VERSION "HNPBNNNYNNNNNNNNNNNNNNNNNNNNNNNNYNYYYYYYYY>4>%%%/4>'%**4YYY///"

NS_ :

BS_:

BU_: TPM TCM SCCM RF_HUB PTS ORC IC HaLF ETM ESM ESC EPS ECM Diagnost DTCM DASM CBC AFLS ADCM

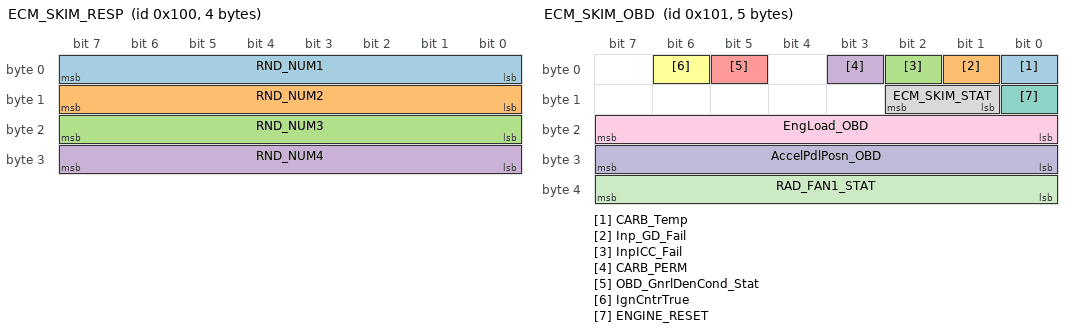
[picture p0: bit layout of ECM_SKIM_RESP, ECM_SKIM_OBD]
BO_ 256 ECM_SKIM_RESP: 4 ECM
 SG_ RND_NUM1 : 0|8@1+ (1,0) [0|0] ""  RF_HUB
 SG_ RND_NUM2 : 8|8@1+ (1,0) [0|0] ""  RF_HUB
 SG_ RND_NUM3 : 16|8@1+ (1,0) [0|0] ""  RF_HUB
 SG_ RND_NUM4 : 24|8@1+ (1,0) [0|0] ""  RF_HUB

BO_ 257 ECM_SKIM_OBD: 5 ECM
 SG_ CARB_Temp : 0|1@1+ (1,0) [0|0] ""  TCM,ECM
 SG_ Inp_GD_Fail : 1|1@1+ (1,0) [0|0] ""  TCM,ECM
 SG_ InpICC_Fail : 2|1@1+ (1,0) [0|0] ""  TCM,ECM
 SG_ CARB_PERM : 3|1@1+ (1,0) [0|0] ""  TCM
 SG_ OBD_GnrlDenCond_Stat : 5|1@1+ (1,0) [0|0] ""  TCM,ECM
 SG_ IgnCntrTrue : 6|1@1+ (1,0) [0|0] ""  TCM,ECM
 SG_ ENGINE_RESET : 8|1@1+ (1,0) [0|0] ""  RF_HUB
 SG_ ECM_SKIM_STAT : 9|2@1+ (1,0) [0|0] ""  RF_HUB
 SG_ EngLoad_OBD : 16|8@1+ (0.3922,0) [0|100] "%"  TCM,ECM
 SG_ AccelPdlPosn_OBD : 24|8@1+ (0.3922,0) [0|100] "%"  TCM,ECM
 SG_ RAD_FAN1_STAT : 32|8@1+ (1,0) [0|100] "%"  ETM,ECM

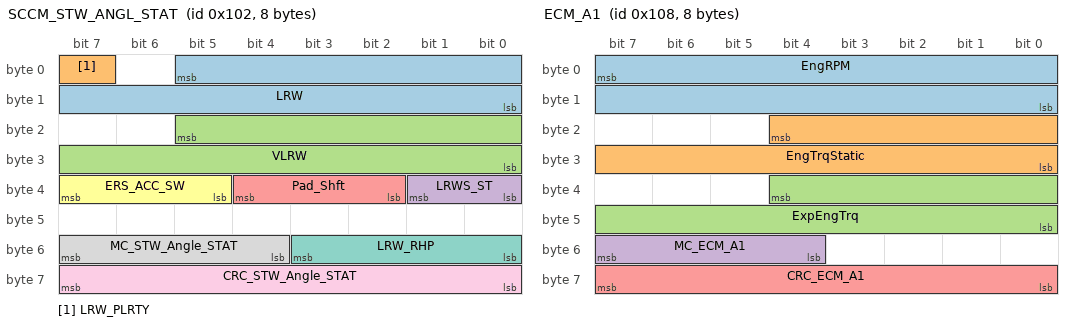
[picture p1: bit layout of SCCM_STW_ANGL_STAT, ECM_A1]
BO_ 258 SCCM_STW_ANGL_STAT: 8 SCCM
 SG_ LRW : 5|14@0+ (0.5,-2048) [-2048|2047] "Degrees"  HaLF,ORC,ADCM,DTCM,TCM,ECM,DASM,ESC,EPS,AFLS,PTS,IC,CBC
 SG_ LRW_PLRTY : 7|1@1+ (1,0) [0|0] ""  ETM,HaLF,ORC,ECM,DASM,ESC,AFLS,IC
 SG_ VLRW : 21|14@0+ (0.5,-2048) [-2048|2047] "°/s"  ETM,HaLF,ORC,ADCM,DTCM,ECM,DASM,ESC,EPS,AFLS
 SG_ LRWS_ST : 32|2@1+ (1,0) [0|0] ""  ETM,HaLF,ORC,ADCM,DTCM,ECM,DASM,ESC,AFLS,CBC
 SG_ Pad_Shft : 34|3@1+ (1,0) [0|0] ""  ETM,TCM,ECM
 SG_ ERS_ACC_SW : 37|3@1+ (1,0) [0|0] ""  TCM
 SG_ LRW_RHP : 48|4@1+ (0.1,-0.4) [-0.4|0.4] "Degrees"  ETM,ECM,EPS
 SG_ MC_STW_Angle_STAT : 52|4@1+ (1,0) [0|15] ""  ETM,ORC,ECM,DASM,ESC
 SG_ CRC_STW_Angle_STAT : 56|8@1+ (1,0) [0|0] ""  ETM,ORC,ECM,DASM,ESC

BO_ 264 ECM_A1: 8 ECM
 SG_ EngRPM : 7|16@0+ (1,0) [0|65534] "rpm"  HaLF,ORC,ADCM,DTCM,TCM,ECM,DASM,ESC,EPS,AFLS,TPM,PTS,IC,CBC,RF_HUB
 SG_ EngTrqStatic : 20|13@0+ (0.25,-500) [-500|1547.5] "Nm"  ADCM,DTCM,TCM,ECM,DASM,ESC,IC,CBC
 SG_ ExpEngTrq : 36|13@0+ (0.25,-500) [-500|1547.5] "Nm"  TCM,DASM,ESC
 SG_ MC_ECM_A1 : 52|4@1+ (1,0) [0|15] ""  HaLF,TCM,DASM,ESC
 SG_ CRC_ECM_A1 : 56|8@1+ (1,0) [0|0] ""  HaLF,TCM,DASM,ESC

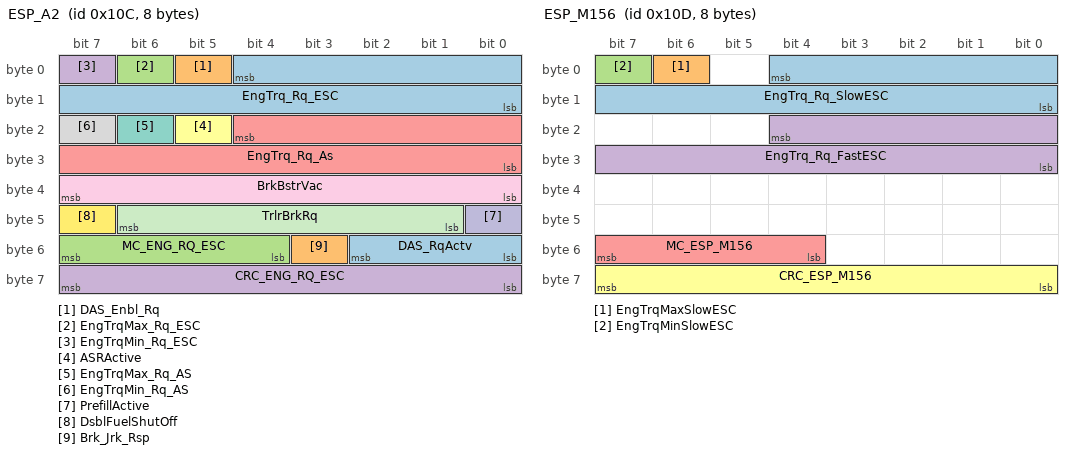
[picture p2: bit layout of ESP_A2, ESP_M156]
BO_ 268 ESP_A2: 8 ESC
 SG_ EngTrq_Rq_ESC : 4|13@0+ (0.25,-500) [-500|1547.5] "Nm"  ETM,ECM,DASM
 SG_ DAS_Enbl_Rq : 5|1@1+ (1,0) [0|0] ""  ORC,TCM,ECM,DASM
 SG_ EngTrqMax_Rq_ESC : 6|1@1+ (1,0) [0|0] ""  TCM,ECM
 SG_ EngTrqMin_Rq_ESC : 7|1@1+ (1,0) [0|0] ""  DTCM,TCM,ECM
 SG_ EngTrq_Rq_As : 20|13@0+ (0.25,-500) [-500|1547.5] "Nm"  ORC,TCM,ECM,DASM
 SG_ ASRActive : 21|1@1+ (1,0) [0|0] ""  ECM,DASM
 SG_ EngTrqMax_Rq_AS : 22|1@1+ (1,0) [0|0] ""  TCM,ECM,DASM
 SG_ EngTrqMin_Rq_AS : 23|1@1+ (1,0) [0|0] ""  TCM,ECM,DASM
 SG_ BrkBstrVac : 32|8@1+ (0.55,-119.7) [-119.7|20] "kPa"  ORC,ECM
 SG_ PrefillActive : 40|1@1+ (1,0) [0|0] ""  DASM
 SG_ TrlrBrkRq : 41|6@1+ (2,0) [0|100] "%" Vector__XXX
 SG_ DsblFuelShutOff : 47|1@1+ (1,0) [0|0] ""  ECM
 SG_ DAS_RqActv : 48|3@1+ (1,0) [0|0] ""  ORC,DASM
 SG_ Brk_Jrk_Rsp : 51|1@1+ (1,0) [0|0] ""  ORC,DASM
 SG_ MC_ENG_RQ_ESC : 52|4@1+ (1,0) [0|15] ""  TCM,ECM,DASM
 SG_ CRC_ENG_RQ_ESC : 56|8@1+ (1,0) [0|0] ""  TCM,ECM,DASM

BO_ 269 ESP_M156: 8 Vector__XXX
 SG_ EngTrq_Rq_SlowESC : 4|13@0+ (0.25,-500) [-500|1547.5] "Nm"  TCM
 SG_ EngTrqMaxSlowESC : 6|1@1+ (1,0) [0|0] ""  TCM
 SG_ EngTrqMinSlowESC : 7|1@1+ (1,0) [0|0] ""  TCM
 SG_ EngTrq_Rq_FastESC : 20|13@0+ (0.25,-500) [-500|1547.5] "Nm"  TCM
 SG_ MC_ESP_M156 : 52|4@1+ (1,0) [0|15] ""  TCM
 SG_ CRC_ESP_M156 : 56|8@1+ (1,0) [0|0] ""  TCM

BO_ 272 SKIM_110h: 6 RF_HUB
 SG_ SEED_REQUEST : 0|1@1+ (1,0) [0|0] ""  ECM

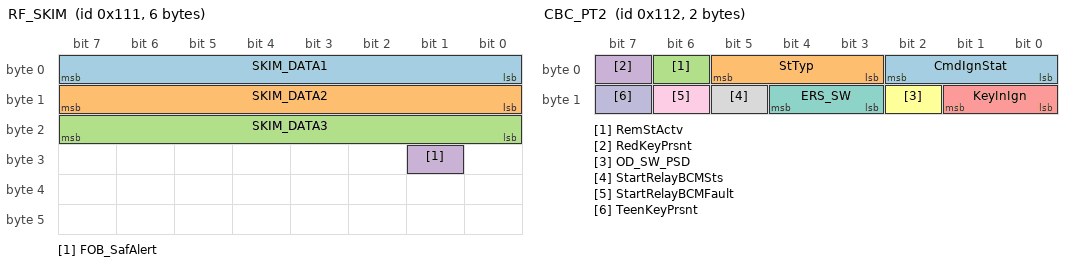
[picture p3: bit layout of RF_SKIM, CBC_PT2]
BO_ 273 RF_SKIM: 6 RF_HUB
 SG_ SKIM_DATA1 : 0|8@1+ (1,0) [0|0] ""  ECM
 SG_ SKIM_DATA2 : 8|8@1+ (1,0) [0|0] ""  ECM
 SG_ SKIM_DATA3 : 16|8@1+ (1,0) [0|0] ""  ECM
 SG_ FOB_SafAlert : 25|1@1+ (1,0) [0|0] ""  CBC

BO_ 274 CBC_PT2: 2 CBC
 SG_ CmdIgnStat : 0|3@1+ (1,0) [0|0] ""  HaLF,ORC,ADCM,DTCM,ESM,TCM,ECM,DASM,ESC,SCCM,EPS,AFLS,TPM,PTS,IC,RF_HUB
 SG_ StTyp : 3|3@1+ (1,0) [0|0] ""  ORC,DTCM,ECM,SCCM,TPM,PTS,IC,RF_HUB
 SG_ RemStActv : 6|1@1+ (1,0) [0|0] ""  ORC,DTCM,ESM,TCM,ECM,SCCM,TPM,PTS,IC,RF_HUB
 SG_ RedKeyPrsnt : 7|1@1+ (1,0) [0|0] ""  ETM,ECM
 SG_ KeyInIgn : 8|2@1+ (1,0) [0|0] ""  ORC,SCCM,TPM,PTS,IC,RF_HUB
 SG_ OD_SW_PSD : 10|1@1+ (1,0) [0|0] ""  TCM,ECM,PTS
 SG_ ERS_SW : 11|2@1+ (1,0) [0|0] ""  ECM
 SG_ StartRelayBCMSts : 13|1@1+ (1,0) [0|0] ""  ECM
 SG_ StartRelayBCMFault : 14|1@1+ (1,0) [0|0] ""  ORC,ECM
 SG_ TeenKeyPrsnt : 15|1@1+ (1,0) [0|0] ""  ETM,ECM

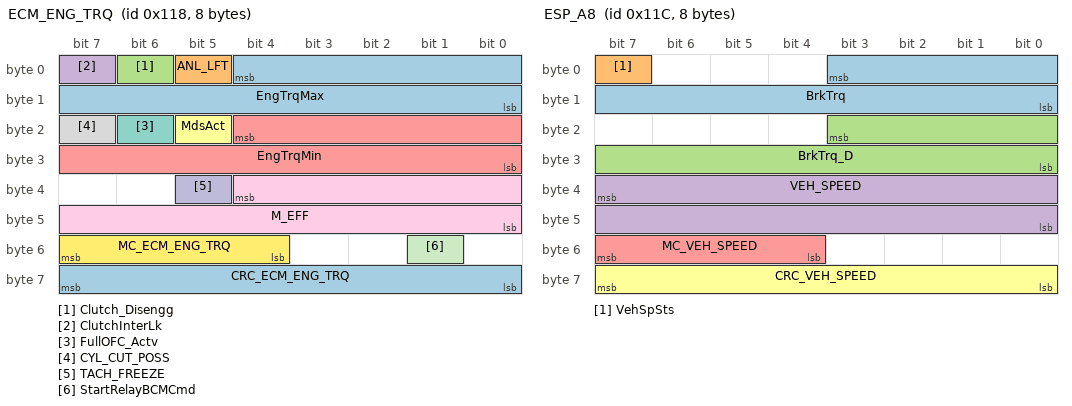
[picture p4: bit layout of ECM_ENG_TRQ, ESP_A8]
BO_ 280 ECM_ENG_TRQ: 8 ECM
 SG_ EngTrqMax : 4|13@0+ (0.25,-500) [-500|1547.5] "Nm"  DTCM,TCM,DASM,ESC,IC
 SG_ ANL_LFT : 5|1@1+ (1,0) [0|0] ""  TCM,CBC
 SG_ Clutch_Disengg : 6|1@1+ (1,0) [0|0] ""  ORC,ESC,PTS,CBC
 SG_ ClutchInterLk : 7|1@1+ (1,0) [0|0] ""  ORC,DTCM,ESC,RF_HUB
 SG_ EngTrqMin : 20|13@0+ (0.25,-500) [-500|1547.5] "Nm"  DTCM,TCM,DASM,ESC,IC
 SG_ MdsAct : 21|1@1+ (1,0) [0|0] ""  TCM,IC
 SG_ FullOFC_Actv : 22|1@1+ (1,0) [0|0] ""  DASM,ESC,CBC
 SG_ CYL_CUT_POSS : 23|1@1+ (1,0) [0|0] "" Vector__XXX
 SG_ M_EFF : 36|13@0+ (0.25,-500) [-500|1547.5] "Nm" Vector__XXX
 SG_ TACH_FREEZE : 37|1@1+ (1,0) [0|0] ""  IC
 SG_ StartRelayBCMCmd : 49|1@1+ (1,0) [0|0] ""  CBC
 SG_ MC_ECM_ENG_TRQ : 52|4@1+ (1,0) [0|15] ""  ESC
 SG_ CRC_ECM_ENG_TRQ : 56|8@1+ (1,0) [0|0] ""  DASM,ESC

BO_ 284 ESP_A8: 8 ESC
 SG_ BrkTrq : 3|12@0+ (3,0) [0|12282] "Nm"  ADCM,TCM,ECM,DASM,CBC,RF_HUB
 SG_ VehSpSts : 7|1@1+ (1,0) [0|0] ""  DASM
 SG_ BrkTrq_D : 19|12@0+ (3,0) [0|12282] "Nm"  ADCM,ECM,DASM,RF_HUB
 SG_ VEH_SPEED : 39|16@0+ (0.0078125,0) [0|511.984375] "km/h"  HaLF,ORC,ADCM,DTCM,ESM,TCM,ECM,DASM,EPS,AFLS,TPM,PTS,IC,CBC,RF_HUB
 SG_ MC_VEH_SPEED : 52|4@1+ (1,0) [0|15] ""  EPS,HaLF,ORC,ESM,TCM,ECM,DASM,TPM,PTS,IC,CBC,RF_HUB
 SG_ CRC_VEH_SPEED : 56|8@1+ (1,0) [0|0] ""  EPS,HaLF,ORC,ESM,TCM,ECM,DASM,TPM,PTS,IC,CBC,RF_HUB

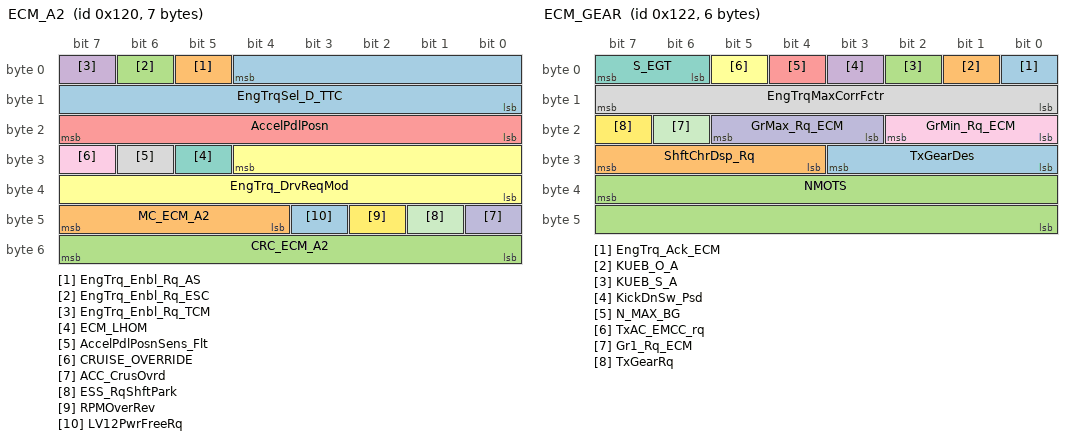
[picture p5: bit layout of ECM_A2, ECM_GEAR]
BO_ 288 ECM_A2: 7 ECM
 SG_ EngTrqSel_D_TTC : 4|13@0+ (0.25,-500) [-500|1547.5] "Nm"  TCM,DASM,ESC
 SG_ EngTrq_Enbl_Rq_AS : 5|1@1+ (1,0) [0|0] ""  TCM,DASM,ESC
 SG_ EngTrq_Enbl_Rq_ESC : 6|1@1+ (1,0) [0|0] ""  TCM,DASM,ESC
 SG_ EngTrq_Enbl_Rq_TCM : 7|1@1+ (1,0) [0|0] ""  TCM
 SG_ AccelPdlPosn : 16|8@1+ (0.4,0) [0|100] "%"  ETM,HaLF,ADCM,DTCM,TCM,ECM,DASM,ESC,AFLS,CBC
 SG_ EngTrq_DrvReqMod : 28|13@0+ (0.25,-500) [-500|1547.5] "Nm"  TCM,ECM,ESC
 SG_ ECM_LHOM : 29|1@1+ (1,0) [0|0] ""  TCM
 SG_ AccelPdlPosnSens_Flt : 30|1@1+ (1,0) [0|0] ""  HaLF,TCM,DASM,ESC,CBC
 SG_ CRUISE_OVERRIDE : 31|1@1+ (1,0) [0|0] ""  TCM,ECM,DASM,ESC,IC
 SG_ ACC_CrusOvrd : 40|1@1+ (1,0) [0|0] ""  DASM,ESC
 SG_ ESS_RqShftPark : 41|1@1+ (1,0) [0|0] ""  TCM
 SG_ RPMOverRev : 42|1@1+ (1,0) [0|0] ""  DASM
 SG_ LV12PwrFreeRq : 43|1@1+ (1,0) [0|0] ""  TCM,DASM,ESC
 SG_ MC_ECM_A2 : 44|4@1+ (1,0) [0|15] ""  HaLF,TCM,DASM,ESC
 SG_ CRC_ECM_A2 : 48|8@1+ (1,0) [0|0] ""  HaLF,TCM,DASM,ESC

BO_ 290 ECM_GEAR: 6 ECM
 SG_ EngTrq_Ack_ECM : 0|1@1+ (1,0) [0|0] "" Vector__XXX
 SG_ KUEB_O_A : 1|1@1+ (1,0) [0|0] "" Vector__XXX
 SG_ KUEB_S_A : 2|1@1+ (1,0) [0|0] "" Vector__XXX
 SG_ KickDnSw_Psd : 3|1@1+ (1,0) [0|0] ""  TCM,DASM,ESC
 SG_ N_MAX_BG : 4|1@1+ (1,0) [0|0] "" Vector__XXX
 SG_ TxAC_EMCC_rq : 5|1@1+ (1,0) [0|0] ""  TCM
 SG_ S_EGT : 6|2@1+ (1,0) [0|0] "" Vector__XXX
 SG_ EngTrqMaxCorrFctr : 8|8@1+ (0.0078,0) [0|1.98] "Nm"  TCM,DASM
 SG_ GrMin_Rq_ECM : 16|3@1+ (1,0) [0|0] ""  TCM,ECM
 SG_ GrMax_Rq_ECM : 19|3@1+ (1,0) [0|0] ""  TCM
 SG_ Gr1_Rq_ECM : 22|1@1+ (1,0) [0|0] "" Vector__XXX
 SG_ TxGearRq : 23|1@1+ (1,0) [0|0] "" Vector__XXX
 SG_ TxGearDes : 24|4@1+ (1,0) [0|0] "" Vector__XXX
 SG_ ShftChrDsp_Rq : 28|4@1+ (1,0) [0|0] ""  ECM
 SG_ NMOTS : 39|16@0+ (1,0) [0|65534] "rpm"  TCM,ESC

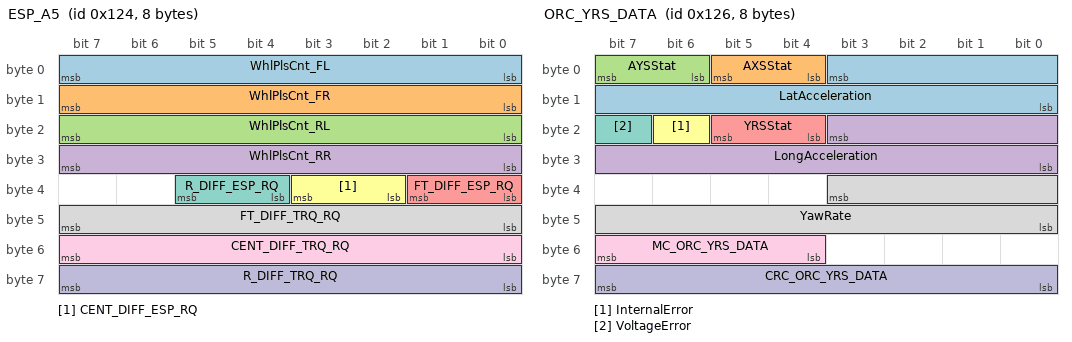
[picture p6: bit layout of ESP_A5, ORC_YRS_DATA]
BO_ 292 ESP_A5: 8 ESC
 SG_ WhlPlsCnt_FL : 0|8@1+ (1,0) [0|254] "Impulse"  DASM,EPS,TPM,IC,CBC,RF_HUB
 SG_ WhlPlsCnt_FR : 8|8@1+ (1,0) [0|254] "Impulse"  DASM,EPS,TPM,IC,CBC,RF_HUB
 SG_ WhlPlsCnt_RL : 16|8@1+ (1,0) [0|254] "Impulse"  DASM,EPS,TPM,IC,CBC,RF_HUB
 SG_ WhlPlsCnt_RR : 24|8@1+ (1,0) [0|254] "Impulse"  DASM,EPS,TPM,IC,CBC,RF_HUB
 SG_ FT_DIFF_ESP_RQ : 32|2@1+ (1,0) [0|0] "" Vector__XXX
 SG_ CENT_DIFF_ESP_RQ : 34|2@1+ (1,0) [0|0] ""  DTCM
 SG_ R_DIFF_ESP_RQ : 36|2@1+ (1,0) [0|0] "" Vector__XXX
 SG_ FT_DIFF_TRQ_RQ : 40|8@1+ (10,0) [0|2540] "Nm" Vector__XXX
 SG_ CENT_DIFF_TRQ_RQ : 48|8@1+ (10,0) [0|2540] "Nm"  DTCM
 SG_ R_DIFF_TRQ_RQ : 56|8@1+ (10,0) [0|2540] "Nm" Vector__XXX

BO_ 294 ORC_YRS_DATA: 8 Vector__XXX
 SG_ LatAcceleration : 3|12@0+ (0.02,-40.96) [-40.96|40.92] "m/s²"  ESC
 SG_ AXSStat : 4|2@1+ (1,0) [0|0] ""  ECM,ESC
 SG_ AYSStat : 6|2@1+ (1,0) [0|0] ""  ESC
 SG_ LongAcceleration : 19|12@0+ (0.02,-40.96) [-40.96|40.92] "m/s²"  EPS,ECM,ESC
 SG_ YRSStat : 20|2@1+ (1,0) [0|0] ""  ESC
 SG_ InternalError : 22|1@1+ (1,0) [0|0] ""  ESC
 SG_ VoltageError : 23|1@1+ (1,0) [0|0] ""  ESC
 SG_ YawRate : 35|12@0+ (0.08,-163.84) [-163.84|163.68] "°/s"  ESC
 SG_ MC_ORC_YRS_DATA : 52|4@1+ (1,0) [0|15] ""  ESC
 SG_ CRC_ORC_YRS_DATA : 56|8@1+ (1,0) [0|0] ""  ESC

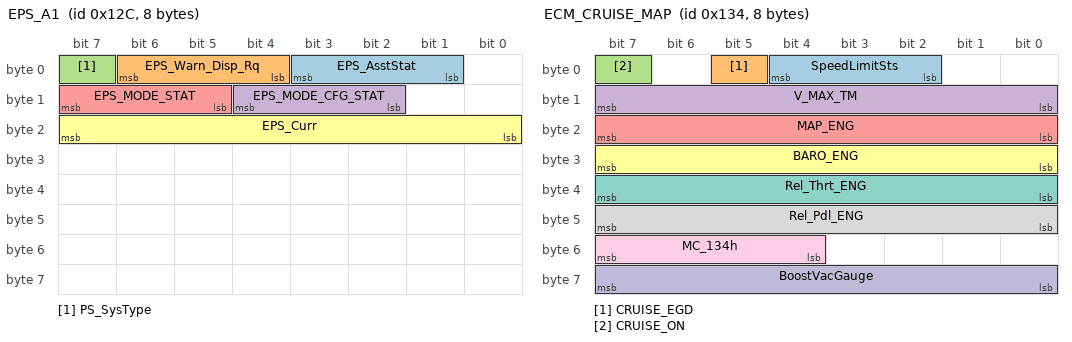
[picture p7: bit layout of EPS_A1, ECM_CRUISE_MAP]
BO_ 300 EPS_A1: 8 EPS
 SG_ EPS_AsstStat : 1|3@1+ (1,0) [0|0] ""  ORC,ECM,ESC,IC
 SG_ EPS_Warn_Disp_Rq : 4|3@1+ (1,0) [0|0] ""  ORC,ECM,ESC,IC,CBC
 SG_ PS_SysType : 7|1@1+ (1,0) [0|0] ""  ESC,IC,CBC
 SG_ EPS_MODE_CFG_STAT : 10|3@1+ (1,0) [0|0] ""  CBC
 SG_ EPS_MODE_STAT : 13|3@1+ (1,0) [0|0] ""  CBC
 SG_ EPS_Curr : 16|8@1+ (1,-50) [-50|204] "Amp"  ECM

BO_ 308 ECM_CRUISE_MAP: 8 ECM
 SG_ SpeedLimitSts : 2|3@1+ (1,0) [0|0] ""  IC
 SG_ CRUISE_EGD : 5|1@1+ (1,0) [0|0] ""  ORC,TCM,ECM,ESC,IC,CBC
 SG_ CRUISE_ON : 7|1@1+ (1,0) [0|0] ""  ORC,TCM,ESC,SCCM,IC
 SG_ V_MAX_TM : 8|8@1+ (1,0) [0|250] "km/h(mph)"  TCM,ECM
 SG_ MAP_ENG : 16|8@1+ (0.8,0) [0|203.2] "kPa"  ETM,ECM,ESC
 SG_ BARO_ENG : 24|8@1+ (1,0) [0|254] "kPaA"  ETM,ESC
 SG_ Rel_Thrt_ENG : 32|8@1+ (0.019607843,0) [0|4.98] "Volts"  ESC
 SG_ Rel_Pdl_ENG : 40|8@1+ (0.019607843,0) [0|4.98] "Volts"  ESC
 SG_ MC_134h : 52|4@1+ (1,0) [0|15] ""  ESC
 SG_ BoostVacGauge : 56|8@1+ (1,-100) [-100|150] "kPa"  IC,CBC

BO_ 320 ESP_A1: 8 ESC
 SG_ Brk_Stat : 0|2@1+ (1,0) [0|0] ""  ORC,ECM,DASM,AFLS,PTS,CBC
 SG_ BrkPdl_Stat : 2|2@1+ (1,0) [0|0] ""  ETM,HaLF,ORC,DTCM,TCM,ECM,DASM,AFLS,IC,CBC,RF_HUB
 SG_ BrkPdl_Flt : 4|1@1+ (1,0) [0|0] ""  HaLF,ECM,DASM
 SG_ BrkIntrvntn_Actv_ESP : 5|1@1+ (1,0) [0|0] ""  ORC,DTCM,TCM,ECM,DASM
 SG_ BrkIntrvntn_Actv_AS : 6|1@1+ (1,0) [0|0] ""  ORC,TCM,ECM,DASM
 SG_ BrkIntrvntn_Enbl : 7|1@1+ (1,0) [0|0] ""  ORC,TCM,ECM,DASM
 SG_ EmgBrk_Actv : 8|1@1+ (1,0) [0|0] ""  ORC,ECM,DASM,CBC
 SG_ FullBrk_Actv : 9|1@1+ (1,0) [0|0] ""  ORC,ECM,DASM,PTS,IC,CBC
 SG_ ESP_Sys_Stat : 10|2@1+ (1,0) [0|0] ""  ORC,TCM,ECM,DASM,SCCM,IC
 SG_ SelSpdSts : 12|2@1+ (1,0) [0|0] ""  ETM,ORC,TCM,ECM,IC,CBC
 SG_ ABS_BrkEvt : 14|1@1+ (1,0) [0|0] ""  ETM,ORC,ADCM,DTCM,TCM,ECM,DASM
 SG_ DTR_CC_Engaged : 15|1@1+ (1,0) [0|0] ""  ORC,TCM,ECM
 SG_ GrMin_Rq_ESC : 16|3@1+ (1,0) [0|0] ""  TCM,ECM
 SG_ GrMax_Rq_ESC : 19|3@1+ (1,0) [0|0] ""  TCM,ECM
 SG_ GrMinMax_Rq_DTR : 22|1@1+ (1,0) [0|0] ""  ORC,ECM
 SG_ DTR_CC_Enabled : 23|1@1+ (1,0) [0|0] ""  TCM,ECM
 SG_ Brk_Thermdl : 25|1@1+ (1,0) [0|0] ""  DASM
 SG_ ShftChrDsp_Rq_ESC : 26|4@1+ (1,0) [0|0] ""  TCM,ECM,DASM
 SG_ RollTestMd_Actv : 30|2@1+ (1,0) [0|0] ""  DTCM,ECM,DASM
 SG_ REF_VEH_SPEED : 33|10@0+ (0.5,0) [0|511] "km/h"  ORC,TCM,ECM,IC
 SG_ SPCR_AS_Off_Rq : 38|2@1+ (1,0) [0|0] ""  ECM,DASM
 SG_ MC_Brk_Stat : 52|4@1+ (1,0) [0|15] ""  HaLF,ORC,TCM,ECM,DASM,IC
 SG_ CRC_Brk_Stat : 56|8@1+ (1,0) [0|0] ""  HaLF,ORC,TCM,ECM,DASM,IC

BO_ 324 TRNS_SPD: 8 ECM
 SG_ K_STO_B : 0|1@1+ (1,0) [0|0] ""  ECM
 SG_ Ups_Inh_Act : 1|1@1+ (1,0) [0|0] ""  ECM
 SG_ GearSwitchActiveSts : 2|1@1+ (1,0) [0|0] "" Vector__XXX
 SG_ OD_OFF : 3|1@1+ (1,0) [0|0] ""  IC
 SG_ DrvRst_Hi : 4|1@1+ (1,0) [0|0] ""  ECM
 SG_ EngSt_Enbl_Rq_TCM : 5|1@1+ (1,0) [0|0] ""  ECM,CBC,RF_HUB
 SG_ AUTO_STK_EGD : 6|1@1+ (1,0) [0|0] ""  DTCM,ECM,IC
 SG_ BasShftProg_Ok : 7|1@1+ (1,0) [0|0] ""  ECM
 SG_ Gr : 8|4@1+ (1,0) [0|0] ""  EPS,ORC,DTCM,ECM,DASM,ESC,IC,CBC
 SG_ Gr_Target : 12|4@1+ (1,0) [0|0] ""  ETM,ECM,DASM,ESC,CBC
 SG_ KS : 16|1@1+ (1,0) [0|0] ""  ECM
 SG_ K_G_B : 17|1@1+ (1,0) [0|0] ""  ECM
 SG_ K_O_B : 18|1@1+ (1,0) [0|0] ""  ECM
 SG_ K_S_B : 19|1@1+ (1,0) [0|0] ""  ECM
 SG_ Trns_EMCC_Achvd : 20|1@1+ (1,0) [0|0] ""  ECM
 SG_ AntiJerkDsbl : 21|1@1+ (1,0) [0|0] ""  ECM
 SG_ EngBrkCanRq : 22|1@1+ (1,0) [0|0] "" Vector__XXX
 SG_ PTO_Enbl : 23|1@1+ (1,0) [0|0] ""  ECM
 SG_ OUTPUT_SPEED : 31|16@0+ (1,0) [0|65534] "rpm"  DTCM,ECM,ESC,CBC
 SG_ N_Turb : 47|16@0+ (1,0) [0|65534] "rpm"  ECM
 SG_ OutputSpdPolarity : 56|2@1+ (1,0) [0|0] ""  ECM,ESC
 SG_ Gear_Pkt_Parity : 59|1@1+ (1,0) [0|0] ""  DASM
 SG_ Gear_Pkt_Counter : 60|2@1+ (1,0) [0|3] "decimal"  DASM
 SG_ TCM_TmpManMd : 62|1@1+ (1,0) [0|0] ""  ESM,IC
 SG_ TCM_ManMd : 63|1@1+ (1,0) [0|0] ""  ESM,IC,CBC

BO_ 328 ESM_A1: 1 Vector__XXX
 SG_ WHC : 0|4@1+ (1,0) [0|0] ""  ECM,IC,CBC

BO_ 329 ESM_MS1: 5 Vector__XXX
 SG_ Shft_Warn : 8|3@1+ (1,0) [0|0] ""  IC

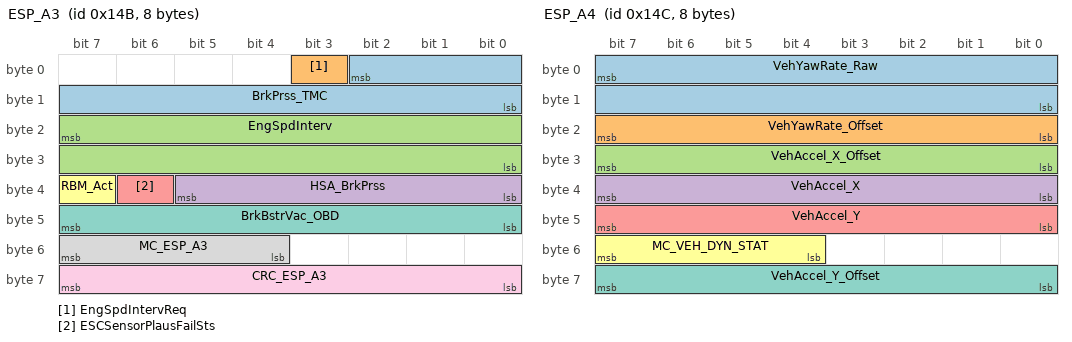
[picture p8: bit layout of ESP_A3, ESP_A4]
BO_ 331 ESP_A3: 8 ESC
 SG_ BrkPrss_TMC : 2|11@0+ (0.1,0) [0|200] "bar"  ETM,ORC,TCM,ECM
 SG_ EngSpdIntervReq : 3|1@1+ (1,0) [0|0] ""  ECM
 SG_ EngSpdInterv : 23|16@0+ (1,0) [0|65534] "rpm"  ECM
 SG_ HSA_BrkPrss : 32|6@1+ (1,0) [0|50] "bar"  ETM,ORC,ECM
 SG_ ESCSensorPlausFailSts : 38|1@1+ (1,0) [0|0] ""  ORC
 SG_ RBM_Act : 39|1@1+ (1,0) [0|0] ""  ECM
 SG_ BrkBstrVac_OBD : 40|8@1+ (0.019607843,0) [0|5] "Volts"  ECM
 SG_ MC_ESP_A3 : 52|4@1+ (1,0) [0|15] ""  ORC,TCM,ECM
 SG_ CRC_ESP_A3 : 56|8@1+ (1,0) [0|0] ""  ORC,TCM,ECM

BO_ 332 ESP_A4: 8 ESC
 SG_ VehYawRate_Raw : 7|16@0+ (0.01,-327.68) [-327.68|327.66] "°/s"  HaLF,ORC,DTCM,DASM,AFLS,CBC
 SG_ VehYawRate_Offset : 16|8@1+ (0.08,-10.24) [-6.96|6.96] ""  ETM,HaLF,ORC,DTCM,DASM,AFLS,PTS,CBC
 SG_ VehAccel_X_Offset : 24|8@1+ (0.02,-2.56) [-2.56|2.52] "m/s²"  ETM,ORC,DTCM,ECM,DASM,AFLS
 SG_ VehAccel_X : 32|8@1+ (0.08,-10.24) [-10.24|10.08] "m/s²"  EPS,ORC,DTCM,TCM,ECM,DASM,AFLS,IC,CBC
 SG_ VehAccel_Y : 40|8@1+ (0.08,-10.24) [-10.24|10.08] "m/s²"  ORC,ADCM,DTCM,TCM,ECM,DASM,EPS,AFLS,IC,CBC
 SG_ MC_VEH_DYN_STAT : 52|4@1+ (1,0) [0|15] ""  ETM,HaLF,ORC,ECM,DASM,AFLS
 SG_ VehAccel_Y_Offset : 56|8@1+ (0.02,-2.56) [-2.56|2.52] "m/s²"  ETM,ORC,DTCM,DASM,AFLS

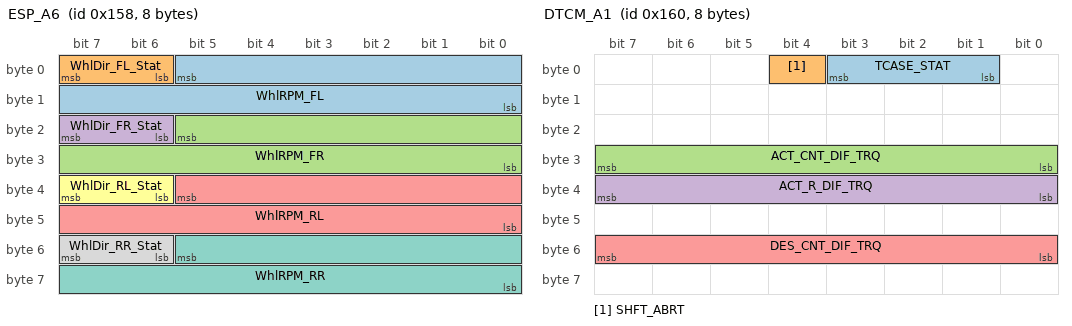
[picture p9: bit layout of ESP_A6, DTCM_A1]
BO_ 344 ESP_A6: 8 ESC
 SG_ WhlRPM_FL : 5|14@0+ (0.5,0) [0|8191] "rpm"  ORC,DTCM,TCM,ECM,DASM,EPS
 SG_ WhlDir_FL_Stat : 6|2@1+ (1,0) [0|0] ""  ORC,DASM
 SG_ WhlRPM_FR : 21|14@0+ (0.5,0) [0|8191] "rpm"  ORC,DTCM,TCM,ECM,DASM,EPS
 SG_ WhlDir_FR_Stat : 22|2@1+ (1,0) [0|0] ""  ORC,DASM
 SG_ WhlRPM_RL : 37|14@0+ (0.5,0) [0|8191] "rpm"  ORC,DTCM,TCM,ECM,DASM,EPS,CBC
 SG_ WhlDir_RL_Stat : 38|2@1+ (1,0) [0|0] ""  EPS,ORC,DASM
 SG_ WhlRPM_RR : 53|14@0+ (0.5,0) [0|8191] "rpm"  ORC,DTCM,TCM,ECM,DASM,EPS,CBC
 SG_ WhlDir_RR_Stat : 54|2@1+ (1,0) [0|0] ""  EPS,ORC,DASM

BO_ 352 DTCM_A1: 8 CBC
 SG_ TCASE_STAT : 1|3@1+ (1,0) [0|0] ""  ETM,ORC,TCM,ECM,DASM,ESC,PTS,IC,CBC,RF_HUB
 SG_ SHFT_ABRT : 4|1@1+ (1,0) [0|0] "" Vector__XXX
 SG_ ACT_CNT_DIF_TRQ : 24|8@1+ (10,0) [0|2540] "Nm"  ETM,ESC,CBC
 SG_ ACT_R_DIF_TRQ : 32|8@1+ (10,0) [0|2540] "Nm"  ETM,ESC,IC,CBC
 SG_ DES_CNT_DIF_TRQ : 48|8@1+ (10,0) [0|2540] "Nm"  ESC

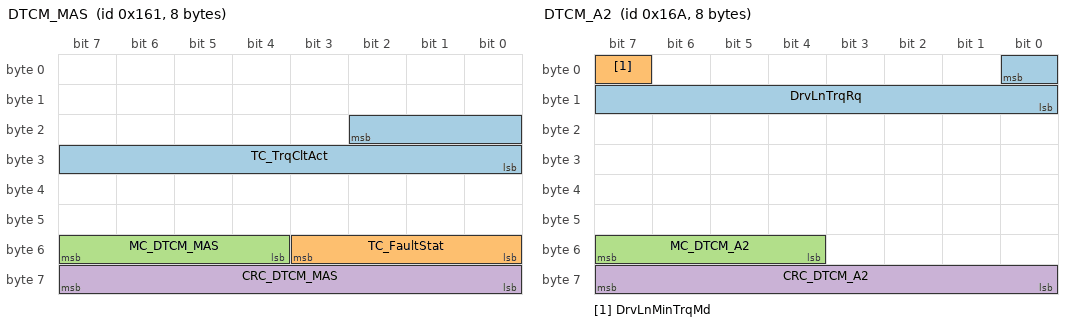
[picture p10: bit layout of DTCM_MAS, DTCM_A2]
BO_ 353 DTCM_MAS: 8 Vector__XXX
 SG_ TC_TrqCltAct : 18|11@0+ (1,0) [0|2046] "Nm"  TCM,ECM
 SG_ TC_FaultStat : 48|4@1+ (1,0) [0|0] ""  TCM,ECM,CBC
 SG_ MC_DTCM_MAS : 52|4@1+ (1,0) [0|15] ""  TCM,ECM
 SG_ CRC_DTCM_MAS : 56|8@1+ (1,0) [0|0] ""  TCM,ECM

BO_ 362 DTCM_A2: 8 DTCM
 SG_ DrvLnTrqRq : 0|9@0+ (2,0) [0|1020] "Nm"  ECM
 SG_ DrvLnMinTrqMd : 7|1@1+ (1,0) [0|0] ""  ECM
 SG_ MC_DTCM_A2 : 52|4@1+ (1,0) [0|15] ""  ECM
 SG_ CRC_DTCM_A2 : 56|8@1+ (1,0) [0|0] ""  ECM

CM_ "XDIS NWC Export: PN_CAN_C_1313 [15],UUID 383B7746866B11E283C96431509E4BEC, RELEASED 2013-03-27 EDT-16:36:01";
CM_ SG_ 256 RND_NUM1 "Random number to Skim 1";
CM_ SG_ 256 RND_NUM2 "Random number to Skim 2";
CM_ SG_ 256 RND_NUM3 "Random number to Skim 3";
CM_ SG_ 256 RND_NUM4 "Random number to Skim 4";
CM_ SG_ 257 CARB_Temp "CARB warmup criteria is true [1]";
CM_ SG_ 257 Inp_GD_Fail "Inputs to the general denominator are in a pend or MIL fault.";
CM_ SG_ 257 InpICC_Fail "Inputs to the Ign Cycle Cntr are in a Pend or MIL cond.";
CM_ SG_ 257 CARB_PERM "CARB permanent fault code drive cycle";
CM_ SG_ 257 OBD_GnrlDenCond_Stat "General denominator conditions are met [1].";
CM_ SG_ 257 IgnCntrTrue "Ignition cycle counter is true [1]";
CM_ SG_ 257 ENGINE_RESET "ECM Reset Notification";
CM_ SG_ 257 ECM_SKIM_STAT "ECM Skim Status";
CM_ SG_ 257 EngLoad_OBD "Load value for OBD (ISO 15031-5.4 PID 4)";
CM_ SG_ 257 AccelPdlPosn_OBD "Pedal value for OBD (ISO 15031-5.4 PID 49)";
CM_ SG_ 257 RAD_FAN1_STAT "Low speed or single radiator fan requested duty cycle";
CM_ SG_ 258 LRW "Steering wheel angle";
CM_ SG_ 258 LRW_PLRTY "Steering angle polarity (0=ISO 8855 Polarity and CCW = Positive)";
CM_ SG_ 258 VLRW "Delta steering wheel angle";
CM_ SG_ 258 LRWS_ST "Steering wheel angle sensor status";
CM_ SG_ 258 Pad_Shft "Paddle Shift";
CM_ SG_ 258 ERS_ACC_SW "ERS/ACC steering wheel switch";
CM_ SG_ 258 LRW_RHP "Steering wheel angle remainder high precision";
CM_ SG_ 258 MC_STW_Angle_STAT "Message counter";
CM_ SG_ 258 CRC_STW_Angle_STAT "CRC-checksum byte 1 to 7 according to SAE J1850";
CM_ SG_ 264 EngRPM "Engine revolutions per minute";
CM_ SG_ 264 EngTrqStatic "Static engine torque / Effective engine torque";
CM_ SG_ 264 ExpEngTrq "Expected Engine Torque based on target engine speed";
CM_ SG_ 264 MC_ECM_A1 "Message counter";
CM_ SG_ 264 CRC_ECM_A1 "CRC-checksum byte 1 to 7 according to SAE J1850";
CM_ SG_ 268 EngTrq_Rq_ESC "Engine torque request";
CM_ SG_ 268 DAS_Enbl_Rq "Enable DAS request; True = [1]";
CM_ SG_ 268 EngTrqMax_Rq_ESC "Engine torque request maximum";
CM_ SG_ 268 EngTrqMin_Rq_ESC "Engine torque request minimum";
CM_ SG_ 268 EngTrq_Rq_As "Engine torque request";
CM_ SG_ 268 ASRActive "Traction control is active";
CM_ SG_ 268 EngTrqMax_Rq_AS "Engine torque request maximum; True = [1]";
CM_ SG_ 268 EngTrqMin_Rq_AS "Engine torque request minimum; True = [1]";
CM_ SG_ 268 BrkBstrVac "Brake Booster Vacuum Level";
CM_ SG_ 268 PrefillActive "Brake prefill is active - True = [1]";
CM_ SG_ 268 TrlrBrkRq "Trailor brake request percentage";
CM_ SG_ 268 DsblFuelShutOff "Disable fuel shutoff; True = [1]";
CM_ SG_ 268 DAS_RqActv "DAS request active";
CM_ SG_ 268 Brk_Jrk_Rsp "Brake jerk response; True = [1]";
CM_ SG_ 268 MC_ENG_RQ_ESC "Message counter";
CM_ SG_ 268 CRC_ENG_RQ_ESC "CRC-checksum byte 1 to 7 according to SAE J1850";
CM_ SG_ 269 EngTrq_Rq_SlowESC "Engine torque request";
CM_ SG_ 269 EngTrqMaxSlowESC "Engine torque request maximum - slow";
CM_ SG_ 269 EngTrqMinSlowESC "Engine torque request minimum - slow";
CM_ SG_ 269 EngTrq_Rq_FastESC "Engine torque request - fast";
CM_ SG_ 269 MC_ESP_M156 "Message counter";
CM_ SG_ 269 CRC_ESP_M156 "CRC-checksum byte 1 to 7 according to SAE J1850";
CM_ SG_ 272 SEED_REQUEST "SKIM seed request to ECM";
CM_ SG_ 273 SKIM_DATA1 "SKIM Encrypted Data Byte 1";
CM_ SG_ 273 SKIM_DATA2 "SKIM Encrypted Data Byte 2";
CM_ SG_ 273 SKIM_DATA3 "SKIM Encrypted Data Byte 3";
CM_ SG_ 273 FOB_SafAlert "Request to perform FOBIK-Safe alert (1=Perform alert)";
CM_ SG_ 274 CmdIgnStat "Commanded ignition switch status";
CM_ SG_ 274 StTyp "Type of start being requested";
CM_ SG_ 274 RemStActv "Ignition run active for remote start (0=not active, 1=active)";
CM_ SG_ 274 RedKeyPrsnt "Red key present; Present = [1]";
CM_ SG_ 274 KeyInIgn "Key in ignition status";
CM_ SG_ 274 OD_SW_PSD "Overdrive Switch Pressed; [0] = not pressed, [1] = pressed";
CM_ SG_ 274 ERS_SW "ERS Switch Status";
CM_ SG_ 274 StartRelayBCMSts "CBC starter relay status; [1] = ON";
CM_ SG_ 274 StartRelayBCMFault "CBC starter relay fault detected";
CM_ SG_ 274 TeenKeyPrsnt "Teen key present; Present = [1]";
CM_ SG_ 280 EngTrqMax "Maximum engine torque";
CM_ SG_ 280 ANL_LFT "Starter motor running (Cranking)";
CM_ SG_ 280 Clutch_Disengg "Clutch upstop position:  Upstop=[0]; partial=[1]";
CM_ SG_ 280 ClutchInterLk "Clutch interlock switch, clutch depressed = [0]";
CM_ SG_ 280 EngTrqMin "Minimum engine torque";
CM_ SG_ 280 MdsAct "MDS Active";
CM_ SG_ 280 FullOFC_Actv "Cylinder cut-out";
CM_ SG_ 280 CYL_CUT_POSS "Cylinder cut-out conditions fulfilled";
CM_ SG_ 280 M_EFF "Effective engine torque";
CM_ SG_ 280 TACH_FREEZE "Request tachometer to freeze";
CM_ SG_ 280 StartRelayBCMCmd "Engine restart request for StopStart function";
CM_ SG_ 280 MC_ECM_ENG_TRQ "Message counter";
CM_ SG_ 280 CRC_ECM_ENG_TRQ "CRC-checksum byte 1 to 7 according to SAE J1850";
CM_ SG_ 284 BrkTrq "Actual brake torque";
CM_ SG_ 284 VehSpSts "Vehicle is stopped status signal";
CM_ SG_ 284 BrkTrq_D "Brake torque requested by driver";
CM_ SG_ 284 VEH_SPEED "Vehicle speed";
CM_ SG_ 284 MC_VEH_SPEED "Message counter";
CM_ SG_ 284 CRC_VEH_SPEED "CRC-checksum byte 1 to 7 according to SAE J1850";
CM_ SG_ 288 EngTrqSel_D_TTC "Corrected (substitute) driver torque demand";
CM_ SG_ 288 EngTrq_Enbl_Rq_AS "Allow LCM torque requests";
CM_ SG_ 288 EngTrq_Enbl_Rq_ESC "Allow ESC torque request";
CM_ SG_ 288 EngTrq_Enbl_Rq_TCM "Allow TRANS torque request";
CM_ SG_ 288 AccelPdlPosn "Throttle Pedal Position (Calculated)";
CM_ SG_ 288 EngTrq_DrvReqMod "Driver requested engine torque modifed";
CM_ SG_ 288 ECM_LHOM "Engine in limp home mode";
CM_ SG_ 288 AccelPdlPosnSens_Flt "Accelerator pedal position sensor fault";
CM_ SG_ 288 CRUISE_OVERRIDE "Driver is over-riding cruise set speed";
CM_ SG_ 288 ACC_CrusOvrd "Adaptive cruise override by driver; True = [1]";
CM_ SG_ 288 ESS_RqShftPark "Stop start request - shift to park; true = [1]";
CM_ SG_ 288 RPMOverRev "RPM Overrev condition has occurred";
CM_ SG_ 288 LV12PwrFreeRq "Level 1 or 2 power free request - engine controller has depowered the throttle body";
CM_ SG_ 288 MC_ECM_A2 "Message counter";
CM_ SG_ 288 CRC_ECM_A2 "CRC-checksum byte 1 to 6 according to SAE J1850";
CM_ SG_ 290 EngTrq_Ack_ECM "Acknowledge TRANS torque request";
CM_ SG_ 290 KUEB_O_A "Request to disengage torque converter lock-up clutch (open)";
CM_ SG_ 290 KUEB_S_A "Increased torque converter slip is desired";
CM_ SG_ 290 KickDnSw_Psd "kick-down (change-over scenario open!)";
CM_ SG_ 290 N_MAX_BG "Rev Max achieved and rev limiter active";
CM_ SG_ 290 TxAC_EMCC_rq "Transmission  AC converter clutch slip request; [1] = True";
CM_ SG_ 290 S_EGT "DPF assistance request";
CM_ SG_ 290 EngTrqMaxCorrFctr "Factor of reduction from max. torque";
CM_ SG_ 290 GrMin_Rq_ECM "Target gear lower limit (ECM requested limit)";
CM_ SG_ 290 GrMax_Rq_ECM "Target gear upper limit (ECM requested limit)";
CM_ SG_ 290 Gr1_Rq_ECM "ECM request: 'Start off in 1st gear'";
CM_ SG_ 290 TxGearRq "Transmission gear request";
CM_ SG_ 290 TxGearDes "Transmission gear desired";
CM_ SG_ 290 ShftChrDsp_Rq "Shift characteristic displacement request";
CM_ SG_ 290 NMOTS "Target idle speed";
CM_ SG_ 292 WhlPlsCnt_FL "Wheel pulse counter front left (96 per rotation)";
CM_ SG_ 292 WhlPlsCnt_FR "Wheel pulse counter front right (96 per rotation)";
CM_ SG_ 292 WhlPlsCnt_RL "Wheel pulse counter rear left (96 per rotation)";
CM_ SG_ 292 WhlPlsCnt_RR "Wheel pulse counter rear right (96 per rotation)";
CM_ SG_ 292 FT_DIFF_ESP_RQ "ESP Requested Front Differential State";
CM_ SG_ 292 CENT_DIFF_ESP_RQ "ESP Requested Center  Differential State";
CM_ SG_ 292 R_DIFF_ESP_RQ "ESP Requested Rear Differential State";
CM_ SG_ 292 FT_DIFF_TRQ_RQ "Desired Torque for Front Diff";
CM_ SG_ 292 CENT_DIFF_TRQ_RQ "Desired Torque for Center Diff";
CM_ SG_ 292 R_DIFF_TRQ_RQ "Desired Torque for Rear Diff.";
CM_ SG_ 294 LatAcceleration "Raw lateral acceleration";
CM_ SG_ 294 AXSStat "Longitudinal signal status";
CM_ SG_ 294 AYSStat "Latitudinal signal status";
CM_ SG_ 294 LongAcceleration "Raw longitudinal acceleration";
CM_ SG_ 294 YRSStat "Yaw rate signal status";
CM_ SG_ 294 InternalError "ORC ESC internal error; True = [1]";
CM_ SG_ 294 VoltageError "ORC ESC voltage error; True = [1]";
CM_ SG_ 294 YawRate "Raw yaw acceleration";
CM_ SG_ 294 MC_ORC_YRS_DATA "Message counter";
CM_ SG_ 294 CRC_ORC_YRS_DATA "CRC-checksum byte 1 to 7 according to SAE J1850";
CM_ SG_ 300 EPS_AsstStat "Electric Power Steering Assistance Status";
CM_ SG_ 300 EPS_Warn_Disp_Rq "Electric power steering warning display request";
CM_ SG_ 300 PS_SysType "Power steering system type; EHPS = [0]: EPS = [1]";
CM_ SG_ 300 EPS_MODE_CFG_STAT "Config setting - EPS personalization mode";
CM_ SG_ 300 EPS_MODE_STAT "EPS mode personalization status";
CM_ SG_ 300 EPS_Curr "Electric power steering current";
CM_ SG_ 308 SpeedLimitSts "Speed limiter status";
CM_ SG_ 308 CRUISE_EGD "Cruise system is controlling speed";
CM_ SG_ 308 CRUISE_ON "Cruise control system 'on'";
CM_ SG_ 308 V_MAX_TM "Max. or cruise control set speed";
CM_ SG_ 308 MAP_ENG "Intake manifold pressure, extended rangeEDR ONLY - Intake manifold pressure";
CM_ SG_ 308 BARO_ENG "Ambient air pressure (barometric pressure)";
CM_ SG_ 308 Rel_Thrt_ENG "Relative throttle value";
CM_ SG_ 308 Rel_Pdl_ENG "Relative pedal value";
CM_ SG_ 308 MC_134h "Message counter";
CM_ SG_ 308 BoostVacGauge "Gauge input for calculated boost/vacuum pressure";
CM_ SG_ 320 Brk_Stat "Brake state";
CM_ SG_ 320 BrkPdl_Stat "Brake pedal state";
CM_ SG_ 320 BrkPdl_Flt "Brake Pedal Fault is active, 1=Faulted";
CM_ SG_ 320 BrkIntrvntn_Actv_ESP "Brake intervention by ESP active";
CM_ SG_ 320 BrkIntrvntn_Actv_AS "Brake intervention by assistance system active";
CM_ SG_ 320 BrkIntrvntn_Enbl "Brake intervention enabled";
CM_ SG_ 320 EmgBrk_Actv "Emergency braking";
CM_ SG_ 320 FullBrk_Actv "Maximum (hard) braking (ALS controls all wheels)";
CM_ SG_ 320 ESP_Sys_Stat "ESP system state";
CM_ SG_ 320 SelSpdSts "Select speed status";
CM_ SG_ 320 ABS_BrkEvt "Any ABS brake event";
CM_ SG_ 320 DTR_CC_Engaged "ACC is engaged; True = [1]";
CM_ SG_ 320 GrMin_Rq_ESC "Requested gear, lower limit";
CM_ SG_ 320 GrMax_Rq_ESC "Requested gear, upper limit";
CM_ SG_ 320 GrMinMax_Rq_DTR "Gear limit request from DTR";
CM_ SG_ 320 DTR_CC_Enabled "ACC is enabled; True = [1]";
CM_ SG_ 320 Brk_Thermdl "Brake thermal over target";
CM_ SG_ 320 ShftChrDsp_Rq_ESC "Shift characteristic displacement request";
CM_ SG_ 320 RollTestMd_Actv "Roller test bench mode active";
CM_ SG_ 320 REF_VEH_SPEED "Reference vehicle actual speed";
CM_ SG_ 320 SPCR_AS_Off_Rq "Assistance system off request";
CM_ SG_ 320 MC_Brk_Stat "Message counter";
CM_ SG_ 320 CRC_Brk_Stat "CRC-checksum byte 1 to 7 according to SAE J1850";
CM_ SG_ 324 K_STO_B "Conf. (torque converter lock-up) clutch 'starts to open'";
CM_ SG_ 324 Ups_Inh_Act "Upshift inhibit active";
CM_ SG_ 324 GearSwitchActiveSts "Transmission shift in progress";
CM_ SG_ 324 OD_OFF "Overdrive lock out";
CM_ SG_ 324 DrvRst_Hi "Drive resistance high/Grade detection";
CM_ SG_ 324 EngSt_Enbl_Rq_TCM "Enable engine start request";
CM_ SG_ 324 AUTO_STK_EGD "Autostic Mode Engaged; automatic shift = [0], manual shift = [1]";
CM_ SG_ 324 BasShftProg_Ok "Basic shift program o.k; aggressive driving = [0]";
CM_ SG_ 324 Gr "Current Gear";
CM_ SG_ 324 Gr_Target "Target Gear";
CM_ SG_ 324 KS "Garage shift torque demand";
CM_ SG_ 324 K_G_B "Conf. (torque converter lock-up) clutch 'closed'";
CM_ SG_ 324 K_O_B "Conf. (torque converter lock-up) clutch 'open'";
CM_ SG_ 324 K_S_B "Conf. (torque converter lock-up) clutch 'slip'";
CM_ SG_ 324 Trns_EMCC_Achvd "Trans A/C Converter Clutch Slipping; [1] = True";
CM_ SG_ 324 AntiJerkDsbl "Anti-jerk disable";
CM_ SG_ 324 EngBrkCanRq "Engine braking cancel request";
CM_ SG_ 324 PTO_Enbl "PTO Enabled";
CM_ SG_ 324 OUTPUT_SPEED "Output Shaft Speed";
CM_ SG_ 324 N_Turb "Unfiltered turbine speed (n_t_v)";
CM_ SG_ 324 OutputSpdPolarity "Output shaft speed polarity";
CM_ SG_ 324 Gear_Pkt_Parity "Gear packet even parity bit";
CM_ SG_ 324 Gear_Pkt_Counter "Gear packet counter";
CM_ SG_ 324 TCM_TmpManMd "Transmission in temporary manual mode";
CM_ SG_ 324 TCM_ManMd "Transmission in manual mode";
CM_ SG_ 328 WHC "Transmission selector lever position";
CM_ SG_ 329 Shft_Warn "Shifter warnings";
CM_ SG_ 331 BrkPrss_TMC "Master cylinder pressure";
CM_ SG_ 331 EngSpdIntervReq "Engine speed intervention request (1=active)";
CM_ SG_ 331 EngSpdInterv "Engine speed intervention value";
CM_ SG_ 331 HSA_BrkPrss "Hill start assist brake pressure";
CM_ SG_ 331 ESCSensorPlausFailSts "ESC sensor plausibility failure status (1=plausibility error)";
CM_ SG_ 331 RBM_Act "Roll back mitigation is active";
CM_ SG_ 331 BrkBstrVac_OBD "Brake booster vacuum level, raw";
CM_ SG_ 331 MC_ESP_A3 "Message counter";
CM_ SG_ 331 CRC_ESP_A3 "CRC-checksum byte 1 to 7 according to SAE J1850";
CM_ SG_ 332 VehYawRate_Raw "Vehicle yaw rate unfiltered/unadjusted (+ means left)";
CM_ SG_ 332 VehYawRate_Offset "Offset of vehicle yaw rate unfiltered/unadjusted (+ means left)";
CM_ SG_ 332 VehAccel_X_Offset "Offset of vehicle longitudinal acceleration (+ means forward)";
CM_ SG_ 332 VehAccel_X "Vehicle longitudinal acceleration (+ means forward)";
CM_ SG_ 332 VehAccel_Y "Vehicle lateral acceleration (+ means left, specific to center of gravity, offset-corrected )";
CM_ SG_ 332 MC_VEH_DYN_STAT "Message counter";
CM_ SG_ 332 VehAccel_Y_Offset "Offset of vehicle lateral acceleration (+ means left)";
CM_ SG_ 344 WhlRPM_FL "Wheel rpm front left";
CM_ SG_ 344 WhlDir_FL_Stat "Direction of rotation of front left wheel";
CM_ SG_ 344 WhlRPM_FR "Wheel rpm front right";
CM_ SG_ 344 WhlDir_FR_Stat "Direction of rotation of front right wheel";
CM_ SG_ 344 WhlRPM_RL "Wheel rpm rear left";
CM_ SG_ 344 WhlDir_RL_Stat "Direction of rotation of rear left wheel";
CM_ SG_ 344 WhlRPM_RR "Wheel rpm rear right";
CM_ SG_ 344 WhlDir_RR_Stat "Direction of rotation of rear right wheel";
CM_ SG_ 352 TCASE_STAT "Transfer Case Status";
CM_ SG_ 352 SHFT_ABRT "Shift has been abortet";
CM_ SG_ 352 ACT_CNT_DIF_TRQ "Actual center differential torque lock";
CM_ SG_ 352 ACT_R_DIF_TRQ "Actual rear differential torque lock";
CM_ SG_ 352 DES_CNT_DIF_TRQ "Desired center differential torque lock";
CM_ SG_ 353 TC_TrqCltAct "Actual center differential torque lock";
CM_ SG_ 353 TC_FaultStat "Transfer Case fault status";
CM_ SG_ 353 MC_DTCM_MAS "Message counter";
CM_ SG_ 353 CRC_DTCM_MAS "CRC-checksum byte 1 to 7 according to SAE J1850";
CM_ SG_ 362 DrvLnTrqRq "Drive line requested engine torque";
CM_ SG_ 362 DrvLnMinTrqMd "Drive line engine torque request: min.-mode";
CM_ SG_ 362 MC_DTCM_A2 "Message counter";
CM_ SG_ 362 CRC_DTCM_A2 "CRC-checksum byte 1 to 7 according to SAE J1850";
BA_DEF_ SG_  "GenSigTimeout_ADCM" INT 0 65535;
BA_DEF_ SG_  "GenSigTimeout_AFLS" INT 0 65535;
BA_DEF_ SG_  "GenSigTimeout_CBC" INT 0 65535;
BA_DEF_ SG_  "GenSigTimeout_DTCM" INT 0 65535;
BA_DEF_ SG_  "GenSigTimeout_ECM" INT 0 65535;
BA_DEF_ SG_  "GenSigTimeout_EPS" INT 0 65535;
BA_DEF_ SG_  "GenSigTimeout_ESC" INT 0 65535;
BA_DEF_ SG_  "GenSigTimeout_ESM" INT 0 65535;
BA_DEF_ SG_  "GenSigTimeout_ETM" INT 0 65535;
BA_DEF_ SG_  "GenSigTimeout_HaLF" INT 0 65535;
BA_DEF_ SG_  "GenSigTimeout_IC" INT 0 65535;
BA_DEF_ SG_  "GenSigTimeout_ORC" INT 0 65535;
BA_DEF_ SG_  "GenSigTimeout_PTS" INT 0 65535;
BA_DEF_ SG_  "GenSigTimeout_RF_HUB" INT 0 65535;
BA_DEF_ SG_  "GenSigTimeout_SCCM" INT 0 65535;
BA_DEF_ SG_  "GenSigTimeout_TPM" INT 0 65535;
BA_DEF_ BU_  "TpOwnSystemEcuNumber" HEX 0 255;
BA_DEF_ BU_  "TpNodeBaseAddress" HEX 0 65535;
BA_DEF_ BO_  "GenMsgStartValue" STRING ;
BA_DEF_ SG_  "GenSigSNA" STRING ;
BA_DEF_  "Version" HEX 0 255;
BA_DEF_  "NmMessageCount" INT 0 64;
BA_DEF_  "NWID" HEX 0 255;
BA_DEF_  "NBTMax" INT 0 255;
BA_DEF_  "NBTMin" INT 0 255;
BA_DEF_  "SamplePointMax" FLOAT 0 100;
BA_DEF_  "SamplePointMin" FLOAT 0 100;
BA_DEF_  "NWM-Basisadresse" HEX 0 536870911;
BA_DEF_  "NWM-Typ" ENUM  "zentral (MB-W210)","dezentral (MB-OSAN)","keines","VAG-OSEK","BMW-OSEK","PAG-OSEK","DBAG-OSEK";
BA_DEF_ BU_  "NWM-Knoten" ENUM  "nein","ja";
BA_DEF_ BU_  "NWM-Stationsadresse" HEX 0 63;
BA_DEF_ SG_  "FlexKomIsMotorola" ENUM  "nein","ja";
BA_DEF_ SG_  "FlexKomSigLaenge" INT 0 64;
BA_DEF_ SG_  "FlexKomSigStartPos" INT 0 63;
BA_DEF_ SG_  "FlexKomComment" STRING ;
BA_DEF_ SG_  "FlexKomSigName" STRING ;
BA_DEF_ SG_  "FlexKomSID" INT 0 2147483647;
BA_DEF_ SG_  "GenSigStartValue" HEX 0 4294967295;
BA_DEF_ SG_  "FlexKomSigStartValue" STRING ;
BA_DEF_ SG_  "GenSigCycleTimeActive" INT 0 65535;
BA_DEF_ SG_  "GenSigCycleTime" INT 0 65535;
BA_DEF_ SG_  "GenSigSendType" ENUM  "cyclicX","spontanX","cyclicIfActiveX","spontanWithDelay","cyclicAndSpontanX","cyclicAndSpontanWithDelay","spontanWithRepitition","cyclicIfActiveAndSpontanWD","cyclicIfActiveFast","cyclicWithRepeatOnDemand","none";
BA_DEF_ BO_  "GenMsgNrOfRepetitions" INT 0 65535;
BA_DEF_ BO_  "GenMsgDelayTime" INT 0 65535;
BA_DEF_ BO_  "GenMsgStartDelayTime" INT 0 65535;
BA_DEF_ BO_  "GenMsgCycleTimeActive" INT 0 65535;
BA_DEF_ BO_  "GenMsgCycleTime" INT 0 65535;
BA_DEF_ BO_  "GenMsgSendType" ENUM  "cyclicX","spontanX","cyclicIfActiveX","spontanWithDelay","cyclicAndSpontanX","cyclicAndSpontanWithDelay","spontanWithRepitition","cyclicIfActiveAndSpontanWD","cyclicIfActiveFast","cyclicWithRepeatOnDemand","none";
BA_DEF_  "Baudrate" INT 0 1000000;
BA_DEF_  "VersionWeek" INT 0 53;
BA_DEF_  "VersionYear" INT 0 99;
BA_DEF_ BO_  "DiagResponse" ENUM  "nein","ja";
BA_DEF_ BO_  "DiagRequest" ENUM  "nein","ja";
BA_DEF_ BO_  "DiagState" ENUM  "nein","ja";
BA_DEF_ BO_  "App-Botschaft" ENUM  "nein","ja";
BA_DEF_ BO_  "NWM-Botschaft" ENUM  "nein","ja";
BA_DEF_  "Manufacturer" ENUM  "DBAG","VAG","BMWAG","PAG","GM";
BA_DEF_DEF_  "GenSigTimeout_ADCM" 0;
BA_DEF_DEF_  "GenSigTimeout_AFLS" 0;
BA_DEF_DEF_  "GenSigTimeout_CBC" 0;
BA_DEF_DEF_  "GenSigTimeout_DTCM" 0;
BA_DEF_DEF_  "GenSigTimeout_ECM" 0;
BA_DEF_DEF_  "GenSigTimeout_EPS" 0;
BA_DEF_DEF_  "GenSigTimeout_ESC" 0;
BA_DEF_DEF_  "GenSigTimeout_ESM" 0;
BA_DEF_DEF_  "GenSigTimeout_ETM" 0;
BA_DEF_DEF_  "GenSigTimeout_HaLF" 0;
BA_DEF_DEF_  "GenSigTimeout_IC" 0;
BA_DEF_DEF_  "GenSigTimeout_ORC" 0;
BA_DEF_DEF_  "GenSigTimeout_PTS" 0;
BA_DEF_DEF_  "GenSigTimeout_RF_HUB" 0;
BA_DEF_DEF_  "GenSigTimeout_SCCM" 0;
BA_DEF_DEF_  "GenSigTimeout_TPM" 0;
BA_DEF_DEF_  "TpOwnSystemEcuNumber" 0;
BA_DEF_DEF_  "TpNodeBaseAddress" 0;
BA_DEF_DEF_  "GenMsgStartValue" "";
BA_DEF_DEF_  "GenSigSNA" "";
BA_DEF_DEF_  "Version" 160;
BA_DEF_DEF_  "NmMessageCount" 64;
BA_DEF_DEF_  "NWID" 0;
BA_DEF_DEF_  "NBTMax" 20;
BA_DEF_DEF_  "NBTMin" 10;
BA_DEF_DEF_  "SamplePointMax" 81.25;
BA_DEF_DEF_  "SamplePointMin" 75;
BA_DEF_DEF_  "NWM-Basisadresse" 1024;
BA_DEF_DEF_  "NWM-Typ" "DBAG-OSEK";
BA_DEF_DEF_  "NWM-Knoten" "nein";
BA_DEF_DEF_  "NWM-Stationsadresse" 0;
BA_DEF_DEF_  "FlexKomIsMotorola" "nein";
BA_DEF_DEF_  "FlexKomSigLaenge" 0;
BA_DEF_DEF_  "FlexKomSigStartPos" 0;
BA_DEF_DEF_  "FlexKomComment" "";
BA_DEF_DEF_  "FlexKomSigName" "";
BA_DEF_DEF_  "FlexKomSID" 0;
BA_DEF_DEF_  "GenSigStartValue" 0;
BA_DEF_DEF_  "FlexKomSigStartValue" "";
BA_DEF_DEF_  "GenSigCycleTimeActive" 0;
BA_DEF_DEF_  "GenSigCycleTime" 0;
BA_DEF_DEF_  "GenSigSendType" "cyclicX";
BA_DEF_DEF_  "GenMsgNrOfRepetitions" 0;
BA_DEF_DEF_  "GenMsgDelayTime" 0;
BA_DEF_DEF_  "GenMsgStartDelayTime" 0;
BA_DEF_DEF_  "GenMsgCycleTimeActive" 0;
BA_DEF_DEF_  "GenMsgCycleTime" 0;
BA_DEF_DEF_  "GenMsgSendType" "cyclicX";
BA_DEF_DEF_  "Baudrate" 500000;
BA_DEF_DEF_  "VersionWeek" 13;
BA_DEF_DEF_  "VersionYear" 13;
BA_DEF_DEF_  "DiagResponse" "nein";
BA_DEF_DEF_  "DiagRequest" "nein";
BA_DEF_DEF_  "DiagState" "nein";
BA_DEF_DEF_  "App-Botschaft" "nein";
BA_DEF_DEF_  "NWM-Botschaft" "nein";
BA_DEF_DEF_  "Manufacturer" "DBAG";
BA_ "NWM-Knoten" BU_ TPM 1;
BA_ "NWM-Stationsadresse" BU_ TPM 3;
BA_ "NWM-Knoten" BU_ SCCM 1;
BA_ "NWM-Stationsadresse" BU_ SCCM 35;
BA_ "NWM-Knoten" BU_ RF_HUB 1;
BA_ "NWM-Knoten" BU_ PTS 1;
BA_ "NWM-Stationsadresse" BU_ PTS 34;
BA_ "NWM-Knoten" BU_ IC 1;
BA_ "NWM-Stationsadresse" BU_ IC 2;
BA_ "NWM-Knoten" BU_ ESM 1;
BA_ "NWM-Stationsadresse" BU_ ESM 9;
BA_ "NWM-Knoten" BU_ ESC 1;
BA_ "NWM-Stationsadresse" BU_ ESC 7;
BA_ "NWM-Knoten" BU_ EPS 1;
BA_ "NWM-Stationsadresse" BU_ EPS 26;
BA_ "NWM-Knoten" BU_ CBC 1;
BA_ "NWM-Stationsadresse" BU_ CBC 1;
BA_ "GenMsgSendType" BO_ 256 1;
BA_ "GenMsgDelayTime" BO_ 256 20;
BA_ "GenMsgNrOfRepetitions" BO_ 256 2;
BA_ "GenMsgStartValue" BO_ 256 "00000000h";
BA_ "GenMsgCycleTime" BO_ 257 100;
BA_ "GenMsgDelayTime" BO_ 257 20;
BA_ "GenMsgNrOfRepetitions" BO_ 257 2;
BA_ "GenMsgStartValue" BO_ 257 "0000000000h";
BA_ "GenMsgCycleTime" BO_ 258 10;
BA_ "GenMsgDelayTime" BO_ 258 20;
BA_ "GenMsgNrOfRepetitions" BO_ 258 2;
BA_ "GenMsgStartValue" BO_ 258 "3FFF3FFF030000FFh";
BA_ "GenMsgCycleTime" BO_ 264 10;
BA_ "GenMsgDelayTime" BO_ 264 20;
BA_ "GenMsgNrOfRepetitions" BO_ 264 2;
BA_ "GenMsgStartValue" BO_ 264 "FFFF1FFF1FFF00FFh";
BA_ "GenMsgCycleTime" BO_ 268 20;
BA_ "GenMsgDelayTime" BO_ 268 20;
BA_ "GenMsgNrOfRepetitions" BO_ 268 2;
BA_ "GenMsgStartValue" BO_ 268 "00000000FF0000FFh";
BA_ "GenMsgCycleTime" BO_ 269 20;
BA_ "GenMsgDelayTime" BO_ 269 20;
BA_ "GenMsgNrOfRepetitions" BO_ 269 2;
BA_ "GenMsgStartValue" BO_ 269 "00000000000000FFh";
BA_ "GenMsgSendType" BO_ 272 1;
BA_ "GenMsgDelayTime" BO_ 272 20;
BA_ "GenMsgNrOfRepetitions" BO_ 272 2;
BA_ "GenMsgStartValue" BO_ 272 "000000000000h";
BA_ "GenMsgSendType" BO_ 273 1;
BA_ "GenMsgDelayTime" BO_ 273 20;
BA_ "GenMsgNrOfRepetitions" BO_ 273 2;
BA_ "GenMsgStartValue" BO_ 273 "FFFFFF000000h";
BA_ "GenMsgCycleTime" BO_ 274 20;
BA_ "GenMsgDelayTime" BO_ 274 20;
BA_ "GenMsgNrOfRepetitions" BO_ 274 2;
BA_ "GenMsgStartValue" BO_ 274 "0000h";
BA_ "GenMsgCycleTime" BO_ 280 10;
BA_ "GenMsgDelayTime" BO_ 280 20;
BA_ "GenMsgNrOfRepetitions" BO_ 280 2;
BA_ "GenMsgStartValue" BO_ 280 "9FFF1FFF1FFF00FFh";
BA_ "GenMsgCycleTime" BO_ 284 20;
BA_ "GenMsgDelayTime" BO_ 284 20;
BA_ "GenMsgNrOfRepetitions" BO_ 284 2;
BA_ "GenMsgStartValue" BO_ 284 "0FFF0FFFFFFF00FFh";
BA_ "GenMsgCycleTime" BO_ 288 20;
BA_ "GenMsgDelayTime" BO_ 288 20;
BA_ "GenMsgNrOfRepetitions" BO_ 288 2;
BA_ "GenMsgStartValue" BO_ 288 "1FFFFF1FFF00FFh";
BA_ "GenMsgCycleTime" BO_ 290 20;
BA_ "GenMsgDelayTime" BO_ 290 20;
BA_ "GenMsgNrOfRepetitions" BO_ 290 2;
BA_ "GenMsgStartValue" BO_ 290 "00FF000FFFFFh";
BA_ "GenMsgCycleTime" BO_ 292 20;
BA_ "GenMsgDelayTime" BO_ 292 20;
BA_ "GenMsgNrOfRepetitions" BO_ 292 2;
BA_ "GenMsgStartValue" BO_ 292 "FFFFFFFF00FFFFFFh";
BA_ "GenMsgCycleTime" BO_ 294 10;
BA_ "GenMsgDelayTime" BO_ 294 20;
BA_ "GenMsgNrOfRepetitions" BO_ 294 2;
BA_ "GenMsgStartValue" BO_ 294 "000000000FFF00FFh";
BA_ "GenMsgCycleTime" BO_ 300 100;
BA_ "GenMsgDelayTime" BO_ 300 20;
BA_ "GenMsgNrOfRepetitions" BO_ 300 2;
BA_ "GenMsgStartValue" BO_ 300 "0200FF0000000000h";
BA_ "GenMsgCycleTime" BO_ 308 20;
BA_ "GenMsgDelayTime" BO_ 308 20;
BA_ "GenMsgNrOfRepetitions" BO_ 308 2;
BA_ "GenMsgStartValue" BO_ 308 "08FFFF00FFFF00FFh";
BA_ "GenMsgCycleTime" BO_ 320 20;
BA_ "GenMsgDelayTime" BO_ 320 20;
BA_ "GenMsgNrOfRepetitions" BO_ 320 2;
BA_ "GenMsgStartValue" BO_ 320 "0F3400C003FF00FFh";
BA_ "GenMsgCycleTime" BO_ 324 20;
BA_ "GenMsgDelayTime" BO_ 324 20;
BA_ "GenMsgNrOfRepetitions" BO_ 324 2;
BA_ "GenMsgStartValue" BO_ 324 "00FF00FFFFFFFF00h";
BA_ "GenMsgCycleTime" BO_ 328 10;
BA_ "GenMsgDelayTime" BO_ 328 20;
BA_ "GenMsgNrOfRepetitions" BO_ 328 2;
BA_ "GenMsgStartValue" BO_ 328 "00h";
BA_ "GenMsgCycleTime" BO_ 329 10;
BA_ "GenMsgDelayTime" BO_ 329 20;
BA_ "GenMsgNrOfRepetitions" BO_ 329 2;
BA_ "GenMsgStartValue" BO_ 329 "00000000FFh";
BA_ "GenMsgCycleTime" BO_ 331 20;
BA_ "GenMsgDelayTime" BO_ 331 20;
BA_ "GenMsgNrOfRepetitions" BO_ 331 2;
BA_ "GenMsgStartValue" BO_ 331 "0000FFFF00FF00FFh";
BA_ "GenMsgCycleTime" BO_ 332 20;
BA_ "GenMsgDelayTime" BO_ 332 20;
BA_ "GenMsgNrOfRepetitions" BO_ 332 2;
BA_ "GenMsgStartValue" BO_ 332 "FFFFFFFFFFFF00FFh";
BA_ "GenMsgCycleTime" BO_ 344 20;
BA_ "GenMsgDelayTime" BO_ 344 20;
BA_ "GenMsgNrOfRepetitions" BO_ 344 2;
BA_ "GenMsgStartValue" BO_ 344 "FFFFFFFFFFFFFFFFh";
BA_ "GenMsgCycleTime" BO_ 352 20;
BA_ "GenMsgDelayTime" BO_ 352 20;
BA_ "GenMsgNrOfRepetitions" BO_ 352 2;
BA_ "GenMsgStartValue" BO_ 352 "CEC0FFFFFFFFFFFFh";
BA_ "GenMsgCycleTime" BO_ 353 20;
BA_ "GenMsgDelayTime" BO_ 353 20;
BA_ "GenMsgNrOfRepetitions" BO_ 353 2;
BA_ "GenMsgStartValue" BO_ 353 "000007FF00000FFFh";
BA_ "GenMsgCycleTime" BO_ 362 20;
BA_ "GenMsgDelayTime" BO_ 362 20;
BA_ "GenMsgNrOfRepetitions" BO_ 362 2;
BA_ "GenMsgStartValue" BO_ 362 "01FF0000000000FFh";
BA_ "GenSigSendType" SG_ 256 RND_NUM1 1;
BA_ "FlexKomSigStartValue" SG_ 256 RND_NUM1 "00000000h";
BA_ "FlexKomSID" SG_ 256 RND_NUM1 1050;
BA_ "FlexKomSigStartPos" SG_ 256 RND_NUM1 7;
BA_ "FlexKomSigLaenge" SG_ 256 RND_NUM1 32;
BA_ "FlexKomSigName" SG_ 256 RND_NUM1 "ENGINE_SKIM_RESP";
BA_ "FlexKomComment" SG_ 256 RND_NUM1 "ECM Skim Response";
BA_ "FlexKomIsMotorola" SG_ 256 RND_NUM1 1;
BA_ "GenSigSNA" SG_ 256 RND_NUM1 "0h";
BA_ "GenSigSendType" SG_ 256 RND_NUM2 1;
BA_ "FlexKomSigStartValue" SG_ 256 RND_NUM2 "00000000h";
BA_ "FlexKomSID" SG_ 256 RND_NUM2 1050;
BA_ "FlexKomSigStartPos" SG_ 256 RND_NUM2 7;
BA_ "FlexKomSigLaenge" SG_ 256 RND_NUM2 32;
BA_ "FlexKomSigName" SG_ 256 RND_NUM2 "ENGINE_SKIM_RESP";
BA_ "FlexKomComment" SG_ 256 RND_NUM2 "ECM Skim Response";
BA_ "FlexKomIsMotorola" SG_ 256 RND_NUM2 1;
BA_ "GenSigSNA" SG_ 256 RND_NUM2 "0h";
BA_ "GenSigSendType" SG_ 256 RND_NUM3 1;
BA_ "FlexKomSigStartValue" SG_ 256 RND_NUM3 "00000000h";
BA_ "FlexKomSID" SG_ 256 RND_NUM3 1050;
BA_ "FlexKomSigStartPos" SG_ 256 RND_NUM3 7;
BA_ "FlexKomSigLaenge" SG_ 256 RND_NUM3 32;
BA_ "FlexKomSigName" SG_ 256 RND_NUM3 "ENGINE_SKIM_RESP";
BA_ "FlexKomComment" SG_ 256 RND_NUM3 "ECM Skim Response";
BA_ "FlexKomIsMotorola" SG_ 256 RND_NUM3 1;
BA_ "GenSigSNA" SG_ 256 RND_NUM3 "0h";
BA_ "GenSigSendType" SG_ 256 RND_NUM4 1;
BA_ "FlexKomSigStartValue" SG_ 256 RND_NUM4 "00000000h";
BA_ "FlexKomSID" SG_ 256 RND_NUM4 1050;
BA_ "FlexKomSigStartPos" SG_ 256 RND_NUM4 7;
BA_ "FlexKomSigLaenge" SG_ 256 RND_NUM4 32;
BA_ "FlexKomSigName" SG_ 256 RND_NUM4 "ENGINE_SKIM_RESP";
BA_ "FlexKomComment" SG_ 256 RND_NUM4 "ECM Skim Response";
BA_ "FlexKomIsMotorola" SG_ 256 RND_NUM4 1;
BA_ "GenSigSNA" SG_ 256 RND_NUM4 "0h";
BA_ "GenSigCycleTime" SG_ 257 CARB_Temp 100;
BA_ "FlexKomSigStartValue" SG_ 257 CARB_Temp "00h";
BA_ "FlexKomSID" SG_ 257 CARB_Temp 1261;
BA_ "FlexKomSigLaenge" SG_ 257 CARB_Temp 1;
BA_ "FlexKomSigName" SG_ 257 CARB_Temp "CARB_Temp";
BA_ "FlexKomComment" SG_ 257 CARB_Temp "CARB warmup criteria is true [1]";
BA_ "FlexKomIsMotorola" SG_ 257 CARB_Temp 1;
BA_ "GenSigSNA" SG_ 257 CARB_Temp "0h";
BA_ "GenSigCycleTime" SG_ 257 Inp_GD_Fail 100;
BA_ "FlexKomSigStartValue" SG_ 257 Inp_GD_Fail "00h";
BA_ "FlexKomSID" SG_ 257 Inp_GD_Fail 1260;
BA_ "FlexKomSigStartPos" SG_ 257 Inp_GD_Fail 1;
BA_ "FlexKomSigLaenge" SG_ 257 Inp_GD_Fail 1;
BA_ "FlexKomSigName" SG_ 257 Inp_GD_Fail "Inp_GD_Fail";
BA_ "FlexKomComment" SG_ 257 Inp_GD_Fail "Inputs to the general denominator are in a pend or";
BA_ "FlexKomIsMotorola" SG_ 257 Inp_GD_Fail 1;
BA_ "GenSigSNA" SG_ 257 Inp_GD_Fail "0h";
BA_ "GenSigCycleTime" SG_ 257 InpICC_Fail 100;
BA_ "FlexKomSigStartValue" SG_ 257 InpICC_Fail "00h";
BA_ "FlexKomSID" SG_ 257 InpICC_Fail 1259;
BA_ "FlexKomSigStartPos" SG_ 257 InpICC_Fail 2;
BA_ "FlexKomSigLaenge" SG_ 257 InpICC_Fail 1;
BA_ "FlexKomSigName" SG_ 257 InpICC_Fail "InpICC_Fail";
BA_ "FlexKomComment" SG_ 257 InpICC_Fail "Inputs to the Ign Cycle Cntr are in a Pend or MIL ";
BA_ "FlexKomIsMotorola" SG_ 257 InpICC_Fail 1;
BA_ "GenSigSNA" SG_ 257 InpICC_Fail "0h";
BA_ "GenSigCycleTime" SG_ 257 CARB_PERM 100;
BA_ "FlexKomSigStartValue" SG_ 257 CARB_PERM "00h";
BA_ "FlexKomSID" SG_ 257 CARB_PERM 1258;
BA_ "FlexKomSigStartPos" SG_ 257 CARB_PERM 3;
BA_ "FlexKomSigLaenge" SG_ 257 CARB_PERM 1;
BA_ "FlexKomSigName" SG_ 257 CARB_PERM "CARB_PERM";
BA_ "FlexKomComment" SG_ 257 CARB_PERM "CARB permanent fault code drive cycle";
BA_ "FlexKomIsMotorola" SG_ 257 CARB_PERM 1;
BA_ "GenSigSNA" SG_ 257 CARB_PERM "0h";
BA_ "GenSigCycleTime" SG_ 257 OBD_GnrlDenCond_Stat 100;
BA_ "FlexKomSigStartValue" SG_ 257 OBD_GnrlDenCond_Stat "00h";
BA_ "FlexKomSID" SG_ 257 OBD_GnrlDenCond_Stat 1256;
BA_ "FlexKomSigStartPos" SG_ 257 OBD_GnrlDenCond_Stat 5;
BA_ "FlexKomSigLaenge" SG_ 257 OBD_GnrlDenCond_Stat 1;
BA_ "FlexKomSigName" SG_ 257 OBD_GnrlDenCond_Stat "OBD_GnrlDenCond_Stat";
BA_ "FlexKomComment" SG_ 257 OBD_GnrlDenCond_Stat "General denominator conditions are met [1].";
BA_ "FlexKomIsMotorola" SG_ 257 OBD_GnrlDenCond_Stat 1;
BA_ "GenSigSNA" SG_ 257 OBD_GnrlDenCond_Stat "0h";
BA_ "GenSigCycleTime" SG_ 257 IgnCntrTrue 100;
BA_ "FlexKomSigStartValue" SG_ 257 IgnCntrTrue "00h";
BA_ "FlexKomSID" SG_ 257 IgnCntrTrue 1255;
BA_ "FlexKomSigStartPos" SG_ 257 IgnCntrTrue 6;
BA_ "FlexKomSigLaenge" SG_ 257 IgnCntrTrue 1;
BA_ "FlexKomSigName" SG_ 257 IgnCntrTrue "IgnCntrTrue";
BA_ "FlexKomComment" SG_ 257 IgnCntrTrue "Ignition cycle counter is true [1]";
BA_ "FlexKomIsMotorola" SG_ 257 IgnCntrTrue 1;
BA_ "GenSigSNA" SG_ 257 IgnCntrTrue "0h";
BA_ "GenSigCycleTime" SG_ 257 ENGINE_RESET 100;
BA_ "FlexKomSigStartValue" SG_ 257 ENGINE_RESET "00h";
BA_ "FlexKomSID" SG_ 257 ENGINE_RESET 429;
BA_ "FlexKomSigStartPos" SG_ 257 ENGINE_RESET 10;
BA_ "FlexKomSigLaenge" SG_ 257 ENGINE_RESET 3;
BA_ "FlexKomSigName" SG_ 257 ENGINE_RESET "ECM_SKIM_STAT_PKT";
BA_ "FlexKomComment" SG_ 257 ENGINE_RESET "ECM Immobilizer Status Packet";
BA_ "FlexKomIsMotorola" SG_ 257 ENGINE_RESET 1;
BA_ "GenSigSNA" SG_ 257 ENGINE_RESET "0h";
BA_ "GenSigCycleTime" SG_ 257 ECM_SKIM_STAT 100;
BA_ "FlexKomSigStartValue" SG_ 257 ECM_SKIM_STAT "00h";
BA_ "FlexKomSID" SG_ 257 ECM_SKIM_STAT 429;
BA_ "FlexKomSigStartPos" SG_ 257 ECM_SKIM_STAT 10;
BA_ "FlexKomSigLaenge" SG_ 257 ECM_SKIM_STAT 3;
BA_ "FlexKomSigName" SG_ 257 ECM_SKIM_STAT "ECM_SKIM_STAT_PKT";
BA_ "FlexKomComment" SG_ 257 ECM_SKIM_STAT "ECM Immobilizer Status Packet";
BA_ "FlexKomIsMotorola" SG_ 257 ECM_SKIM_STAT 1;
BA_ "GenSigSNA" SG_ 257 ECM_SKIM_STAT "3h";
BA_ "GenSigCycleTime" SG_ 257 EngLoad_OBD 100;
BA_ "FlexKomSigStartValue" SG_ 257 EngLoad_OBD "00h";
BA_ "FlexKomSID" SG_ 257 EngLoad_OBD 1088;
BA_ "FlexKomSigStartPos" SG_ 257 EngLoad_OBD 23;
BA_ "FlexKomSigLaenge" SG_ 257 EngLoad_OBD 8;
BA_ "FlexKomSigName" SG_ 257 EngLoad_OBD "EngLoad_OBD";
BA_ "FlexKomComment" SG_ 257 EngLoad_OBD "Load value for OBD (ISO 15031-5.4 PID 4)";
BA_ "FlexKomIsMotorola" SG_ 257 EngLoad_OBD 1;
BA_ "GenSigSNA" SG_ 257 EngLoad_OBD "0h";
BA_ "GenSigCycleTime" SG_ 257 AccelPdlPosn_OBD 100;
BA_ "FlexKomSigStartValue" SG_ 257 AccelPdlPosn_OBD "00h";
BA_ "FlexKomSID" SG_ 257 AccelPdlPosn_OBD 1089;
BA_ "FlexKomSigStartPos" SG_ 257 AccelPdlPosn_OBD 31;
BA_ "FlexKomSigLaenge" SG_ 257 AccelPdlPosn_OBD 8;
BA_ "FlexKomSigName" SG_ 257 AccelPdlPosn_OBD "AccelPdlPosn_OBD";
BA_ "FlexKomComment" SG_ 257 AccelPdlPosn_OBD "Pedal value for OBD (ISO 15031-5.4 PID 49)";
BA_ "FlexKomIsMotorola" SG_ 257 AccelPdlPosn_OBD 1;
BA_ "GenSigSNA" SG_ 257 AccelPdlPosn_OBD "0h";
BA_ "GenSigCycleTime" SG_ 257 RAD_FAN1_STAT 100;
BA_ "FlexKomSigStartValue" SG_ 257 RAD_FAN1_STAT "00h";
BA_ "GenSigTimeout_ETM" SG_ 257 RAD_FAN1_STAT 1050;
BA_ "FlexKomSID" SG_ 257 RAD_FAN1_STAT 1091;
BA_ "FlexKomSigStartPos" SG_ 257 RAD_FAN1_STAT 39;
BA_ "FlexKomSigLaenge" SG_ 257 RAD_FAN1_STAT 8;
BA_ "FlexKomSigName" SG_ 257 RAD_FAN1_STAT "RAD_FAN1_STAT";
BA_ "FlexKomComment" SG_ 257 RAD_FAN1_STAT "Low speed or single radiator fan requested duty cy";
BA_ "FlexKomIsMotorola" SG_ 257 RAD_FAN1_STAT 1;
BA_ "GenSigSNA" SG_ 257 RAD_FAN1_STAT "FFh";
BA_ "GenSigCycleTime" SG_ 258 LRW 10;
BA_ "FlexKomSigStartValue" SG_ 258 LRW "3FFF3FFF030000FFh";
BA_ "GenSigStartValue" SG_ 258 LRW 16383;
BA_ "GenSigTimeout_CBC" SG_ 258 LRW 105;
BA_ "GenSigTimeout_AFLS" SG_ 258 LRW 205;
BA_ "GenSigTimeout_EPS" SG_ 258 LRW 105;
BA_ "GenSigTimeout_DTCM" SG_ 258 LRW 105;
BA_ "GenSigTimeout_ADCM" SG_ 258 LRW 505;
BA_ "GenSigTimeout_ORC" SG_ 258 LRW 35;
BA_ "FlexKomSID" SG_ 258 LRW 418;
BA_ "FlexKomSigStartPos" SG_ 258 LRW 7;
BA_ "FlexKomSigLaenge" SG_ 258 LRW 64;
BA_ "FlexKomSigName" SG_ 258 LRW "LRW_ST";
BA_ "FlexKomComment" SG_ 258 LRW "Steering wheel angle state";
BA_ "FlexKomIsMotorola" SG_ 258 LRW 1;
BA_ "GenSigSNA" SG_ 258 LRW "3FFFh";
BA_ "GenSigCycleTime" SG_ 258 LRW_PLRTY 10;
BA_ "FlexKomSigStartValue" SG_ 258 LRW_PLRTY "3FFF3FFF030000FFh";
BA_ "GenSigTimeout_ORC" SG_ 258 LRW_PLRTY 35;
BA_ "GenSigTimeout_ETM" SG_ 258 LRW_PLRTY 105;
BA_ "FlexKomSID" SG_ 258 LRW_PLRTY 418;
BA_ "FlexKomSigStartPos" SG_ 258 LRW_PLRTY 7;
BA_ "FlexKomSigLaenge" SG_ 258 LRW_PLRTY 64;
BA_ "FlexKomSigName" SG_ 258 LRW_PLRTY "LRW_ST";
BA_ "FlexKomComment" SG_ 258 LRW_PLRTY "Steering wheel angle state";
BA_ "FlexKomIsMotorola" SG_ 258 LRW_PLRTY 1;
BA_ "GenSigSNA" SG_ 258 LRW_PLRTY "0h";
BA_ "GenSigCycleTime" SG_ 258 VLRW 10;
BA_ "FlexKomSigStartValue" SG_ 258 VLRW "3FFF3FFF030000FFh";
BA_ "GenSigStartValue" SG_ 258 VLRW 16383;
BA_ "GenSigTimeout_EPS" SG_ 258 VLRW 105;
BA_ "GenSigTimeout_DTCM" SG_ 258 VLRW 105;
BA_ "GenSigTimeout_ADCM" SG_ 258 VLRW 505;
BA_ "GenSigTimeout_ORC" SG_ 258 VLRW 35;
BA_ "GenSigTimeout_ETM" SG_ 258 VLRW 105;
BA_ "FlexKomSID" SG_ 258 VLRW 418;
BA_ "FlexKomSigStartPos" SG_ 258 VLRW 7;
BA_ "FlexKomSigLaenge" SG_ 258 VLRW 64;
BA_ "FlexKomSigName" SG_ 258 VLRW "LRW_ST";
BA_ "FlexKomComment" SG_ 258 VLRW "Steering wheel angle state";
BA_ "FlexKomIsMotorola" SG_ 258 VLRW 1;
BA_ "GenSigSNA" SG_ 258 VLRW "3FFFh";
BA_ "GenSigCycleTime" SG_ 258 LRWS_ST 10;
BA_ "FlexKomSigStartValue" SG_ 258 LRWS_ST "3FFF3FFF030000FFh";
BA_ "GenSigStartValue" SG_ 258 LRWS_ST 3;
BA_ "GenSigTimeout_ADCM" SG_ 258 LRWS_ST 505;
BA_ "GenSigTimeout_ORC" SG_ 258 LRWS_ST 35;
BA_ "GenSigTimeout_ETM" SG_ 258 LRWS_ST 105;
BA_ "FlexKomSID" SG_ 258 LRWS_ST 418;
BA_ "FlexKomSigStartPos" SG_ 258 LRWS_ST 7;
BA_ "FlexKomSigLaenge" SG_ 258 LRWS_ST 64;
BA_ "FlexKomSigName" SG_ 258 LRWS_ST "LRW_ST";
BA_ "FlexKomComment" SG_ 258 LRWS_ST "Steering wheel angle state";
BA_ "FlexKomIsMotorola" SG_ 258 LRWS_ST 1;
BA_ "GenSigSNA" SG_ 258 LRWS_ST "3h";
BA_ "GenSigCycleTime" SG_ 258 Pad_Shft 10;
BA_ "FlexKomSigStartValue" SG_ 258 Pad_Shft "3FFF3FFF030000FFh";
BA_ "GenSigTimeout_ETM" SG_ 258 Pad_Shft 105;
BA_ "FlexKomSID" SG_ 258 Pad_Shft 418;
BA_ "FlexKomSigStartPos" SG_ 258 Pad_Shft 7;
BA_ "FlexKomSigLaenge" SG_ 258 Pad_Shft 64;
BA_ "FlexKomSigName" SG_ 258 Pad_Shft "LRW_ST";
BA_ "FlexKomComment" SG_ 258 Pad_Shft "Steering wheel angle state";
BA_ "FlexKomIsMotorola" SG_ 258 Pad_Shft 1;
BA_ "GenSigSNA" SG_ 258 Pad_Shft "7h";
BA_ "GenSigCycleTime" SG_ 258 ERS_ACC_SW 10;
BA_ "FlexKomSigStartValue" SG_ 258 ERS_ACC_SW "3FFF3FFF030000FFh";
BA_ "FlexKomSID" SG_ 258 ERS_ACC_SW 418;
BA_ "FlexKomSigStartPos" SG_ 258 ERS_ACC_SW 7;
BA_ "FlexKomSigLaenge" SG_ 258 ERS_ACC_SW 64;
BA_ "FlexKomSigName" SG_ 258 ERS_ACC_SW "LRW_ST";
BA_ "FlexKomComment" SG_ 258 ERS_ACC_SW "Steering wheel angle state";
BA_ "FlexKomIsMotorola" SG_ 258 ERS_ACC_SW 1;
BA_ "GenSigSNA" SG_ 258 ERS_ACC_SW "7h";
BA_ "GenSigCycleTime" SG_ 258 LRW_RHP 10;
BA_ "FlexKomSigStartValue" SG_ 258 LRW_RHP "3FFF3FFF030000FFh";
BA_ "GenSigTimeout_EPS" SG_ 258 LRW_RHP 105;
BA_ "GenSigTimeout_ETM" SG_ 258 LRW_RHP 105;
BA_ "FlexKomSID" SG_ 258 LRW_RHP 418;
BA_ "FlexKomSigStartPos" SG_ 258 LRW_RHP 7;
BA_ "FlexKomSigLaenge" SG_ 258 LRW_RHP 64;
BA_ "FlexKomSigName" SG_ 258 LRW_RHP "LRW_ST";
BA_ "FlexKomComment" SG_ 258 LRW_RHP "Steering wheel angle state";
BA_ "FlexKomIsMotorola" SG_ 258 LRW_RHP 1;
BA_ "GenSigSNA" SG_ 258 LRW_RHP "0h";
BA_ "GenSigCycleTime" SG_ 258 MC_STW_Angle_STAT 10;
BA_ "FlexKomSigStartValue" SG_ 258 MC_STW_Angle_STAT "3FFF3FFF030000FFh";
BA_ "GenSigTimeout_ORC" SG_ 258 MC_STW_Angle_STAT 35;
BA_ "GenSigTimeout_ETM" SG_ 258 MC_STW_Angle_STAT 105;
BA_ "FlexKomSID" SG_ 258 MC_STW_Angle_STAT 418;
BA_ "FlexKomSigStartPos" SG_ 258 MC_STW_Angle_STAT 7;
BA_ "FlexKomSigLaenge" SG_ 258 MC_STW_Angle_STAT 64;
BA_ "FlexKomSigName" SG_ 258 MC_STW_Angle_STAT "LRW_ST";
BA_ "FlexKomComment" SG_ 258 MC_STW_Angle_STAT "Steering wheel angle state";
BA_ "FlexKomIsMotorola" SG_ 258 MC_STW_Angle_STAT 1;
BA_ "GenSigSNA" SG_ 258 MC_STW_Angle_STAT "0h";
BA_ "GenSigCycleTime" SG_ 258 CRC_STW_Angle_STAT 10;
BA_ "FlexKomSigStartValue" SG_ 258 CRC_STW_Angle_STAT "3FFF3FFF030000FFh";
BA_ "GenSigStartValue" SG_ 258 CRC_STW_Angle_STAT 255;
BA_ "GenSigTimeout_ORC" SG_ 258 CRC_STW_Angle_STAT 35;
BA_ "GenSigTimeout_ETM" SG_ 258 CRC_STW_Angle_STAT 105;
BA_ "FlexKomSID" SG_ 258 CRC_STW_Angle_STAT 418;
BA_ "FlexKomSigStartPos" SG_ 258 CRC_STW_Angle_STAT 7;
BA_ "FlexKomSigLaenge" SG_ 258 CRC_STW_Angle_STAT 64;
BA_ "FlexKomSigName" SG_ 258 CRC_STW_Angle_STAT "LRW_ST";
BA_ "FlexKomComment" SG_ 258 CRC_STW_Angle_STAT "Steering wheel angle state";
BA_ "FlexKomIsMotorola" SG_ 258 CRC_STW_Angle_STAT 1;
BA_ "GenSigSNA" SG_ 258 CRC_STW_Angle_STAT "FFh";
BA_ "GenSigCycleTime" SG_ 264 EngRPM 10;
BA_ "FlexKomSigStartValue" SG_ 264 EngRPM "FFFF1FFF1FFF00FFh";
BA_ "GenSigStartValue" SG_ 264 EngRPM 65535;
BA_ "GenSigTimeout_CBC" SG_ 264 EngRPM 105;
BA_ "GenSigTimeout_IC" SG_ 264 EngRPM 105;
BA_ "GenSigTimeout_TPM" SG_ 264 EngRPM 105;
BA_ "GenSigTimeout_AFLS" SG_ 264 EngRPM 205;
BA_ "GenSigTimeout_EPS" SG_ 264 EngRPM 105;
BA_ "GenSigTimeout_DTCM" SG_ 264 EngRPM 105;
BA_ "GenSigTimeout_ADCM" SG_ 264 EngRPM 505;
BA_ "GenSigTimeout_ORC" SG_ 264 EngRPM 35;
BA_ "FlexKomSID" SG_ 264 EngRPM 446;
BA_ "FlexKomSigStartPos" SG_ 264 EngRPM 7;
BA_ "FlexKomSigLaenge" SG_ 264 EngRPM 64;
BA_ "FlexKomSigName" SG_ 264 EngRPM "ECM_A1_PKT";
BA_ "FlexKomComment" SG_ 264 EngRPM "ECM_A1 Packet";
BA_ "FlexKomIsMotorola" SG_ 264 EngRPM 1;
BA_ "GenSigSNA" SG_ 264 EngRPM "FFFFh";
BA_ "GenSigCycleTime" SG_ 264 EngTrqStatic 10;
BA_ "FlexKomSigStartValue" SG_ 264 EngTrqStatic "FFFF1FFF1FFF00FFh";
BA_ "GenSigStartValue" SG_ 264 EngTrqStatic 8191;
BA_ "GenSigTimeout_CBC" SG_ 264 EngTrqStatic 105;
BA_ "GenSigTimeout_IC" SG_ 264 EngTrqStatic 105;
BA_ "GenSigTimeout_DTCM" SG_ 264 EngTrqStatic 105;
BA_ "FlexKomSID" SG_ 264 EngTrqStatic 446;
BA_ "FlexKomSigStartPos" SG_ 264 EngTrqStatic 7;
BA_ "FlexKomSigLaenge" SG_ 264 EngTrqStatic 64;
BA_ "FlexKomSigName" SG_ 264 EngTrqStatic "ECM_A1_PKT";
BA_ "FlexKomComment" SG_ 264 EngTrqStatic "ECM_A1 Packet";
BA_ "FlexKomIsMotorola" SG_ 264 EngTrqStatic 1;
BA_ "GenSigSNA" SG_ 264 EngTrqStatic "1FFFh";
BA_ "GenSigCycleTime" SG_ 264 ExpEngTrq 10;
BA_ "FlexKomSigStartValue" SG_ 264 ExpEngTrq "FFFF1FFF1FFF00FFh";
BA_ "GenSigStartValue" SG_ 264 ExpEngTrq 8191;
BA_ "FlexKomSID" SG_ 264 ExpEngTrq 446;
BA_ "FlexKomSigStartPos" SG_ 264 ExpEngTrq 7;
BA_ "FlexKomSigLaenge" SG_ 264 ExpEngTrq 64;
BA_ "FlexKomSigName" SG_ 264 ExpEngTrq "ECM_A1_PKT";
BA_ "FlexKomComment" SG_ 264 ExpEngTrq "ECM_A1 Packet";
BA_ "FlexKomIsMotorola" SG_ 264 ExpEngTrq 1;
BA_ "GenSigSNA" SG_ 264 ExpEngTrq "1FFFh";
BA_ "GenSigCycleTime" SG_ 264 MC_ECM_A1 10;
BA_ "FlexKomSigStartValue" SG_ 264 MC_ECM_A1 "FFFF1FFF1FFF00FFh";
BA_ "FlexKomSID" SG_ 264 MC_ECM_A1 446;
BA_ "FlexKomSigStartPos" SG_ 264 MC_ECM_A1 7;
BA_ "FlexKomSigLaenge" SG_ 264 MC_ECM_A1 64;
BA_ "FlexKomSigName" SG_ 264 MC_ECM_A1 "ECM_A1_PKT";
BA_ "FlexKomComment" SG_ 264 MC_ECM_A1 "ECM_A1 Packet";
BA_ "FlexKomIsMotorola" SG_ 264 MC_ECM_A1 1;
BA_ "GenSigSNA" SG_ 264 MC_ECM_A1 "0h";
BA_ "GenSigCycleTime" SG_ 264 CRC_ECM_A1 10;
BA_ "FlexKomSigStartValue" SG_ 264 CRC_ECM_A1 "FFFF1FFF1FFF00FFh";
BA_ "GenSigStartValue" SG_ 264 CRC_ECM_A1 255;
BA_ "FlexKomSID" SG_ 264 CRC_ECM_A1 446;
BA_ "FlexKomSigStartPos" SG_ 264 CRC_ECM_A1 7;
BA_ "FlexKomSigLaenge" SG_ 264 CRC_ECM_A1 64;
BA_ "FlexKomSigName" SG_ 264 CRC_ECM_A1 "ECM_A1_PKT";
BA_ "FlexKomComment" SG_ 264 CRC_ECM_A1 "ECM_A1 Packet";
BA_ "FlexKomIsMotorola" SG_ 264 CRC_ECM_A1 1;
BA_ "GenSigSNA" SG_ 264 CRC_ECM_A1 "FFh";
BA_ "GenSigCycleTime" SG_ 268 EngTrq_Rq_ESC 20;
BA_ "FlexKomSigStartValue" SG_ 268 EngTrq_Rq_ESC "00000000FF0000FFh";
BA_ "GenSigTimeout_ETM" SG_ 268 EngTrq_Rq_ESC 210;
BA_ "FlexKomSID" SG_ 268 EngTrq_Rq_ESC 1;
BA_ "FlexKomSigStartPos" SG_ 268 EngTrq_Rq_ESC 7;
BA_ "FlexKomSigLaenge" SG_ 268 EngTrq_Rq_ESC 64;
BA_ "FlexKomSigName" SG_ 268 EngTrq_Rq_ESC "Eng_Trq_Rq";
BA_ "FlexKomComment" SG_ 268 EngTrq_Rq_ESC "Engine torque request from ESC";
BA_ "FlexKomIsMotorola" SG_ 268 EngTrq_Rq_ESC 1;
BA_ "GenSigSNA" SG_ 268 EngTrq_Rq_ESC "1FFFh";
BA_ "GenSigCycleTime" SG_ 268 DAS_Enbl_Rq 20;
BA_ "FlexKomSigStartValue" SG_ 268 DAS_Enbl_Rq "00000000FF0000FFh";
BA_ "GenSigTimeout_ORC" SG_ 268 DAS_Enbl_Rq 70;
BA_ "FlexKomSID" SG_ 268 DAS_Enbl_Rq 1;
BA_ "FlexKomSigStartPos" SG_ 268 DAS_Enbl_Rq 7;
BA_ "FlexKomSigLaenge" SG_ 268 DAS_Enbl_Rq 64;
BA_ "FlexKomSigName" SG_ 268 DAS_Enbl_Rq "Eng_Trq_Rq";
BA_ "FlexKomComment" SG_ 268 DAS_Enbl_Rq "Engine torque request from ESC";
BA_ "FlexKomIsMotorola" SG_ 268 DAS_Enbl_Rq 1;
BA_ "GenSigSNA" SG_ 268 DAS_Enbl_Rq "0h";
BA_ "GenSigCycleTime" SG_ 268 EngTrqMax_Rq_ESC 20;
BA_ "FlexKomSigStartValue" SG_ 268 EngTrqMax_Rq_ESC "00000000FF0000FFh";
BA_ "FlexKomSID" SG_ 268 EngTrqMax_Rq_ESC 1;
BA_ "FlexKomSigStartPos" SG_ 268 EngTrqMax_Rq_ESC 7;
BA_ "FlexKomSigLaenge" SG_ 268 EngTrqMax_Rq_ESC 64;
BA_ "FlexKomSigName" SG_ 268 EngTrqMax_Rq_ESC "Eng_Trq_Rq";
BA_ "FlexKomComment" SG_ 268 EngTrqMax_Rq_ESC "Engine torque request from ESC";
BA_ "FlexKomIsMotorola" SG_ 268 EngTrqMax_Rq_ESC 1;
BA_ "GenSigSNA" SG_ 268 EngTrqMax_Rq_ESC "0h";
BA_ "GenSigCycleTime" SG_ 268 EngTrqMin_Rq_ESC 20;
BA_ "FlexKomSigStartValue" SG_ 268 EngTrqMin_Rq_ESC "00000000FF0000FFh";
BA_ "FlexKomSID" SG_ 268 EngTrqMin_Rq_ESC 1;
BA_ "FlexKomSigStartPos" SG_ 268 EngTrqMin_Rq_ESC 7;
BA_ "FlexKomSigLaenge" SG_ 268 EngTrqMin_Rq_ESC 64;
BA_ "FlexKomSigName" SG_ 268 EngTrqMin_Rq_ESC "Eng_Trq_Rq";
BA_ "FlexKomComment" SG_ 268 EngTrqMin_Rq_ESC "Engine torque request from ESC";
BA_ "FlexKomIsMotorola" SG_ 268 EngTrqMin_Rq_ESC 1;
BA_ "GenSigSNA" SG_ 268 EngTrqMin_Rq_ESC "0h";
BA_ "GenSigCycleTime" SG_ 268 EngTrq_Rq_As 20;
BA_ "FlexKomSigStartValue" SG_ 268 EngTrq_Rq_As "00000000FF0000FFh";
BA_ "GenSigTimeout_ORC" SG_ 268 EngTrq_Rq_As 70;
BA_ "FlexKomSID" SG_ 268 EngTrq_Rq_As 1;
BA_ "FlexKomSigStartPos" SG_ 268 EngTrq_Rq_As 7;
BA_ "FlexKomSigLaenge" SG_ 268 EngTrq_Rq_As 64;
BA_ "FlexKomSigName" SG_ 268 EngTrq_Rq_As "Eng_Trq_Rq";
BA_ "FlexKomComment" SG_ 268 EngTrq_Rq_As "Engine torque request from ESC";
BA_ "FlexKomIsMotorola" SG_ 268 EngTrq_Rq_As 1;
BA_ "GenSigSNA" SG_ 268 EngTrq_Rq_As "1FFFh";
BA_ "GenSigCycleTime" SG_ 268 ASRActive 20;
BA_ "FlexKomSigStartValue" SG_ 268 ASRActive "00000000FF0000FFh";
BA_ "FlexKomSID" SG_ 268 ASRActive 1;
BA_ "FlexKomSigStartPos" SG_ 268 ASRActive 7;
BA_ "FlexKomSigLaenge" SG_ 268 ASRActive 64;
BA_ "FlexKomSigName" SG_ 268 ASRActive "Eng_Trq_Rq";
BA_ "FlexKomComment" SG_ 268 ASRActive "Engine torque request from ESC";
BA_ "FlexKomIsMotorola" SG_ 268 ASRActive 1;
BA_ "GenSigSNA" SG_ 268 ASRActive "0h";
BA_ "GenSigCycleTime" SG_ 268 EngTrqMax_Rq_AS 20;
BA_ "FlexKomSigStartValue" SG_ 268 EngTrqMax_Rq_AS "00000000FF0000FFh";
BA_ "FlexKomSID" SG_ 268 EngTrqMax_Rq_AS 1;
BA_ "FlexKomSigStartPos" SG_ 268 EngTrqMax_Rq_AS 7;
BA_ "FlexKomSigLaenge" SG_ 268 EngTrqMax_Rq_AS 64;
BA_ "FlexKomSigName" SG_ 268 EngTrqMax_Rq_AS "Eng_Trq_Rq";
BA_ "FlexKomComment" SG_ 268 EngTrqMax_Rq_AS "Engine torque request from ESC";
BA_ "FlexKomIsMotorola" SG_ 268 EngTrqMax_Rq_AS 1;
BA_ "GenSigSNA" SG_ 268 EngTrqMax_Rq_AS "0h";
BA_ "GenSigCycleTime" SG_ 268 EngTrqMin_Rq_AS 20;
BA_ "FlexKomSigStartValue" SG_ 268 EngTrqMin_Rq_AS "00000000FF0000FFh";
BA_ "FlexKomSID" SG_ 268 EngTrqMin_Rq_AS 1;
BA_ "FlexKomSigStartPos" SG_ 268 EngTrqMin_Rq_AS 7;
BA_ "FlexKomSigLaenge" SG_ 268 EngTrqMin_Rq_AS 64;
BA_ "FlexKomSigName" SG_ 268 EngTrqMin_Rq_AS "Eng_Trq_Rq";
BA_ "FlexKomComment" SG_ 268 EngTrqMin_Rq_AS "Engine torque request from ESC";
BA_ "FlexKomIsMotorola" SG_ 268 EngTrqMin_Rq_AS 1;
BA_ "GenSigSNA" SG_ 268 EngTrqMin_Rq_AS "0h";
BA_ "GenSigCycleTime" SG_ 268 BrkBstrVac 20;
BA_ "FlexKomSigStartValue" SG_ 268 BrkBstrVac "00000000FF0000FFh";
BA_ "GenSigStartValue" SG_ 268 BrkBstrVac 255;
BA_ "GenSigTimeout_ORC" SG_ 268 BrkBstrVac 70;
BA_ "FlexKomSID" SG_ 268 BrkBstrVac 1;
BA_ "FlexKomSigStartPos" SG_ 268 BrkBstrVac 7;
BA_ "FlexKomSigLaenge" SG_ 268 BrkBstrVac 64;
BA_ "FlexKomSigName" SG_ 268 BrkBstrVac "Eng_Trq_Rq";
BA_ "FlexKomComment" SG_ 268 BrkBstrVac "Engine torque request from ESC";
BA_ "FlexKomIsMotorola" SG_ 268 BrkBstrVac 1;
BA_ "GenSigSNA" SG_ 268 BrkBstrVac "FFh";
BA_ "GenSigCycleTime" SG_ 268 PrefillActive 20;
BA_ "FlexKomSigStartValue" SG_ 268 PrefillActive "00000000FF0000FFh";
BA_ "FlexKomSID" SG_ 268 PrefillActive 1;
BA_ "FlexKomSigStartPos" SG_ 268 PrefillActive 7;
BA_ "FlexKomSigLaenge" SG_ 268 PrefillActive 64;
BA_ "FlexKomSigName" SG_ 268 PrefillActive "Eng_Trq_Rq";
BA_ "FlexKomComment" SG_ 268 PrefillActive "Engine torque request from ESC";
BA_ "FlexKomIsMotorola" SG_ 268 PrefillActive 1;
BA_ "GenSigSNA" SG_ 268 PrefillActive "0h";
BA_ "GenSigCycleTime" SG_ 268 TrlrBrkRq 20;
BA_ "FlexKomSigStartValue" SG_ 268 TrlrBrkRq "00000000FF0000FFh";
BA_ "FlexKomSID" SG_ 268 TrlrBrkRq 1;
BA_ "FlexKomSigStartPos" SG_ 268 TrlrBrkRq 7;
BA_ "FlexKomSigLaenge" SG_ 268 TrlrBrkRq 64;
BA_ "FlexKomSigName" SG_ 268 TrlrBrkRq "Eng_Trq_Rq";
BA_ "FlexKomComment" SG_ 268 TrlrBrkRq "Engine torque request from ESC";
BA_ "FlexKomIsMotorola" SG_ 268 TrlrBrkRq 1;
BA_ "GenSigSNA" SG_ 268 TrlrBrkRq "3Fh";
BA_ "GenSigCycleTime" SG_ 268 DsblFuelShutOff 20;
BA_ "FlexKomSigStartValue" SG_ 268 DsblFuelShutOff "00000000FF0000FFh";
BA_ "FlexKomSID" SG_ 268 DsblFuelShutOff 1;
BA_ "FlexKomSigStartPos" SG_ 268 DsblFuelShutOff 7;
BA_ "FlexKomSigLaenge" SG_ 268 DsblFuelShutOff 64;
BA_ "FlexKomSigName" SG_ 268 DsblFuelShutOff "Eng_Trq_Rq";
BA_ "FlexKomComment" SG_ 268 DsblFuelShutOff "Engine torque request from ESC";
BA_ "FlexKomIsMotorola" SG_ 268 DsblFuelShutOff 1;
BA_ "GenSigSNA" SG_ 268 DsblFuelShutOff "0h";
BA_ "GenSigCycleTime" SG_ 268 DAS_RqActv 20;
BA_ "FlexKomSigStartValue" SG_ 268 DAS_RqActv "00000000FF0000FFh";
BA_ "GenSigTimeout_ORC" SG_ 268 DAS_RqActv 70;
BA_ "FlexKomSID" SG_ 268 DAS_RqActv 1;
BA_ "FlexKomSigStartPos" SG_ 268 DAS_RqActv 7;
BA_ "FlexKomSigLaenge" SG_ 268 DAS_RqActv 64;
BA_ "FlexKomSigName" SG_ 268 DAS_RqActv "Eng_Trq_Rq";
BA_ "FlexKomComment" SG_ 268 DAS_RqActv "Engine torque request from ESC";
BA_ "FlexKomIsMotorola" SG_ 268 DAS_RqActv 1;
BA_ "GenSigSNA" SG_ 268 DAS_RqActv "7h";
BA_ "GenSigCycleTime" SG_ 268 Brk_Jrk_Rsp 20;
BA_ "FlexKomSigStartValue" SG_ 268 Brk_Jrk_Rsp "00000000FF0000FFh";
BA_ "GenSigTimeout_ORC" SG_ 268 Brk_Jrk_Rsp 70;
BA_ "FlexKomSID" SG_ 268 Brk_Jrk_Rsp 1;
BA_ "FlexKomSigStartPos" SG_ 268 Brk_Jrk_Rsp 7;
BA_ "FlexKomSigLaenge" SG_ 268 Brk_Jrk_Rsp 64;
BA_ "FlexKomSigName" SG_ 268 Brk_Jrk_Rsp "Eng_Trq_Rq";
BA_ "FlexKomComment" SG_ 268 Brk_Jrk_Rsp "Engine torque request from ESC";
BA_ "FlexKomIsMotorola" SG_ 268 Brk_Jrk_Rsp 1;
BA_ "GenSigSNA" SG_ 268 Brk_Jrk_Rsp "0h";
BA_ "GenSigCycleTime" SG_ 268 MC_ENG_RQ_ESC 20;
BA_ "FlexKomSigStartValue" SG_ 268 MC_ENG_RQ_ESC "00000000FF0000FFh";
BA_ "FlexKomSID" SG_ 268 MC_ENG_RQ_ESC 1;
BA_ "FlexKomSigStartPos" SG_ 268 MC_ENG_RQ_ESC 7;
BA_ "FlexKomSigLaenge" SG_ 268 MC_ENG_RQ_ESC 64;
BA_ "FlexKomSigName" SG_ 268 MC_ENG_RQ_ESC "Eng_Trq_Rq";
BA_ "FlexKomComment" SG_ 268 MC_ENG_RQ_ESC "Engine torque request from ESC";
BA_ "FlexKomIsMotorola" SG_ 268 MC_ENG_RQ_ESC 1;
BA_ "GenSigSNA" SG_ 268 MC_ENG_RQ_ESC "0h";
BA_ "GenSigCycleTime" SG_ 268 CRC_ENG_RQ_ESC 20;
BA_ "FlexKomSigStartValue" SG_ 268 CRC_ENG_RQ_ESC "00000000FF0000FFh";
BA_ "GenSigStartValue" SG_ 268 CRC_ENG_RQ_ESC 255;
BA_ "FlexKomSID" SG_ 268 CRC_ENG_RQ_ESC 1;
BA_ "FlexKomSigStartPos" SG_ 268 CRC_ENG_RQ_ESC 7;
BA_ "FlexKomSigLaenge" SG_ 268 CRC_ENG_RQ_ESC 64;
BA_ "FlexKomSigName" SG_ 268 CRC_ENG_RQ_ESC "Eng_Trq_Rq";
BA_ "FlexKomComment" SG_ 268 CRC_ENG_RQ_ESC "Engine torque request from ESC";
BA_ "FlexKomIsMotorola" SG_ 268 CRC_ENG_RQ_ESC 1;
BA_ "GenSigSNA" SG_ 268 CRC_ENG_RQ_ESC "FFh";
BA_ "GenSigCycleTime" SG_ 269 EngTrq_Rq_SlowESC 20;
BA_ "FlexKomSigStartValue" SG_ 269 EngTrq_Rq_SlowESC "00000000000000FFh";
BA_ "FlexKomSID" SG_ 269 EngTrq_Rq_SlowESC 1680;
BA_ "FlexKomSigStartPos" SG_ 269 EngTrq_Rq_SlowESC 7;
BA_ "FlexKomSigLaenge" SG_ 269 EngTrq_Rq_SlowESC 64;
BA_ "FlexKomSigName" SG_ 269 EngTrq_Rq_SlowESC "Eng_Trq_Rq_M156";
BA_ "FlexKomComment" SG_ 269 EngTrq_Rq_SlowESC "Engine torque request from ESC";
BA_ "FlexKomIsMotorola" SG_ 269 EngTrq_Rq_SlowESC 1;
BA_ "GenSigSNA" SG_ 269 EngTrq_Rq_SlowESC "1FFFh";
BA_ "GenSigCycleTime" SG_ 269 EngTrqMaxSlowESC 20;
BA_ "FlexKomSigStartValue" SG_ 269 EngTrqMaxSlowESC "00000000000000FFh";
BA_ "FlexKomSID" SG_ 269 EngTrqMaxSlowESC 1680;
BA_ "FlexKomSigStartPos" SG_ 269 EngTrqMaxSlowESC 7;
BA_ "FlexKomSigLaenge" SG_ 269 EngTrqMaxSlowESC 64;
BA_ "FlexKomSigName" SG_ 269 EngTrqMaxSlowESC "Eng_Trq_Rq_M156";
BA_ "FlexKomComment" SG_ 269 EngTrqMaxSlowESC "Engine torque request from ESC";
BA_ "FlexKomIsMotorola" SG_ 269 EngTrqMaxSlowESC 1;
BA_ "GenSigSNA" SG_ 269 EngTrqMaxSlowESC "0h";
BA_ "GenSigCycleTime" SG_ 269 EngTrqMinSlowESC 20;
BA_ "FlexKomSigStartValue" SG_ 269 EngTrqMinSlowESC "00000000000000FFh";
BA_ "FlexKomSID" SG_ 269 EngTrqMinSlowESC 1680;
BA_ "FlexKomSigStartPos" SG_ 269 EngTrqMinSlowESC 7;
BA_ "FlexKomSigLaenge" SG_ 269 EngTrqMinSlowESC 64;
BA_ "FlexKomSigName" SG_ 269 EngTrqMinSlowESC "Eng_Trq_Rq_M156";
BA_ "FlexKomComment" SG_ 269 EngTrqMinSlowESC "Engine torque request from ESC";
BA_ "FlexKomIsMotorola" SG_ 269 EngTrqMinSlowESC 1;
BA_ "GenSigSNA" SG_ 269 EngTrqMinSlowESC "0h";
BA_ "GenSigCycleTime" SG_ 269 EngTrq_Rq_FastESC 20;
BA_ "FlexKomSigStartValue" SG_ 269 EngTrq_Rq_FastESC "00000000000000FFh";
BA_ "FlexKomSID" SG_ 269 EngTrq_Rq_FastESC 1680;
BA_ "FlexKomSigStartPos" SG_ 269 EngTrq_Rq_FastESC 7;
BA_ "FlexKomSigLaenge" SG_ 269 EngTrq_Rq_FastESC 64;
BA_ "FlexKomSigName" SG_ 269 EngTrq_Rq_FastESC "Eng_Trq_Rq_M156";
BA_ "FlexKomComment" SG_ 269 EngTrq_Rq_FastESC "Engine torque request from ESC";
BA_ "FlexKomIsMotorola" SG_ 269 EngTrq_Rq_FastESC 1;
BA_ "GenSigSNA" SG_ 269 EngTrq_Rq_FastESC "1FFFh";
BA_ "GenSigCycleTime" SG_ 269 MC_ESP_M156 20;
BA_ "FlexKomSigStartValue" SG_ 269 MC_ESP_M156 "00000000000000FFh";
BA_ "FlexKomSID" SG_ 269 MC_ESP_M156 1680;
BA_ "FlexKomSigStartPos" SG_ 269 MC_ESP_M156 7;
BA_ "FlexKomSigLaenge" SG_ 269 MC_ESP_M156 64;
BA_ "FlexKomSigName" SG_ 269 MC_ESP_M156 "Eng_Trq_Rq_M156";
BA_ "FlexKomComment" SG_ 269 MC_ESP_M156 "Engine torque request from ESC";
BA_ "FlexKomIsMotorola" SG_ 269 MC_ESP_M156 1;
BA_ "GenSigSNA" SG_ 269 MC_ESP_M156 "0h";
BA_ "GenSigCycleTime" SG_ 269 CRC_ESP_M156 20;
BA_ "FlexKomSigStartValue" SG_ 269 CRC_ESP_M156 "00000000000000FFh";
BA_ "GenSigStartValue" SG_ 269 CRC_ESP_M156 255;
BA_ "FlexKomSID" SG_ 269 CRC_ESP_M156 1680;
BA_ "FlexKomSigStartPos" SG_ 269 CRC_ESP_M156 7;
BA_ "FlexKomSigLaenge" SG_ 269 CRC_ESP_M156 64;
BA_ "FlexKomSigName" SG_ 269 CRC_ESP_M156 "Eng_Trq_Rq_M156";
BA_ "FlexKomComment" SG_ 269 CRC_ESP_M156 "Engine torque request from ESC";
BA_ "FlexKomIsMotorola" SG_ 269 CRC_ESP_M156 1;
BA_ "GenSigSNA" SG_ 269 CRC_ESP_M156 "FFh";
BA_ "GenSigSendType" SG_ 272 SEED_REQUEST 1;
BA_ "FlexKomSigStartValue" SG_ 272 SEED_REQUEST "00h";
BA_ "FlexKomSID" SG_ 272 SEED_REQUEST 1045;
BA_ "FlexKomSigLaenge" SG_ 272 SEED_REQUEST 1;
BA_ "FlexKomSigName" SG_ 272 SEED_REQUEST "SEED_REQUEST";
BA_ "FlexKomComment" SG_ 272 SEED_REQUEST "SKIM seed request to ECM";
BA_ "FlexKomIsMotorola" SG_ 272 SEED_REQUEST 1;
BA_ "GenSigSNA" SG_ 272 SEED_REQUEST "0h";
BA_ "GenSigSendType" SG_ 273 SKIM_DATA1 1;
BA_ "FlexKomSigStartValue" SG_ 273 SKIM_DATA1 "FFFFFFh";
BA_ "GenSigStartValue" SG_ 273 SKIM_DATA1 255;
BA_ "FlexKomSID" SG_ 273 SKIM_DATA1 1044;
BA_ "FlexKomSigStartPos" SG_ 273 SKIM_DATA1 7;
BA_ "FlexKomSigLaenge" SG_ 273 SKIM_DATA1 24;
BA_ "FlexKomSigName" SG_ 273 SKIM_DATA1 "SKIM_DATA";
BA_ "FlexKomComment" SG_ 273 SKIM_DATA1 "SKIM message to ECM";
BA_ "FlexKomIsMotorola" SG_ 273 SKIM_DATA1 1;
BA_ "GenSigSNA" SG_ 273 SKIM_DATA1 "FFh";
BA_ "GenSigSendType" SG_ 273 SKIM_DATA2 1;
BA_ "FlexKomSigStartValue" SG_ 273 SKIM_DATA2 "FFFFFFh";
BA_ "GenSigStartValue" SG_ 273 SKIM_DATA2 255;
BA_ "FlexKomSID" SG_ 273 SKIM_DATA2 1044;
BA_ "FlexKomSigStartPos" SG_ 273 SKIM_DATA2 7;
BA_ "FlexKomSigLaenge" SG_ 273 SKIM_DATA2 24;
BA_ "FlexKomSigName" SG_ 273 SKIM_DATA2 "SKIM_DATA";
BA_ "FlexKomComment" SG_ 273 SKIM_DATA2 "SKIM message to ECM";
BA_ "FlexKomIsMotorola" SG_ 273 SKIM_DATA2 1;
BA_ "GenSigSNA" SG_ 273 SKIM_DATA2 "FFh";
BA_ "GenSigSendType" SG_ 273 SKIM_DATA3 1;
BA_ "FlexKomSigStartValue" SG_ 273 SKIM_DATA3 "FFFFFFh";
BA_ "GenSigStartValue" SG_ 273 SKIM_DATA3 255;
BA_ "FlexKomSID" SG_ 273 SKIM_DATA3 1044;
BA_ "FlexKomSigStartPos" SG_ 273 SKIM_DATA3 7;
BA_ "FlexKomSigLaenge" SG_ 273 SKIM_DATA3 24;
BA_ "FlexKomSigName" SG_ 273 SKIM_DATA3 "SKIM_DATA";
BA_ "FlexKomComment" SG_ 273 SKIM_DATA3 "SKIM message to ECM";
BA_ "FlexKomIsMotorola" SG_ 273 SKIM_DATA3 1;
BA_ "GenSigSNA" SG_ 273 SKIM_DATA3 "FFh";
BA_ "GenSigSendType" SG_ 273 FOB_SafAlert 1;
BA_ "FlexKomSigStartValue" SG_ 273 FOB_SafAlert "00h";
BA_ "FlexKomSID" SG_ 273 FOB_SafAlert 1027;
BA_ "FlexKomSigStartPos" SG_ 273 FOB_SafAlert 25;
BA_ "FlexKomSigLaenge" SG_ 273 FOB_SafAlert 1;
BA_ "FlexKomSigName" SG_ 273 FOB_SafAlert "FOB_SafAlert";
BA_ "FlexKomComment" SG_ 273 FOB_SafAlert "Request to perform FOBIK-Safe alert (1=Perform ale";
BA_ "FlexKomIsMotorola" SG_ 273 FOB_SafAlert 1;
BA_ "GenSigSNA" SG_ 273 FOB_SafAlert "0h";
BA_ "GenSigCycleTime" SG_ 274 CmdIgnStat 20;
BA_ "FlexKomSigStartValue" SG_ 274 CmdIgnStat "0000h";
BA_ "GenSigTimeout_IC" SG_ 274 CmdIgnStat 210;
BA_ "GenSigTimeout_PTS" SG_ 274 CmdIgnStat 210;
BA_ "GenSigTimeout_TPM" SG_ 274 CmdIgnStat 210;
BA_ "GenSigTimeout_AFLS" SG_ 274 CmdIgnStat 410;
BA_ "GenSigTimeout_EPS" SG_ 274 CmdIgnStat 210;
BA_ "GenSigTimeout_SCCM" SG_ 274 CmdIgnStat 210;
BA_ "GenSigTimeout_ESM" SG_ 274 CmdIgnStat 310;
BA_ "GenSigTimeout_ADCM" SG_ 274 CmdIgnStat 510;
BA_ "GenSigTimeout_ORC" SG_ 274 CmdIgnStat 70;
BA_ "FlexKomSID" SG_ 274 CmdIgnStat 880;
BA_ "FlexKomSigStartPos" SG_ 274 CmdIgnStat 7;
BA_ "FlexKomSigLaenge" SG_ 274 CmdIgnStat 16;
BA_ "FlexKomSigName" SG_ 274 CmdIgnStat "VehStart_PKT";
BA_ "FlexKomComment" SG_ 274 CmdIgnStat "Vehicle start packet";
BA_ "FlexKomIsMotorola" SG_ 274 CmdIgnStat 1;
BA_ "GenSigSNA" SG_ 274 CmdIgnStat "7h";
BA_ "GenSigCycleTime" SG_ 274 StTyp 20;
BA_ "FlexKomSigStartValue" SG_ 274 StTyp "0000h";
BA_ "GenSigTimeout_IC" SG_ 274 StTyp 210;
BA_ "GenSigTimeout_TPM" SG_ 274 StTyp 210;
BA_ "GenSigTimeout_ORC" SG_ 274 StTyp 70;
BA_ "FlexKomSID" SG_ 274 StTyp 880;
BA_ "FlexKomSigStartPos" SG_ 274 StTyp 7;
BA_ "FlexKomSigLaenge" SG_ 274 StTyp 16;
BA_ "FlexKomSigName" SG_ 274 StTyp "VehStart_PKT";
BA_ "FlexKomComment" SG_ 274 StTyp "Vehicle start packet";
BA_ "FlexKomIsMotorola" SG_ 274 StTyp 1;
BA_ "GenSigSNA" SG_ 274 StTyp "7h";
BA_ "GenSigCycleTime" SG_ 274 RemStActv 20;
BA_ "FlexKomSigStartValue" SG_ 274 RemStActv "0000h";
BA_ "GenSigTimeout_IC" SG_ 274 RemStActv 210;
BA_ "GenSigTimeout_TPM" SG_ 274 RemStActv 210;
BA_ "GenSigTimeout_ESM" SG_ 274 RemStActv 310;
BA_ "GenSigTimeout_ORC" SG_ 274 RemStActv 70;
BA_ "FlexKomSID" SG_ 274 RemStActv 880;
BA_ "FlexKomSigStartPos" SG_ 274 RemStActv 7;
BA_ "FlexKomSigLaenge" SG_ 274 RemStActv 16;
BA_ "FlexKomSigName" SG_ 274 RemStActv "VehStart_PKT";
BA_ "FlexKomComment" SG_ 274 RemStActv "Vehicle start packet";
BA_ "FlexKomIsMotorola" SG_ 274 RemStActv 1;
BA_ "GenSigSNA" SG_ 274 RemStActv "0h";
BA_ "GenSigCycleTime" SG_ 274 RedKeyPrsnt 20;
BA_ "FlexKomSigStartValue" SG_ 274 RedKeyPrsnt "0000h";
BA_ "GenSigTimeout_ETM" SG_ 274 RedKeyPrsnt 210;
BA_ "FlexKomSID" SG_ 274 RedKeyPrsnt 880;
BA_ "FlexKomSigStartPos" SG_ 274 RedKeyPrsnt 7;
BA_ "FlexKomSigLaenge" SG_ 274 RedKeyPrsnt 16;
BA_ "FlexKomSigName" SG_ 274 RedKeyPrsnt "VehStart_PKT";
BA_ "FlexKomComment" SG_ 274 RedKeyPrsnt "Vehicle start packet";
BA_ "FlexKomIsMotorola" SG_ 274 RedKeyPrsnt 1;
BA_ "GenSigSNA" SG_ 274 RedKeyPrsnt "0h";
BA_ "GenSigCycleTime" SG_ 274 KeyInIgn 20;
BA_ "FlexKomSigStartValue" SG_ 274 KeyInIgn "0000h";
BA_ "GenSigTimeout_IC" SG_ 274 KeyInIgn 210;
BA_ "GenSigTimeout_TPM" SG_ 274 KeyInIgn 210;
BA_ "GenSigTimeout_ORC" SG_ 274 KeyInIgn 70;
BA_ "FlexKomSID" SG_ 274 KeyInIgn 880;
BA_ "FlexKomSigStartPos" SG_ 274 KeyInIgn 7;
BA_ "FlexKomSigLaenge" SG_ 274 KeyInIgn 16;
BA_ "FlexKomSigName" SG_ 274 KeyInIgn "VehStart_PKT";
BA_ "FlexKomComment" SG_ 274 KeyInIgn "Vehicle start packet";
BA_ "FlexKomIsMotorola" SG_ 274 KeyInIgn 1;
BA_ "GenSigSNA" SG_ 274 KeyInIgn "3h";
BA_ "GenSigCycleTime" SG_ 274 OD_SW_PSD 20;
BA_ "FlexKomSigStartValue" SG_ 274 OD_SW_PSD "00h";
BA_ "FlexKomSID" SG_ 274 OD_SW_PSD 449;
BA_ "FlexKomSigStartPos" SG_ 274 OD_SW_PSD 10;
BA_ "FlexKomSigLaenge" SG_ 274 OD_SW_PSD 1;
BA_ "FlexKomSigName" SG_ 274 OD_SW_PSD "OD_SW_PSD";
BA_ "FlexKomComment" SG_ 274 OD_SW_PSD "Overdrive Switch Pressed; [0] = not pressed, [1] =";
BA_ "FlexKomIsMotorola" SG_ 274 OD_SW_PSD 1;
BA_ "GenSigSNA" SG_ 274 OD_SW_PSD "0h";
BA_ "GenSigCycleTime" SG_ 274 ERS_SW 20;
BA_ "FlexKomSigStartValue" SG_ 274 ERS_SW "00h";
BA_ "FlexKomSID" SG_ 274 ERS_SW 1203;
BA_ "FlexKomSigStartPos" SG_ 274 ERS_SW 12;
BA_ "FlexKomSigLaenge" SG_ 274 ERS_SW 2;
BA_ "FlexKomSigName" SG_ 274 ERS_SW "ERS_SW";
BA_ "FlexKomComment" SG_ 274 ERS_SW "ERS Switch Status";
BA_ "FlexKomIsMotorola" SG_ 274 ERS_SW 1;
BA_ "GenSigSNA" SG_ 274 ERS_SW "3h";
BA_ "GenSigCycleTime" SG_ 274 StartRelayBCMSts 20;
BA_ "FlexKomSigStartValue" SG_ 274 StartRelayBCMSts "00h";
BA_ "FlexKomSID" SG_ 274 StartRelayBCMSts 1526;
BA_ "FlexKomSigStartPos" SG_ 274 StartRelayBCMSts 13;
BA_ "FlexKomSigLaenge" SG_ 274 StartRelayBCMSts 1;
BA_ "FlexKomSigName" SG_ 274 StartRelayBCMSts "StartRelayBCMSts";
BA_ "FlexKomComment" SG_ 274 StartRelayBCMSts "CBC starter relay status; [1] = ON";
BA_ "FlexKomIsMotorola" SG_ 274 StartRelayBCMSts 1;
BA_ "GenSigSNA" SG_ 274 StartRelayBCMSts "0h";
BA_ "GenSigCycleTime" SG_ 274 StartRelayBCMFault 20;
BA_ "FlexKomSigStartValue" SG_ 274 StartRelayBCMFault "00h";
BA_ "GenSigTimeout_ORC" SG_ 274 StartRelayBCMFault 70;
BA_ "FlexKomSID" SG_ 274 StartRelayBCMFault 1573;
BA_ "FlexKomSigStartPos" SG_ 274 StartRelayBCMFault 14;
BA_ "FlexKomSigLaenge" SG_ 274 StartRelayBCMFault 1;
BA_ "FlexKomSigName" SG_ 274 StartRelayBCMFault "StartRelayBCMFault";
BA_ "FlexKomComment" SG_ 274 StartRelayBCMFault "CBC starter relay fault detected";
BA_ "FlexKomIsMotorola" SG_ 274 StartRelayBCMFault 1;
BA_ "GenSigSNA" SG_ 274 StartRelayBCMFault "0h";
BA_ "GenSigCycleTime" SG_ 274 TeenKeyPrsnt 20;
BA_ "FlexKomSigStartValue" SG_ 274 TeenKeyPrsnt "0000h";
BA_ "GenSigTimeout_ETM" SG_ 274 TeenKeyPrsnt 210;
BA_ "FlexKomSID" SG_ 274 TeenKeyPrsnt 880;
BA_ "FlexKomSigStartPos" SG_ 274 TeenKeyPrsnt 7;
BA_ "FlexKomSigLaenge" SG_ 274 TeenKeyPrsnt 16;
BA_ "FlexKomSigName" SG_ 274 TeenKeyPrsnt "VehStart_PKT";
BA_ "FlexKomComment" SG_ 274 TeenKeyPrsnt "Vehicle start packet";
BA_ "FlexKomIsMotorola" SG_ 274 TeenKeyPrsnt 1;
BA_ "GenSigSNA" SG_ 274 TeenKeyPrsnt "0h";
BA_ "GenSigCycleTime" SG_ 280 EngTrqMax 10;
BA_ "FlexKomSigStartValue" SG_ 280 EngTrqMax "9FFF1FFF1FFF00FFh";
BA_ "GenSigStartValue" SG_ 280 EngTrqMax 8191;
BA_ "GenSigTimeout_IC" SG_ 280 EngTrqMax 105;
BA_ "FlexKomSID" SG_ 280 EngTrqMax 1853;
BA_ "FlexKomSigStartPos" SG_ 280 EngTrqMax 7;
BA_ "FlexKomSigLaenge" SG_ 280 EngTrqMax 64;
BA_ "FlexKomSigName" SG_ 280 EngTrqMax "ECM_ENG_TRQ_Pkt";
BA_ "FlexKomComment" SG_ 280 EngTrqMax "ECM_ENG_TRQ packet";
BA_ "FlexKomIsMotorola" SG_ 280 EngTrqMax 1;
BA_ "GenSigSNA" SG_ 280 EngTrqMax "1FFFh";
BA_ "GenSigCycleTime" SG_ 280 ANL_LFT 10;
BA_ "FlexKomSigStartValue" SG_ 280 ANL_LFT "9FFF1FFF1FFF00FFh";
BA_ "GenSigTimeout_CBC" SG_ 280 ANL_LFT 105;
BA_ "FlexKomSID" SG_ 280 ANL_LFT 1853;
BA_ "FlexKomSigStartPos" SG_ 280 ANL_LFT 7;
BA_ "FlexKomSigLaenge" SG_ 280 ANL_LFT 64;
BA_ "FlexKomSigName" SG_ 280 ANL_LFT "ECM_ENG_TRQ_Pkt";
BA_ "FlexKomComment" SG_ 280 ANL_LFT "ECM_ENG_TRQ packet";
BA_ "FlexKomIsMotorola" SG_ 280 ANL_LFT 1;
BA_ "GenSigSNA" SG_ 280 ANL_LFT "0h";
BA_ "GenSigCycleTime" SG_ 280 Clutch_Disengg 10;
BA_ "FlexKomSigStartValue" SG_ 280 Clutch_Disengg "9FFF1FFF1FFF00FFh";
BA_ "GenSigTimeout_ORC" SG_ 280 Clutch_Disengg 35;
BA_ "FlexKomSID" SG_ 280 Clutch_Disengg 1853;
BA_ "FlexKomSigStartPos" SG_ 280 Clutch_Disengg 7;
BA_ "FlexKomSigLaenge" SG_ 280 Clutch_Disengg 64;
BA_ "FlexKomSigName" SG_ 280 Clutch_Disengg "ECM_ENG_TRQ_Pkt";
BA_ "FlexKomComment" SG_ 280 Clutch_Disengg "ECM_ENG_TRQ packet";
BA_ "FlexKomIsMotorola" SG_ 280 Clutch_Disengg 1;
BA_ "GenSigSNA" SG_ 280 Clutch_Disengg "0h";
BA_ "GenSigCycleTime" SG_ 280 ClutchInterLk 10;
BA_ "FlexKomSigStartValue" SG_ 280 ClutchInterLk "9FFF1FFF1FFF00FFh";
BA_ "GenSigStartValue" SG_ 280 ClutchInterLk 1;
BA_ "GenSigTimeout_DTCM" SG_ 280 ClutchInterLk 105;
BA_ "GenSigTimeout_ORC" SG_ 280 ClutchInterLk 35;
BA_ "FlexKomSID" SG_ 280 ClutchInterLk 1853;
BA_ "FlexKomSigStartPos" SG_ 280 ClutchInterLk 7;
BA_ "FlexKomSigLaenge" SG_ 280 ClutchInterLk 64;
BA_ "FlexKomSigName" SG_ 280 ClutchInterLk "ECM_ENG_TRQ_Pkt";
BA_ "FlexKomComment" SG_ 280 ClutchInterLk "ECM_ENG_TRQ packet";
BA_ "FlexKomIsMotorola" SG_ 280 ClutchInterLk 1;
BA_ "GenSigSNA" SG_ 280 ClutchInterLk "1h";
BA_ "GenSigCycleTime" SG_ 280 EngTrqMin 10;
BA_ "FlexKomSigStartValue" SG_ 280 EngTrqMin "9FFF1FFF1FFF00FFh";
BA_ "GenSigStartValue" SG_ 280 EngTrqMin 8191;
BA_ "GenSigTimeout_IC" SG_ 280 EngTrqMin 105;
BA_ "FlexKomSID" SG_ 280 EngTrqMin 1853;
BA_ "FlexKomSigStartPos" SG_ 280 EngTrqMin 7;
BA_ "FlexKomSigLaenge" SG_ 280 EngTrqMin 64;
BA_ "FlexKomSigName" SG_ 280 EngTrqMin "ECM_ENG_TRQ_Pkt";
BA_ "FlexKomComment" SG_ 280 EngTrqMin "ECM_ENG_TRQ packet";
BA_ "FlexKomIsMotorola" SG_ 280 EngTrqMin 1;
BA_ "GenSigSNA" SG_ 280 EngTrqMin "1FFFh";
BA_ "GenSigCycleTime" SG_ 280 MdsAct 10;
BA_ "FlexKomSigStartValue" SG_ 280 MdsAct "9FFF1FFF1FFF00FFh";
BA_ "GenSigTimeout_IC" SG_ 280 MdsAct 105;
BA_ "FlexKomSID" SG_ 280 MdsAct 1853;
BA_ "FlexKomSigStartPos" SG_ 280 MdsAct 7;
BA_ "FlexKomSigLaenge" SG_ 280 MdsAct 64;
BA_ "FlexKomSigName" SG_ 280 MdsAct "ECM_ENG_TRQ_Pkt";
BA_ "FlexKomComment" SG_ 280 MdsAct "ECM_ENG_TRQ packet";
BA_ "FlexKomIsMotorola" SG_ 280 MdsAct 1;
BA_ "GenSigSNA" SG_ 280 MdsAct "0h";
BA_ "GenSigCycleTime" SG_ 280 FullOFC_Actv 10;
BA_ "FlexKomSigStartValue" SG_ 280 FullOFC_Actv "9FFF1FFF1FFF00FFh";
BA_ "FlexKomSID" SG_ 280 FullOFC_Actv 1853;
BA_ "FlexKomSigStartPos" SG_ 280 FullOFC_Actv 7;
BA_ "FlexKomSigLaenge" SG_ 280 FullOFC_Actv 64;
BA_ "FlexKomSigName" SG_ 280 FullOFC_Actv "ECM_ENG_TRQ_Pkt";
BA_ "FlexKomComment" SG_ 280 FullOFC_Actv "ECM_ENG_TRQ packet";
BA_ "FlexKomIsMotorola" SG_ 280 FullOFC_Actv 1;
BA_ "GenSigSNA" SG_ 280 FullOFC_Actv "0h";
BA_ "GenSigCycleTime" SG_ 280 CYL_CUT_POSS 10;
BA_ "FlexKomSigStartValue" SG_ 280 CYL_CUT_POSS "9FFF1FFF1FFF00FFh";
BA_ "FlexKomSID" SG_ 280 CYL_CUT_POSS 1853;
BA_ "FlexKomSigStartPos" SG_ 280 CYL_CUT_POSS 7;
BA_ "FlexKomSigLaenge" SG_ 280 CYL_CUT_POSS 64;
BA_ "FlexKomSigName" SG_ 280 CYL_CUT_POSS "ECM_ENG_TRQ_Pkt";
BA_ "FlexKomComment" SG_ 280 CYL_CUT_POSS "ECM_ENG_TRQ packet";
BA_ "FlexKomIsMotorola" SG_ 280 CYL_CUT_POSS 1;
BA_ "GenSigSNA" SG_ 280 CYL_CUT_POSS "0h";
BA_ "GenSigCycleTime" SG_ 280 M_EFF 10;
BA_ "FlexKomSigStartValue" SG_ 280 M_EFF "9FFF1FFF1FFF00FFh";
BA_ "GenSigStartValue" SG_ 280 M_EFF 8191;
BA_ "FlexKomSID" SG_ 280 M_EFF 1853;
BA_ "FlexKomSigStartPos" SG_ 280 M_EFF 7;
BA_ "FlexKomSigLaenge" SG_ 280 M_EFF 64;
BA_ "FlexKomSigName" SG_ 280 M_EFF "ECM_ENG_TRQ_Pkt";
BA_ "FlexKomComment" SG_ 280 M_EFF "ECM_ENG_TRQ packet";
BA_ "FlexKomIsMotorola" SG_ 280 M_EFF 1;
BA_ "GenSigSNA" SG_ 280 M_EFF "1FFFh";
BA_ "GenSigCycleTime" SG_ 280 TACH_FREEZE 10;
BA_ "FlexKomSigStartValue" SG_ 280 TACH_FREEZE "9FFF1FFF1FFF00FFh";
BA_ "GenSigTimeout_IC" SG_ 280 TACH_FREEZE 105;
BA_ "FlexKomSID" SG_ 280 TACH_FREEZE 1853;
BA_ "FlexKomSigStartPos" SG_ 280 TACH_FREEZE 7;
BA_ "FlexKomSigLaenge" SG_ 280 TACH_FREEZE 64;
BA_ "FlexKomSigName" SG_ 280 TACH_FREEZE "ECM_ENG_TRQ_Pkt";
BA_ "FlexKomComment" SG_ 280 TACH_FREEZE "ECM_ENG_TRQ packet";
BA_ "FlexKomIsMotorola" SG_ 280 TACH_FREEZE 1;
BA_ "GenSigSNA" SG_ 280 TACH_FREEZE "0h";
BA_ "GenSigCycleTime" SG_ 280 StartRelayBCMCmd 10;
BA_ "FlexKomSigStartValue" SG_ 280 StartRelayBCMCmd "9FFF1FFF1FFF00FFh";
BA_ "FlexKomSID" SG_ 280 StartRelayBCMCmd 1853;
BA_ "FlexKomSigStartPos" SG_ 280 StartRelayBCMCmd 7;
BA_ "FlexKomSigLaenge" SG_ 280 StartRelayBCMCmd 64;
BA_ "FlexKomSigName" SG_ 280 StartRelayBCMCmd "ECM_ENG_TRQ_Pkt";
BA_ "FlexKomComment" SG_ 280 StartRelayBCMCmd "ECM_ENG_TRQ packet";
BA_ "FlexKomIsMotorola" SG_ 280 StartRelayBCMCmd 1;
BA_ "GenSigSNA" SG_ 280 StartRelayBCMCmd "0h";
BA_ "GenSigCycleTime" SG_ 280 MC_ECM_ENG_TRQ 10;
BA_ "FlexKomSigStartValue" SG_ 280 MC_ECM_ENG_TRQ "9FFF1FFF1FFF00FFh";
BA_ "FlexKomSID" SG_ 280 MC_ECM_ENG_TRQ 1853;
BA_ "FlexKomSigStartPos" SG_ 280 MC_ECM_ENG_TRQ 7;
BA_ "FlexKomSigLaenge" SG_ 280 MC_ECM_ENG_TRQ 64;
BA_ "FlexKomSigName" SG_ 280 MC_ECM_ENG_TRQ "ECM_ENG_TRQ_Pkt";
BA_ "FlexKomComment" SG_ 280 MC_ECM_ENG_TRQ "ECM_ENG_TRQ packet";
BA_ "FlexKomIsMotorola" SG_ 280 MC_ECM_ENG_TRQ 1;
BA_ "GenSigSNA" SG_ 280 MC_ECM_ENG_TRQ "0h";
BA_ "GenSigCycleTime" SG_ 280 CRC_ECM_ENG_TRQ 10;
BA_ "FlexKomSigStartValue" SG_ 280 CRC_ECM_ENG_TRQ "9FFF1FFF1FFF00FFh";
BA_ "GenSigStartValue" SG_ 280 CRC_ECM_ENG_TRQ 255;
BA_ "FlexKomSID" SG_ 280 CRC_ECM_ENG_TRQ 1853;
BA_ "FlexKomSigStartPos" SG_ 280 CRC_ECM_ENG_TRQ 7;
BA_ "FlexKomSigLaenge" SG_ 280 CRC_ECM_ENG_TRQ 64;
BA_ "FlexKomSigName" SG_ 280 CRC_ECM_ENG_TRQ "ECM_ENG_TRQ_Pkt";
BA_ "FlexKomComment" SG_ 280 CRC_ECM_ENG_TRQ "ECM_ENG_TRQ packet";
BA_ "FlexKomIsMotorola" SG_ 280 CRC_ECM_ENG_TRQ 1;
BA_ "GenSigSNA" SG_ 280 CRC_ECM_ENG_TRQ "FFh";
BA_ "GenSigCycleTime" SG_ 284 BrkTrq 20;
BA_ "FlexKomSigStartValue" SG_ 284 BrkTrq "0FFF0FFFFFFF00FFh";
BA_ "GenSigStartValue" SG_ 284 BrkTrq 4095;
BA_ "GenSigTimeout_CBC" SG_ 284 BrkTrq 210;
BA_ "GenSigTimeout_ADCM" SG_ 284 BrkTrq 510;
BA_ "FlexKomSID" SG_ 284 BrkTrq 11;
BA_ "FlexKomSigStartPos" SG_ 284 BrkTrq 7;
BA_ "FlexKomSigLaenge" SG_ 284 BrkTrq 64;
BA_ "FlexKomSigName" SG_ 284 BrkTrq "VEH_SPEED_PKT";
BA_ "FlexKomComment" SG_ 284 BrkTrq "Vehicle Speed Packet";
BA_ "FlexKomIsMotorola" SG_ 284 BrkTrq 1;
BA_ "GenSigSNA" SG_ 284 BrkTrq "FFFh";
BA_ "GenSigCycleTime" SG_ 284 VehSpSts 20;
BA_ "FlexKomSigStartValue" SG_ 284 VehSpSts "0FFF0FFFFFFF00FFh";
BA_ "FlexKomSID" SG_ 284 VehSpSts 11;
BA_ "FlexKomSigStartPos" SG_ 284 VehSpSts 7;
BA_ "FlexKomSigLaenge" SG_ 284 VehSpSts 64;
BA_ "FlexKomSigName" SG_ 284 VehSpSts "VEH_SPEED_PKT";
BA_ "FlexKomComment" SG_ 284 VehSpSts "Vehicle Speed Packet";
BA_ "FlexKomIsMotorola" SG_ 284 VehSpSts 1;
BA_ "GenSigSNA" SG_ 284 VehSpSts "0h";
BA_ "GenSigCycleTime" SG_ 284 BrkTrq_D 20;
BA_ "FlexKomSigStartValue" SG_ 284 BrkTrq_D "0FFF0FFFFFFF00FFh";
BA_ "GenSigStartValue" SG_ 284 BrkTrq_D 4095;
BA_ "GenSigTimeout_ADCM" SG_ 284 BrkTrq_D 510;
BA_ "FlexKomSID" SG_ 284 BrkTrq_D 11;
BA_ "FlexKomSigStartPos" SG_ 284 BrkTrq_D 7;
BA_ "FlexKomSigLaenge" SG_ 284 BrkTrq_D 64;
BA_ "FlexKomSigName" SG_ 284 BrkTrq_D "VEH_SPEED_PKT";
BA_ "FlexKomComment" SG_ 284 BrkTrq_D "Vehicle Speed Packet";
BA_ "FlexKomIsMotorola" SG_ 284 BrkTrq_D 1;
BA_ "GenSigSNA" SG_ 284 BrkTrq_D "FFFh";
BA_ "GenSigCycleTime" SG_ 284 VEH_SPEED 20;
BA_ "FlexKomSigStartValue" SG_ 284 VEH_SPEED "0FFF0FFFFFFF00FFh";
BA_ "GenSigStartValue" SG_ 284 VEH_SPEED 65535;
BA_ "GenSigTimeout_RF_HUB" SG_ 284 VEH_SPEED 210;
BA_ "GenSigTimeout_CBC" SG_ 284 VEH_SPEED 110;
BA_ "GenSigTimeout_IC" SG_ 284 VEH_SPEED 210;
BA_ "GenSigTimeout_TPM" SG_ 284 VEH_SPEED 210;
BA_ "GenSigTimeout_AFLS" SG_ 284 VEH_SPEED 410;
BA_ "GenSigTimeout_EPS" SG_ 284 VEH_SPEED 210;
BA_ "GenSigTimeout_ESM" SG_ 284 VEH_SPEED 210;
BA_ "GenSigTimeout_DTCM" SG_ 284 VEH_SPEED 210;
BA_ "GenSigTimeout_ADCM" SG_ 284 VEH_SPEED 510;
BA_ "GenSigTimeout_ORC" SG_ 284 VEH_SPEED 70;
BA_ "FlexKomSID" SG_ 284 VEH_SPEED 11;
BA_ "FlexKomSigStartPos" SG_ 284 VEH_SPEED 7;
BA_ "FlexKomSigLaenge" SG_ 284 VEH_SPEED 64;
BA_ "FlexKomSigName" SG_ 284 VEH_SPEED "VEH_SPEED_PKT";
BA_ "FlexKomComment" SG_ 284 VEH_SPEED "Vehicle Speed Packet";
BA_ "FlexKomIsMotorola" SG_ 284 VEH_SPEED 1;
BA_ "GenSigSNA" SG_ 284 VEH_SPEED "FFFFh";
BA_ "GenSigCycleTime" SG_ 284 MC_VEH_SPEED 20;
BA_ "FlexKomSigStartValue" SG_ 284 MC_VEH_SPEED "0FFF0FFFFFFF00FFh";
BA_ "GenSigTimeout_CBC" SG_ 284 MC_VEH_SPEED 110;
BA_ "GenSigTimeout_IC" SG_ 284 MC_VEH_SPEED 210;
BA_ "GenSigTimeout_TPM" SG_ 284 MC_VEH_SPEED 210;
BA_ "GenSigTimeout_ESM" SG_ 284 MC_VEH_SPEED 210;
BA_ "GenSigTimeout_ORC" SG_ 284 MC_VEH_SPEED 70;
BA_ "FlexKomSID" SG_ 284 MC_VEH_SPEED 11;
BA_ "FlexKomSigStartPos" SG_ 284 MC_VEH_SPEED 7;
BA_ "FlexKomSigLaenge" SG_ 284 MC_VEH_SPEED 64;
BA_ "FlexKomSigName" SG_ 284 MC_VEH_SPEED "VEH_SPEED_PKT";
BA_ "FlexKomComment" SG_ 284 MC_VEH_SPEED "Vehicle Speed Packet";
BA_ "FlexKomIsMotorola" SG_ 284 MC_VEH_SPEED 1;
BA_ "GenSigSNA" SG_ 284 MC_VEH_SPEED "0h";
BA_ "GenSigCycleTime" SG_ 284 CRC_VEH_SPEED 20;
BA_ "FlexKomSigStartValue" SG_ 284 CRC_VEH_SPEED "0FFF0FFFFFFF00FFh";
BA_ "GenSigStartValue" SG_ 284 CRC_VEH_SPEED 255;
BA_ "GenSigTimeout_CBC" SG_ 284 CRC_VEH_SPEED 110;
BA_ "GenSigTimeout_IC" SG_ 284 CRC_VEH_SPEED 210;
BA_ "GenSigTimeout_TPM" SG_ 284 CRC_VEH_SPEED 210;
BA_ "GenSigTimeout_ESM" SG_ 284 CRC_VEH_SPEED 210;
BA_ "GenSigTimeout_ORC" SG_ 284 CRC_VEH_SPEED 70;
BA_ "FlexKomSID" SG_ 284 CRC_VEH_SPEED 11;
BA_ "FlexKomSigStartPos" SG_ 284 CRC_VEH_SPEED 7;
BA_ "FlexKomSigLaenge" SG_ 284 CRC_VEH_SPEED 64;
BA_ "FlexKomSigName" SG_ 284 CRC_VEH_SPEED "VEH_SPEED_PKT";
BA_ "FlexKomComment" SG_ 284 CRC_VEH_SPEED "Vehicle Speed Packet";
BA_ "FlexKomIsMotorola" SG_ 284 CRC_VEH_SPEED 1;
BA_ "GenSigSNA" SG_ 284 CRC_VEH_SPEED "FFh";
BA_ "GenSigCycleTime" SG_ 288 EngTrqSel_D_TTC 20;
BA_ "FlexKomSigStartValue" SG_ 288 EngTrqSel_D_TTC "1FFFFF1FFF00FFh";
BA_ "GenSigStartValue" SG_ 288 EngTrqSel_D_TTC 8191;
BA_ "FlexKomSID" SG_ 288 EngTrqSel_D_TTC 455;
BA_ "FlexKomSigStartPos" SG_ 288 EngTrqSel_D_TTC 7;
BA_ "FlexKomSigLaenge" SG_ 288 EngTrqSel_D_TTC 56;
BA_ "FlexKomSigName" SG_ 288 EngTrqSel_D_TTC "ECM_A2_PKT";
BA_ "FlexKomComment" SG_ 288 EngTrqSel_D_TTC "ECM_A2 Packet";
BA_ "FlexKomIsMotorola" SG_ 288 EngTrqSel_D_TTC 1;
BA_ "GenSigSNA" SG_ 288 EngTrqSel_D_TTC "1FFFh";
BA_ "GenSigCycleTime" SG_ 288 EngTrq_Enbl_Rq_AS 20;
BA_ "FlexKomSigStartValue" SG_ 288 EngTrq_Enbl_Rq_AS "1FFFFF1FFF00FFh";
BA_ "FlexKomSID" SG_ 288 EngTrq_Enbl_Rq_AS 455;
BA_ "FlexKomSigStartPos" SG_ 288 EngTrq_Enbl_Rq_AS 7;
BA_ "FlexKomSigLaenge" SG_ 288 EngTrq_Enbl_Rq_AS 56;
BA_ "FlexKomSigName" SG_ 288 EngTrq_Enbl_Rq_AS "ECM_A2_PKT";
BA_ "FlexKomComment" SG_ 288 EngTrq_Enbl_Rq_AS "ECM_A2 Packet";
BA_ "FlexKomIsMotorola" SG_ 288 EngTrq_Enbl_Rq_AS 1;
BA_ "GenSigSNA" SG_ 288 EngTrq_Enbl_Rq_AS "0h";
BA_ "GenSigCycleTime" SG_ 288 EngTrq_Enbl_Rq_ESC 20;
BA_ "FlexKomSigStartValue" SG_ 288 EngTrq_Enbl_Rq_ESC "1FFFFF1FFF00FFh";
BA_ "FlexKomSID" SG_ 288 EngTrq_Enbl_Rq_ESC 455;
BA_ "FlexKomSigStartPos" SG_ 288 EngTrq_Enbl_Rq_ESC 7;
BA_ "FlexKomSigLaenge" SG_ 288 EngTrq_Enbl_Rq_ESC 56;
BA_ "FlexKomSigName" SG_ 288 EngTrq_Enbl_Rq_ESC "ECM_A2_PKT";
BA_ "FlexKomComment" SG_ 288 EngTrq_Enbl_Rq_ESC "ECM_A2 Packet";
BA_ "FlexKomIsMotorola" SG_ 288 EngTrq_Enbl_Rq_ESC 1;
BA_ "GenSigSNA" SG_ 288 EngTrq_Enbl_Rq_ESC "0h";
BA_ "GenSigCycleTime" SG_ 288 EngTrq_Enbl_Rq_TCM 20;
BA_ "FlexKomSigStartValue" SG_ 288 EngTrq_Enbl_Rq_TCM "1FFFFF1FFF00FFh";
BA_ "FlexKomSID" SG_ 288 EngTrq_Enbl_Rq_TCM 455;
BA_ "FlexKomSigStartPos" SG_ 288 EngTrq_Enbl_Rq_TCM 7;
BA_ "FlexKomSigLaenge" SG_ 288 EngTrq_Enbl_Rq_TCM 56;
BA_ "FlexKomSigName" SG_ 288 EngTrq_Enbl_Rq_TCM "ECM_A2_PKT";
BA_ "FlexKomComment" SG_ 288 EngTrq_Enbl_Rq_TCM "ECM_A2 Packet";
BA_ "FlexKomIsMotorola" SG_ 288 EngTrq_Enbl_Rq_TCM 1;
BA_ "GenSigSNA" SG_ 288 EngTrq_Enbl_Rq_TCM "0h";
BA_ "GenSigCycleTime" SG_ 288 AccelPdlPosn 20;
BA_ "FlexKomSigStartValue" SG_ 288 AccelPdlPosn "1FFFFF1FFF00FFh";
BA_ "GenSigStartValue" SG_ 288 AccelPdlPosn 255;
BA_ "GenSigTimeout_DTCM" SG_ 288 AccelPdlPosn 210;
BA_ "GenSigTimeout_ADCM" SG_ 288 AccelPdlPosn 510;
BA_ "GenSigTimeout_ETM" SG_ 288 AccelPdlPosn 210;
BA_ "FlexKomSID" SG_ 288 AccelPdlPosn 455;
BA_ "FlexKomSigStartPos" SG_ 288 AccelPdlPosn 7;
BA_ "FlexKomSigLaenge" SG_ 288 AccelPdlPosn 56;
BA_ "FlexKomSigName" SG_ 288 AccelPdlPosn "ECM_A2_PKT";
BA_ "FlexKomComment" SG_ 288 AccelPdlPosn "ECM_A2 Packet";
BA_ "FlexKomIsMotorola" SG_ 288 AccelPdlPosn 1;
BA_ "GenSigSNA" SG_ 288 AccelPdlPosn "FFh";
BA_ "GenSigCycleTime" SG_ 288 EngTrq_DrvReqMod 20;
BA_ "FlexKomSigStartValue" SG_ 288 EngTrq_DrvReqMod "1FFFFF1FFF00FFh";
BA_ "GenSigStartValue" SG_ 288 EngTrq_DrvReqMod 8191;
BA_ "FlexKomSID" SG_ 288 EngTrq_DrvReqMod 455;
BA_ "FlexKomSigStartPos" SG_ 288 EngTrq_DrvReqMod 7;
BA_ "FlexKomSigLaenge" SG_ 288 EngTrq_DrvReqMod 56;
BA_ "FlexKomSigName" SG_ 288 EngTrq_DrvReqMod "ECM_A2_PKT";
BA_ "FlexKomComment" SG_ 288 EngTrq_DrvReqMod "ECM_A2 Packet";
BA_ "FlexKomIsMotorola" SG_ 288 EngTrq_DrvReqMod 1;
BA_ "GenSigSNA" SG_ 288 EngTrq_DrvReqMod "1FFFh";
BA_ "GenSigCycleTime" SG_ 288 ECM_LHOM 20;
BA_ "FlexKomSigStartValue" SG_ 288 ECM_LHOM "1FFFFF1FFF00FFh";
BA_ "FlexKomSID" SG_ 288 ECM_LHOM 455;
BA_ "FlexKomSigStartPos" SG_ 288 ECM_LHOM 7;
BA_ "FlexKomSigLaenge" SG_ 288 ECM_LHOM 56;
BA_ "FlexKomSigName" SG_ 288 ECM_LHOM "ECM_A2_PKT";
BA_ "FlexKomComment" SG_ 288 ECM_LHOM "ECM_A2 Packet";
BA_ "FlexKomIsMotorola" SG_ 288 ECM_LHOM 1;
BA_ "GenSigSNA" SG_ 288 ECM_LHOM "0h";
BA_ "GenSigCycleTime" SG_ 288 AccelPdlPosnSens_Flt 20;
BA_ "FlexKomSigStartValue" SG_ 288 AccelPdlPosnSens_Flt "1FFFFF1FFF00FFh";
BA_ "FlexKomSID" SG_ 288 AccelPdlPosnSens_Flt 455;
BA_ "FlexKomSigStartPos" SG_ 288 AccelPdlPosnSens_Flt 7;
BA_ "FlexKomSigLaenge" SG_ 288 AccelPdlPosnSens_Flt 56;
BA_ "FlexKomSigName" SG_ 288 AccelPdlPosnSens_Flt "ECM_A2_PKT";
BA_ "FlexKomComment" SG_ 288 AccelPdlPosnSens_Flt "ECM_A2 Packet";
BA_ "FlexKomIsMotorola" SG_ 288 AccelPdlPosnSens_Flt 1;
BA_ "GenSigSNA" SG_ 288 AccelPdlPosnSens_Flt "0h";
BA_ "GenSigCycleTime" SG_ 288 CRUISE_OVERRIDE 20;
BA_ "FlexKomSigStartValue" SG_ 288 CRUISE_OVERRIDE "1FFFFF1FFF00FFh";
BA_ "GenSigTimeout_IC" SG_ 288 CRUISE_OVERRIDE 210;
BA_ "FlexKomSID" SG_ 288 CRUISE_OVERRIDE 455;
BA_ "FlexKomSigStartPos" SG_ 288 CRUISE_OVERRIDE 7;
BA_ "FlexKomSigLaenge" SG_ 288 CRUISE_OVERRIDE 56;
BA_ "FlexKomSigName" SG_ 288 CRUISE_OVERRIDE "ECM_A2_PKT";
BA_ "FlexKomComment" SG_ 288 CRUISE_OVERRIDE "ECM_A2 Packet";
BA_ "FlexKomIsMotorola" SG_ 288 CRUISE_OVERRIDE 1;
BA_ "GenSigSNA" SG_ 288 CRUISE_OVERRIDE "0h";
BA_ "GenSigCycleTime" SG_ 288 ACC_CrusOvrd 20;
BA_ "FlexKomSigStartValue" SG_ 288 ACC_CrusOvrd "1FFFFF1FFF00FFh";
BA_ "FlexKomSID" SG_ 288 ACC_CrusOvrd 455;
BA_ "FlexKomSigStartPos" SG_ 288 ACC_CrusOvrd 7;
BA_ "FlexKomSigLaenge" SG_ 288 ACC_CrusOvrd 56;
BA_ "FlexKomSigName" SG_ 288 ACC_CrusOvrd "ECM_A2_PKT";
BA_ "FlexKomComment" SG_ 288 ACC_CrusOvrd "ECM_A2 Packet";
BA_ "FlexKomIsMotorola" SG_ 288 ACC_CrusOvrd 1;
BA_ "GenSigSNA" SG_ 288 ACC_CrusOvrd "0h";
BA_ "GenSigCycleTime" SG_ 288 ESS_RqShftPark 20;
BA_ "FlexKomSigStartValue" SG_ 288 ESS_RqShftPark "1FFFFF1FFF00FFh";
BA_ "FlexKomSID" SG_ 288 ESS_RqShftPark 455;
BA_ "FlexKomSigStartPos" SG_ 288 ESS_RqShftPark 7;
BA_ "FlexKomSigLaenge" SG_ 288 ESS_RqShftPark 56;
BA_ "FlexKomSigName" SG_ 288 ESS_RqShftPark "ECM_A2_PKT";
BA_ "FlexKomComment" SG_ 288 ESS_RqShftPark "ECM_A2 Packet";
BA_ "FlexKomIsMotorola" SG_ 288 ESS_RqShftPark 1;
BA_ "GenSigSNA" SG_ 288 ESS_RqShftPark "0h";
BA_ "GenSigCycleTime" SG_ 288 RPMOverRev 20;
BA_ "FlexKomSigStartValue" SG_ 288 RPMOverRev "1FFFFF1FFF00FFh";
BA_ "FlexKomSID" SG_ 288 RPMOverRev 455;
BA_ "FlexKomSigStartPos" SG_ 288 RPMOverRev 7;
BA_ "FlexKomSigLaenge" SG_ 288 RPMOverRev 56;
BA_ "FlexKomSigName" SG_ 288 RPMOverRev "ECM_A2_PKT";
BA_ "FlexKomComment" SG_ 288 RPMOverRev "ECM_A2 Packet";
BA_ "FlexKomIsMotorola" SG_ 288 RPMOverRev 1;
BA_ "GenSigSNA" SG_ 288 RPMOverRev "0h";
BA_ "GenSigCycleTime" SG_ 288 LV12PwrFreeRq 20;
BA_ "FlexKomSigStartValue" SG_ 288 LV12PwrFreeRq "1FFFFF1FFF00FFh";
BA_ "FlexKomSID" SG_ 288 LV12PwrFreeRq 455;
BA_ "FlexKomSigStartPos" SG_ 288 LV12PwrFreeRq 7;
BA_ "FlexKomSigLaenge" SG_ 288 LV12PwrFreeRq 56;
BA_ "FlexKomSigName" SG_ 288 LV12PwrFreeRq "ECM_A2_PKT";
BA_ "FlexKomComment" SG_ 288 LV12PwrFreeRq "ECM_A2 Packet";
BA_ "FlexKomIsMotorola" SG_ 288 LV12PwrFreeRq 1;
BA_ "GenSigSNA" SG_ 288 LV12PwrFreeRq "0h";
BA_ "GenSigCycleTime" SG_ 288 MC_ECM_A2 20;
BA_ "FlexKomSigStartValue" SG_ 288 MC_ECM_A2 "1FFFFF1FFF00FFh";
BA_ "FlexKomSID" SG_ 288 MC_ECM_A2 455;
BA_ "FlexKomSigStartPos" SG_ 288 MC_ECM_A2 7;
BA_ "FlexKomSigLaenge" SG_ 288 MC_ECM_A2 56;
BA_ "FlexKomSigName" SG_ 288 MC_ECM_A2 "ECM_A2_PKT";
BA_ "FlexKomComment" SG_ 288 MC_ECM_A2 "ECM_A2 Packet";
BA_ "FlexKomIsMotorola" SG_ 288 MC_ECM_A2 1;
BA_ "GenSigSNA" SG_ 288 MC_ECM_A2 "0h";
BA_ "GenSigCycleTime" SG_ 288 CRC_ECM_A2 20;
BA_ "FlexKomSigStartValue" SG_ 288 CRC_ECM_A2 "1FFFFF1FFF00FFh";
BA_ "GenSigStartValue" SG_ 288 CRC_ECM_A2 255;
BA_ "FlexKomSID" SG_ 288 CRC_ECM_A2 455;
BA_ "FlexKomSigStartPos" SG_ 288 CRC_ECM_A2 7;
BA_ "FlexKomSigLaenge" SG_ 288 CRC_ECM_A2 56;
BA_ "FlexKomSigName" SG_ 288 CRC_ECM_A2 "ECM_A2_PKT";
BA_ "FlexKomComment" SG_ 288 CRC_ECM_A2 "ECM_A2 Packet";
BA_ "FlexKomIsMotorola" SG_ 288 CRC_ECM_A2 1;
BA_ "GenSigSNA" SG_ 288 CRC_ECM_A2 "FFh";
BA_ "GenSigCycleTime" SG_ 290 EngTrq_Ack_ECM 20;
BA_ "FlexKomSigStartValue" SG_ 290 EngTrq_Ack_ECM "00h";
BA_ "FlexKomSID" SG_ 290 EngTrq_Ack_ECM 1235;
BA_ "FlexKomSigLaenge" SG_ 290 EngTrq_Ack_ECM 1;
BA_ "FlexKomSigName" SG_ 290 EngTrq_Ack_ECM "EngTrq_Ack_ECM";
BA_ "FlexKomComment" SG_ 290 EngTrq_Ack_ECM "Acknowledge TRANS torque request";
BA_ "FlexKomIsMotorola" SG_ 290 EngTrq_Ack_ECM 1;
BA_ "GenSigSNA" SG_ 290 EngTrq_Ack_ECM "0h";
BA_ "GenSigCycleTime" SG_ 290 KUEB_O_A 20;
BA_ "FlexKomSigStartValue" SG_ 290 KUEB_O_A "00h";
BA_ "FlexKomSID" SG_ 290 KUEB_O_A 1236;
BA_ "FlexKomSigStartPos" SG_ 290 KUEB_O_A 1;
BA_ "FlexKomSigLaenge" SG_ 290 KUEB_O_A 1;
BA_ "FlexKomSigName" SG_ 290 KUEB_O_A "KUEB_O_A";
BA_ "FlexKomComment" SG_ 290 KUEB_O_A "Request to disengage torque converter lock-up clut";
BA_ "FlexKomIsMotorola" SG_ 290 KUEB_O_A 1;
BA_ "GenSigSNA" SG_ 290 KUEB_O_A "0h";
BA_ "GenSigCycleTime" SG_ 290 KUEB_S_A 20;
BA_ "FlexKomSigStartValue" SG_ 290 KUEB_S_A "00h";
BA_ "FlexKomSID" SG_ 290 KUEB_S_A 1237;
BA_ "FlexKomSigStartPos" SG_ 290 KUEB_S_A 2;
BA_ "FlexKomSigLaenge" SG_ 290 KUEB_S_A 1;
BA_ "FlexKomSigName" SG_ 290 KUEB_S_A "KUEB_S_A";
BA_ "FlexKomComment" SG_ 290 KUEB_S_A "Increased torque converter slip is desired";
BA_ "FlexKomIsMotorola" SG_ 290 KUEB_S_A 1;
BA_ "GenSigSNA" SG_ 290 KUEB_S_A "0h";
BA_ "GenSigCycleTime" SG_ 290 KickDnSw_Psd 20;
BA_ "FlexKomSigStartValue" SG_ 290 KickDnSw_Psd "00h";
BA_ "FlexKomSID" SG_ 290 KickDnSw_Psd 1238;
BA_ "FlexKomSigStartPos" SG_ 290 KickDnSw_Psd 3;
BA_ "FlexKomSigLaenge" SG_ 290 KickDnSw_Psd 1;
BA_ "FlexKomSigName" SG_ 290 KickDnSw_Psd "KickDnSw_Psd";
BA_ "FlexKomComment" SG_ 290 KickDnSw_Psd "kick-down (change-over scenario open!)";
BA_ "FlexKomIsMotorola" SG_ 290 KickDnSw_Psd 1;
BA_ "GenSigSNA" SG_ 290 KickDnSw_Psd "0h";
BA_ "GenSigCycleTime" SG_ 290 N_MAX_BG 20;
BA_ "FlexKomSigStartValue" SG_ 290 N_MAX_BG "00h";
BA_ "FlexKomSID" SG_ 290 N_MAX_BG 1239;
BA_ "FlexKomSigStartPos" SG_ 290 N_MAX_BG 4;
BA_ "FlexKomSigLaenge" SG_ 290 N_MAX_BG 1;
BA_ "FlexKomSigName" SG_ 290 N_MAX_BG "N_MAX_BG";
BA_ "FlexKomComment" SG_ 290 N_MAX_BG "Rev Max achieved and rev limiter active";
BA_ "FlexKomIsMotorola" SG_ 290 N_MAX_BG 1;
BA_ "GenSigSNA" SG_ 290 N_MAX_BG "0h";
BA_ "GenSigCycleTime" SG_ 290 TxAC_EMCC_rq 20;
BA_ "FlexKomSigStartValue" SG_ 290 TxAC_EMCC_rq "00h";
BA_ "FlexKomSID" SG_ 290 TxAC_EMCC_rq 1240;
BA_ "FlexKomSigStartPos" SG_ 290 TxAC_EMCC_rq 5;
BA_ "FlexKomSigLaenge" SG_ 290 TxAC_EMCC_rq 1;
BA_ "FlexKomSigName" SG_ 290 TxAC_EMCC_rq "TxAC_EMCC_rq";
BA_ "FlexKomComment" SG_ 290 TxAC_EMCC_rq "Transmission  AC converter clutch slip request; [1";
BA_ "FlexKomIsMotorola" SG_ 290 TxAC_EMCC_rq 1;
BA_ "GenSigSNA" SG_ 290 TxAC_EMCC_rq "0h";
BA_ "GenSigCycleTime" SG_ 290 S_EGT 20;
BA_ "FlexKomSigStartValue" SG_ 290 S_EGT "00h";
BA_ "FlexKomSID" SG_ 290 S_EGT 1249;
BA_ "FlexKomSigStartPos" SG_ 290 S_EGT 7;
BA_ "FlexKomSigLaenge" SG_ 290 S_EGT 2;
BA_ "FlexKomSigName" SG_ 290 S_EGT "S_EGT";
BA_ "FlexKomComment" SG_ 290 S_EGT "DPF assistance request";
BA_ "FlexKomIsMotorola" SG_ 290 S_EGT 1;
BA_ "GenSigSNA" SG_ 290 S_EGT "3h";
BA_ "GenSigCycleTime" SG_ 290 EngTrqMaxCorrFctr 20;
BA_ "FlexKomSigStartValue" SG_ 290 EngTrqMaxCorrFctr "FFh";
BA_ "GenSigStartValue" SG_ 290 EngTrqMaxCorrFctr 255;
BA_ "FlexKomSID" SG_ 290 EngTrqMaxCorrFctr 1242;
BA_ "FlexKomSigStartPos" SG_ 290 EngTrqMaxCorrFctr 15;
BA_ "FlexKomSigLaenge" SG_ 290 EngTrqMaxCorrFctr 8;
BA_ "FlexKomSigName" SG_ 290 EngTrqMaxCorrFctr "EngTrqMaxCorrFctr";
BA_ "FlexKomComment" SG_ 290 EngTrqMaxCorrFctr "Factor of reduction from max. torque";
BA_ "FlexKomIsMotorola" SG_ 290 EngTrqMaxCorrFctr 1;
BA_ "GenSigSNA" SG_ 290 EngTrqMaxCorrFctr "FFh";
BA_ "GenSigCycleTime" SG_ 290 GrMin_Rq_ECM 20;
BA_ "FlexKomSigStartValue" SG_ 290 GrMin_Rq_ECM "00h";
BA_ "FlexKomSID" SG_ 290 GrMin_Rq_ECM 1243;
BA_ "FlexKomSigStartPos" SG_ 290 GrMin_Rq_ECM 21;
BA_ "FlexKomSigLaenge" SG_ 290 GrMin_Rq_ECM 6;
BA_ "FlexKomSigName" SG_ 290 GrMin_Rq_ECM "ECM_Gear";
BA_ "FlexKomComment" SG_ 290 GrMin_Rq_ECM "Target gear upper and lower limit";
BA_ "FlexKomIsMotorola" SG_ 290 GrMin_Rq_ECM 1;
BA_ "GenSigSNA" SG_ 290 GrMin_Rq_ECM "0h";
BA_ "GenSigCycleTime" SG_ 290 GrMax_Rq_ECM 20;
BA_ "FlexKomSigStartValue" SG_ 290 GrMax_Rq_ECM "00h";
BA_ "FlexKomSID" SG_ 290 GrMax_Rq_ECM 1243;
BA_ "FlexKomSigStartPos" SG_ 290 GrMax_Rq_ECM 21;
BA_ "FlexKomSigLaenge" SG_ 290 GrMax_Rq_ECM 6;
BA_ "FlexKomSigName" SG_ 290 GrMax_Rq_ECM "ECM_Gear";
BA_ "FlexKomComment" SG_ 290 GrMax_Rq_ECM "Target gear upper and lower limit";
BA_ "FlexKomIsMotorola" SG_ 290 GrMax_Rq_ECM 1;
BA_ "GenSigSNA" SG_ 290 GrMax_Rq_ECM "0h";
BA_ "GenSigCycleTime" SG_ 290 Gr1_Rq_ECM 20;
BA_ "FlexKomSigStartValue" SG_ 290 Gr1_Rq_ECM "00h";
BA_ "FlexKomSID" SG_ 290 Gr1_Rq_ECM 1244;
BA_ "FlexKomSigStartPos" SG_ 290 Gr1_Rq_ECM 22;
BA_ "FlexKomSigLaenge" SG_ 290 Gr1_Rq_ECM 1;
BA_ "FlexKomSigName" SG_ 290 Gr1_Rq_ECM "Gr1_Rq_ECM";
BA_ "FlexKomComment" SG_ 290 Gr1_Rq_ECM "ECM request: 'Start off in 1st gear'";
BA_ "FlexKomIsMotorola" SG_ 290 Gr1_Rq_ECM 1;
BA_ "GenSigSNA" SG_ 290 Gr1_Rq_ECM "0h";
BA_ "GenSigCycleTime" SG_ 290 TxGearRq 20;
BA_ "FlexKomSigStartValue" SG_ 290 TxGearRq "00h";
BA_ "FlexKomSID" SG_ 290 TxGearRq 1245;
BA_ "FlexKomSigStartPos" SG_ 290 TxGearRq 23;
BA_ "FlexKomSigLaenge" SG_ 290 TxGearRq 1;
BA_ "FlexKomSigName" SG_ 290 TxGearRq "TxGearRq";
BA_ "FlexKomComment" SG_ 290 TxGearRq "Transmission gear request";
BA_ "FlexKomIsMotorola" SG_ 290 TxGearRq 1;
BA_ "GenSigSNA" SG_ 290 TxGearRq "0h";
BA_ "GenSigCycleTime" SG_ 290 TxGearDes 20;
BA_ "FlexKomSigStartValue" SG_ 290 TxGearDes "0Fh";
BA_ "GenSigStartValue" SG_ 290 TxGearDes 15;
BA_ "FlexKomSID" SG_ 290 TxGearDes 1246;
BA_ "FlexKomSigStartPos" SG_ 290 TxGearDes 27;
BA_ "FlexKomSigLaenge" SG_ 290 TxGearDes 4;
BA_ "FlexKomSigName" SG_ 290 TxGearDes "TxGearDes";
BA_ "FlexKomComment" SG_ 290 TxGearDes "Transmission gear desired";
BA_ "FlexKomIsMotorola" SG_ 290 TxGearDes 1;
BA_ "GenSigSNA" SG_ 290 TxGearDes "Fh";
BA_ "GenSigCycleTime" SG_ 290 ShftChrDsp_Rq 20;
BA_ "FlexKomSigStartValue" SG_ 290 ShftChrDsp_Rq "00h";
BA_ "FlexKomSID" SG_ 290 ShftChrDsp_Rq 1247;
BA_ "FlexKomSigStartPos" SG_ 290 ShftChrDsp_Rq 31;
BA_ "FlexKomSigLaenge" SG_ 290 ShftChrDsp_Rq 4;
BA_ "FlexKomSigName" SG_ 290 ShftChrDsp_Rq "ShftChrDsp_Rq";
BA_ "FlexKomComment" SG_ 290 ShftChrDsp_Rq "Shift characteristic displacement request";
BA_ "FlexKomIsMotorola" SG_ 290 ShftChrDsp_Rq 1;
BA_ "GenSigSNA" SG_ 290 ShftChrDsp_Rq "Fh";
BA_ "GenSigCycleTime" SG_ 290 NMOTS 20;
BA_ "FlexKomSigStartValue" SG_ 290 NMOTS "FFFFh";
BA_ "GenSigStartValue" SG_ 290 NMOTS 65535;
BA_ "FlexKomSID" SG_ 290 NMOTS 1248;
BA_ "FlexKomSigStartPos" SG_ 290 NMOTS 39;
BA_ "FlexKomSigLaenge" SG_ 290 NMOTS 16;
BA_ "FlexKomSigName" SG_ 290 NMOTS "NMOTS";
BA_ "FlexKomComment" SG_ 290 NMOTS "Target idle speed";
BA_ "FlexKomIsMotorola" SG_ 290 NMOTS 1;
BA_ "GenSigSNA" SG_ 290 NMOTS "FFFFh";
BA_ "GenSigCycleTime" SG_ 292 WhlPlsCnt_FL 20;
BA_ "FlexKomSigStartValue" SG_ 292 WhlPlsCnt_FL "FFFFFFFFh";
BA_ "GenSigStartValue" SG_ 292 WhlPlsCnt_FL 255;
BA_ "GenSigTimeout_CBC" SG_ 292 WhlPlsCnt_FL 210;
BA_ "GenSigTimeout_IC" SG_ 292 WhlPlsCnt_FL 210;
BA_ "FlexKomSID" SG_ 292 WhlPlsCnt_FL 65;
BA_ "FlexKomSigStartPos" SG_ 292 WhlPlsCnt_FL 7;
BA_ "FlexKomSigLaenge" SG_ 292 WhlPlsCnt_FL 32;
BA_ "FlexKomSigName" SG_ 292 WhlPlsCnt_FL "ESP_WHL_PULS";
BA_ "FlexKomComment" SG_ 292 WhlPlsCnt_FL "ESP Wheel pulse counts";
BA_ "FlexKomIsMotorola" SG_ 292 WhlPlsCnt_FL 1;
BA_ "GenSigSNA" SG_ 292 WhlPlsCnt_FL "FFh";
BA_ "GenSigCycleTime" SG_ 292 WhlPlsCnt_FR 20;
BA_ "FlexKomSigStartValue" SG_ 292 WhlPlsCnt_FR "FFFFFFFFh";
BA_ "GenSigStartValue" SG_ 292 WhlPlsCnt_FR 255;
BA_ "GenSigTimeout_CBC" SG_ 292 WhlPlsCnt_FR 210;
BA_ "GenSigTimeout_IC" SG_ 292 WhlPlsCnt_FR 210;
BA_ "FlexKomSID" SG_ 292 WhlPlsCnt_FR 65;
BA_ "FlexKomSigStartPos" SG_ 292 WhlPlsCnt_FR 7;
BA_ "FlexKomSigLaenge" SG_ 292 WhlPlsCnt_FR 32;
BA_ "FlexKomSigName" SG_ 292 WhlPlsCnt_FR "ESP_WHL_PULS";
BA_ "FlexKomComment" SG_ 292 WhlPlsCnt_FR "ESP Wheel pulse counts";
BA_ "FlexKomIsMotorola" SG_ 292 WhlPlsCnt_FR 1;
BA_ "GenSigSNA" SG_ 292 WhlPlsCnt_FR "FFh";
BA_ "GenSigCycleTime" SG_ 292 WhlPlsCnt_RL 20;
BA_ "FlexKomSigStartValue" SG_ 292 WhlPlsCnt_RL "FFFFFFFFh";
BA_ "GenSigStartValue" SG_ 292 WhlPlsCnt_RL 255;
BA_ "GenSigTimeout_CBC" SG_ 292 WhlPlsCnt_RL 210;
BA_ "GenSigTimeout_IC" SG_ 292 WhlPlsCnt_RL 210;
BA_ "FlexKomSID" SG_ 292 WhlPlsCnt_RL 65;
BA_ "FlexKomSigStartPos" SG_ 292 WhlPlsCnt_RL 7;
BA_ "FlexKomSigLaenge" SG_ 292 WhlPlsCnt_RL 32;
BA_ "FlexKomSigName" SG_ 292 WhlPlsCnt_RL "ESP_WHL_PULS";
BA_ "FlexKomComment" SG_ 292 WhlPlsCnt_RL "ESP Wheel pulse counts";
BA_ "FlexKomIsMotorola" SG_ 292 WhlPlsCnt_RL 1;
BA_ "GenSigSNA" SG_ 292 WhlPlsCnt_RL "FFh";
BA_ "GenSigCycleTime" SG_ 292 WhlPlsCnt_RR 20;
BA_ "FlexKomSigStartValue" SG_ 292 WhlPlsCnt_RR "FFFFFFFFh";
BA_ "GenSigStartValue" SG_ 292 WhlPlsCnt_RR 255;
BA_ "GenSigTimeout_CBC" SG_ 292 WhlPlsCnt_RR 210;
BA_ "GenSigTimeout_IC" SG_ 292 WhlPlsCnt_RR 210;
BA_ "FlexKomSID" SG_ 292 WhlPlsCnt_RR 65;
BA_ "FlexKomSigStartPos" SG_ 292 WhlPlsCnt_RR 7;
BA_ "FlexKomSigLaenge" SG_ 292 WhlPlsCnt_RR 32;
BA_ "FlexKomSigName" SG_ 292 WhlPlsCnt_RR "ESP_WHL_PULS";
BA_ "FlexKomComment" SG_ 292 WhlPlsCnt_RR "ESP Wheel pulse counts";
BA_ "FlexKomIsMotorola" SG_ 292 WhlPlsCnt_RR 1;
BA_ "GenSigSNA" SG_ 292 WhlPlsCnt_RR "FFh";
BA_ "GenSigCycleTime" SG_ 292 FT_DIFF_ESP_RQ 20;
BA_ "FlexKomSigStartValue" SG_ 292 FT_DIFF_ESP_RQ "00FFFFFFh";
BA_ "FlexKomSID" SG_ 292 FT_DIFF_ESP_RQ 394;
BA_ "FlexKomSigStartPos" SG_ 292 FT_DIFF_ESP_RQ 39;
BA_ "FlexKomSigLaenge" SG_ 292 FT_DIFF_ESP_RQ 32;
BA_ "FlexKomSigName" SG_ 292 FT_DIFF_ESP_RQ "ESP_DIFF_RQ";
BA_ "FlexKomComment" SG_ 292 FT_DIFF_ESP_RQ "ESP DIFF Control Requests";
BA_ "FlexKomIsMotorola" SG_ 292 FT_DIFF_ESP_RQ 1;
BA_ "GenSigSNA" SG_ 292 FT_DIFF_ESP_RQ "3h";
BA_ "GenSigCycleTime" SG_ 292 CENT_DIFF_ESP_RQ 20;
BA_ "FlexKomSigStartValue" SG_ 292 CENT_DIFF_ESP_RQ "00FFFFFFh";
BA_ "FlexKomSID" SG_ 292 CENT_DIFF_ESP_RQ 394;
BA_ "FlexKomSigStartPos" SG_ 292 CENT_DIFF_ESP_RQ 39;
BA_ "FlexKomSigLaenge" SG_ 292 CENT_DIFF_ESP_RQ 32;
BA_ "FlexKomSigName" SG_ 292 CENT_DIFF_ESP_RQ "ESP_DIFF_RQ";
BA_ "FlexKomComment" SG_ 292 CENT_DIFF_ESP_RQ "ESP DIFF Control Requests";
BA_ "FlexKomIsMotorola" SG_ 292 CENT_DIFF_ESP_RQ 1;
BA_ "GenSigSNA" SG_ 292 CENT_DIFF_ESP_RQ "3h";
BA_ "GenSigCycleTime" SG_ 292 R_DIFF_ESP_RQ 20;
BA_ "FlexKomSigStartValue" SG_ 292 R_DIFF_ESP_RQ "00FFFFFFh";
BA_ "FlexKomSID" SG_ 292 R_DIFF_ESP_RQ 394;
BA_ "FlexKomSigStartPos" SG_ 292 R_DIFF_ESP_RQ 39;
BA_ "FlexKomSigLaenge" SG_ 292 R_DIFF_ESP_RQ 32;
BA_ "FlexKomSigName" SG_ 292 R_DIFF_ESP_RQ "ESP_DIFF_RQ";
BA_ "FlexKomComment" SG_ 292 R_DIFF_ESP_RQ "ESP DIFF Control Requests";
BA_ "FlexKomIsMotorola" SG_ 292 R_DIFF_ESP_RQ 1;
BA_ "GenSigSNA" SG_ 292 R_DIFF_ESP_RQ "3h";
BA_ "GenSigCycleTime" SG_ 292 FT_DIFF_TRQ_RQ 20;
BA_ "FlexKomSigStartValue" SG_ 292 FT_DIFF_TRQ_RQ "00FFFFFFh";
BA_ "GenSigStartValue" SG_ 292 FT_DIFF_TRQ_RQ 255;
BA_ "FlexKomSID" SG_ 292 FT_DIFF_TRQ_RQ 394;
BA_ "FlexKomSigStartPos" SG_ 292 FT_DIFF_TRQ_RQ 39;
BA_ "FlexKomSigLaenge" SG_ 292 FT_DIFF_TRQ_RQ 32;
BA_ "FlexKomSigName" SG_ 292 FT_DIFF_TRQ_RQ "ESP_DIFF_RQ";
BA_ "FlexKomComment" SG_ 292 FT_DIFF_TRQ_RQ "ESP DIFF Control Requests";
BA_ "FlexKomIsMotorola" SG_ 292 FT_DIFF_TRQ_RQ 1;
BA_ "GenSigSNA" SG_ 292 FT_DIFF_TRQ_RQ "FFh";
BA_ "GenSigCycleTime" SG_ 292 CENT_DIFF_TRQ_RQ 20;
BA_ "FlexKomSigStartValue" SG_ 292 CENT_DIFF_TRQ_RQ "00FFFFFFh";
BA_ "GenSigStartValue" SG_ 292 CENT_DIFF_TRQ_RQ 255;
BA_ "FlexKomSID" SG_ 292 CENT_DIFF_TRQ_RQ 394;
BA_ "FlexKomSigStartPos" SG_ 292 CENT_DIFF_TRQ_RQ 39;
BA_ "FlexKomSigLaenge" SG_ 292 CENT_DIFF_TRQ_RQ 32;
BA_ "FlexKomSigName" SG_ 292 CENT_DIFF_TRQ_RQ "ESP_DIFF_RQ";
BA_ "FlexKomComment" SG_ 292 CENT_DIFF_TRQ_RQ "ESP DIFF Control Requests";
BA_ "FlexKomIsMotorola" SG_ 292 CENT_DIFF_TRQ_RQ 1;
BA_ "GenSigSNA" SG_ 292 CENT_DIFF_TRQ_RQ "FFh";
BA_ "GenSigCycleTime" SG_ 292 R_DIFF_TRQ_RQ 20;
BA_ "FlexKomSigStartValue" SG_ 292 R_DIFF_TRQ_RQ "00FFFFFFh";
BA_ "GenSigStartValue" SG_ 292 R_DIFF_TRQ_RQ 255;
BA_ "FlexKomSID" SG_ 292 R_DIFF_TRQ_RQ 394;
BA_ "FlexKomSigStartPos" SG_ 292 R_DIFF_TRQ_RQ 39;
BA_ "FlexKomSigLaenge" SG_ 292 R_DIFF_TRQ_RQ 32;
BA_ "FlexKomSigName" SG_ 292 R_DIFF_TRQ_RQ "ESP_DIFF_RQ";
BA_ "FlexKomComment" SG_ 292 R_DIFF_TRQ_RQ "ESP DIFF Control Requests";
BA_ "FlexKomIsMotorola" SG_ 292 R_DIFF_TRQ_RQ 1;
BA_ "GenSigSNA" SG_ 292 R_DIFF_TRQ_RQ "FFh";
BA_ "GenSigCycleTime" SG_ 294 LatAcceleration 10;
BA_ "FlexKomSigStartValue" SG_ 294 LatAcceleration "000000000FFF00FFh";
BA_ "FlexKomSID" SG_ 294 LatAcceleration 1587;
BA_ "FlexKomSigStartPos" SG_ 294 LatAcceleration 7;
BA_ "FlexKomSigLaenge" SG_ 294 LatAcceleration 64;
BA_ "FlexKomSigName" SG_ 294 LatAcceleration "ORC_YRS_PKT";
BA_ "FlexKomComment" SG_ 294 LatAcceleration "Accelerometer data packet";
BA_ "FlexKomIsMotorola" SG_ 294 LatAcceleration 1;
BA_ "GenSigSNA" SG_ 294 LatAcceleration "FFFh";
BA_ "GenSigCycleTime" SG_ 294 AXSStat 10;
BA_ "FlexKomSigStartValue" SG_ 294 AXSStat "000000000FFF00FFh";
BA_ "FlexKomSID" SG_ 294 AXSStat 1587;
BA_ "FlexKomSigStartPos" SG_ 294 AXSStat 7;
BA_ "FlexKomSigLaenge" SG_ 294 AXSStat 64;
BA_ "FlexKomSigName" SG_ 294 AXSStat "ORC_YRS_PKT";
BA_ "FlexKomComment" SG_ 294 AXSStat "Accelerometer data packet";
BA_ "FlexKomIsMotorola" SG_ 294 AXSStat 1;
BA_ "GenSigSNA" SG_ 294 AXSStat "0h";
BA_ "GenSigCycleTime" SG_ 294 AYSStat 10;
BA_ "FlexKomSigStartValue" SG_ 294 AYSStat "000000000FFF00FFh";
BA_ "FlexKomSID" SG_ 294 AYSStat 1587;
BA_ "FlexKomSigStartPos" SG_ 294 AYSStat 7;
BA_ "FlexKomSigLaenge" SG_ 294 AYSStat 64;
BA_ "FlexKomSigName" SG_ 294 AYSStat "ORC_YRS_PKT";
BA_ "FlexKomComment" SG_ 294 AYSStat "Accelerometer data packet";
BA_ "FlexKomIsMotorola" SG_ 294 AYSStat 1;
BA_ "GenSigSNA" SG_ 294 AYSStat "0h";
BA_ "GenSigCycleTime" SG_ 294 LongAcceleration 10;
BA_ "FlexKomSigStartValue" SG_ 294 LongAcceleration "000000000FFF00FFh";
BA_ "FlexKomSID" SG_ 294 LongAcceleration 1587;
BA_ "FlexKomSigStartPos" SG_ 294 LongAcceleration 7;
BA_ "FlexKomSigLaenge" SG_ 294 LongAcceleration 64;
BA_ "FlexKomSigName" SG_ 294 LongAcceleration "ORC_YRS_PKT";
BA_ "FlexKomComment" SG_ 294 LongAcceleration "Accelerometer data packet";
BA_ "FlexKomIsMotorola" SG_ 294 LongAcceleration 1;
BA_ "GenSigSNA" SG_ 294 LongAcceleration "FFFh";
BA_ "GenSigCycleTime" SG_ 294 YRSStat 10;
BA_ "FlexKomSigStartValue" SG_ 294 YRSStat "000000000FFF00FFh";
BA_ "FlexKomSID" SG_ 294 YRSStat 1587;
BA_ "FlexKomSigStartPos" SG_ 294 YRSStat 7;
BA_ "FlexKomSigLaenge" SG_ 294 YRSStat 64;
BA_ "FlexKomSigName" SG_ 294 YRSStat "ORC_YRS_PKT";
BA_ "FlexKomComment" SG_ 294 YRSStat "Accelerometer data packet";
BA_ "FlexKomIsMotorola" SG_ 294 YRSStat 1;
BA_ "GenSigSNA" SG_ 294 YRSStat "0h";
BA_ "GenSigCycleTime" SG_ 294 InternalError 10;
BA_ "FlexKomSigStartValue" SG_ 294 InternalError "000000000FFF00FFh";
BA_ "FlexKomSID" SG_ 294 InternalError 1587;
BA_ "FlexKomSigStartPos" SG_ 294 InternalError 7;
BA_ "FlexKomSigLaenge" SG_ 294 InternalError 64;
BA_ "FlexKomSigName" SG_ 294 InternalError "ORC_YRS_PKT";
BA_ "FlexKomComment" SG_ 294 InternalError "Accelerometer data packet";
BA_ "FlexKomIsMotorola" SG_ 294 InternalError 1;
BA_ "GenSigSNA" SG_ 294 InternalError "0h";
BA_ "GenSigCycleTime" SG_ 294 VoltageError 10;
BA_ "FlexKomSigStartValue" SG_ 294 VoltageError "000000000FFF00FFh";
BA_ "FlexKomSID" SG_ 294 VoltageError 1587;
BA_ "FlexKomSigStartPos" SG_ 294 VoltageError 7;
BA_ "FlexKomSigLaenge" SG_ 294 VoltageError 64;
BA_ "FlexKomSigName" SG_ 294 VoltageError "ORC_YRS_PKT";
BA_ "FlexKomComment" SG_ 294 VoltageError "Accelerometer data packet";
BA_ "FlexKomIsMotorola" SG_ 294 VoltageError 1;
BA_ "GenSigSNA" SG_ 294 VoltageError "0h";
BA_ "GenSigCycleTime" SG_ 294 YawRate 10;
BA_ "FlexKomSigStartValue" SG_ 294 YawRate "000000000FFF00FFh";
BA_ "GenSigStartValue" SG_ 294 YawRate 4095;
BA_ "FlexKomSID" SG_ 294 YawRate 1587;
BA_ "FlexKomSigStartPos" SG_ 294 YawRate 7;
BA_ "FlexKomSigLaenge" SG_ 294 YawRate 64;
BA_ "FlexKomSigName" SG_ 294 YawRate "ORC_YRS_PKT";
BA_ "FlexKomComment" SG_ 294 YawRate "Accelerometer data packet";
BA_ "FlexKomIsMotorola" SG_ 294 YawRate 1;
BA_ "GenSigSNA" SG_ 294 YawRate "FFFh";
BA_ "GenSigCycleTime" SG_ 294 MC_ORC_YRS_DATA 10;
BA_ "FlexKomSigStartValue" SG_ 294 MC_ORC_YRS_DATA "000000000FFF00FFh";
BA_ "FlexKomSID" SG_ 294 MC_ORC_YRS_DATA 1587;
BA_ "FlexKomSigStartPos" SG_ 294 MC_ORC_YRS_DATA 7;
BA_ "FlexKomSigLaenge" SG_ 294 MC_ORC_YRS_DATA 64;
BA_ "FlexKomSigName" SG_ 294 MC_ORC_YRS_DATA "ORC_YRS_PKT";
BA_ "FlexKomComment" SG_ 294 MC_ORC_YRS_DATA "Accelerometer data packet";
BA_ "FlexKomIsMotorola" SG_ 294 MC_ORC_YRS_DATA 1;
BA_ "GenSigSNA" SG_ 294 MC_ORC_YRS_DATA "0h";
BA_ "GenSigCycleTime" SG_ 294 CRC_ORC_YRS_DATA 10;
BA_ "FlexKomSigStartValue" SG_ 294 CRC_ORC_YRS_DATA "000000000FFF00FFh";
BA_ "GenSigStartValue" SG_ 294 CRC_ORC_YRS_DATA 255;
BA_ "FlexKomSID" SG_ 294 CRC_ORC_YRS_DATA 1587;
BA_ "FlexKomSigStartPos" SG_ 294 CRC_ORC_YRS_DATA 7;
BA_ "FlexKomSigLaenge" SG_ 294 CRC_ORC_YRS_DATA 64;
BA_ "FlexKomSigName" SG_ 294 CRC_ORC_YRS_DATA "ORC_YRS_PKT";
BA_ "FlexKomComment" SG_ 294 CRC_ORC_YRS_DATA "Accelerometer data packet";
BA_ "FlexKomIsMotorola" SG_ 294 CRC_ORC_YRS_DATA 1;
BA_ "GenSigSNA" SG_ 294 CRC_ORC_YRS_DATA "FFh";
BA_ "GenSigCycleTime" SG_ 300 EPS_AsstStat 100;
BA_ "FlexKomSigStartValue" SG_ 300 EPS_AsstStat "0200FF0000000000h";
BA_ "GenSigStartValue" SG_ 300 EPS_AsstStat 1;
BA_ "GenSigTimeout_IC" SG_ 300 EPS_AsstStat 1050;
BA_ "GenSigTimeout_ORC" SG_ 300 EPS_AsstStat 350;
BA_ "FlexKomSID" SG_ 300 EPS_AsstStat 846;
BA_ "FlexKomSigStartPos" SG_ 300 EPS_AsstStat 7;
BA_ "FlexKomSigLaenge" SG_ 300 EPS_AsstStat 64;
BA_ "FlexKomSigName" SG_ 300 EPS_AsstStat "EPS_A1_PKT";
BA_ "FlexKomComment" SG_ 300 EPS_AsstStat "EPS_A1_PKT";
BA_ "FlexKomIsMotorola" SG_ 300 EPS_AsstStat 1;
BA_ "GenSigSNA" SG_ 300 EPS_AsstStat "7h";
BA_ "GenSigCycleTime" SG_ 300 EPS_Warn_Disp_Rq 100;
BA_ "FlexKomSigStartValue" SG_ 300 EPS_Warn_Disp_Rq "0200FF0000000000h";
BA_ "GenSigTimeout_CBC" SG_ 300 EPS_Warn_Disp_Rq 1050;
BA_ "GenSigTimeout_IC" SG_ 300 EPS_Warn_Disp_Rq 1050;
BA_ "GenSigTimeout_ORC" SG_ 300 EPS_Warn_Disp_Rq 350;
BA_ "FlexKomSID" SG_ 300 EPS_Warn_Disp_Rq 846;
BA_ "FlexKomSigStartPos" SG_ 300 EPS_Warn_Disp_Rq 7;
BA_ "FlexKomSigLaenge" SG_ 300 EPS_Warn_Disp_Rq 64;
BA_ "FlexKomSigName" SG_ 300 EPS_Warn_Disp_Rq "EPS_A1_PKT";
BA_ "FlexKomComment" SG_ 300 EPS_Warn_Disp_Rq "EPS_A1_PKT";
BA_ "FlexKomIsMotorola" SG_ 300 EPS_Warn_Disp_Rq 1;
BA_ "GenSigSNA" SG_ 300 EPS_Warn_Disp_Rq "7h";
BA_ "GenSigCycleTime" SG_ 300 PS_SysType 100;
BA_ "FlexKomSigStartValue" SG_ 300 PS_SysType "0200FF0000000000h";
BA_ "GenSigTimeout_IC" SG_ 300 PS_SysType 1050;
BA_ "FlexKomSID" SG_ 300 PS_SysType 846;
BA_ "FlexKomSigStartPos" SG_ 300 PS_SysType 7;
BA_ "FlexKomSigLaenge" SG_ 300 PS_SysType 64;
BA_ "FlexKomSigName" SG_ 300 PS_SysType "EPS_A1_PKT";
BA_ "FlexKomComment" SG_ 300 PS_SysType "EPS_A1_PKT";
BA_ "FlexKomIsMotorola" SG_ 300 PS_SysType 1;
BA_ "GenSigSNA" SG_ 300 PS_SysType "0h";
BA_ "GenSigCycleTime" SG_ 300 EPS_MODE_CFG_STAT 100;
BA_ "FlexKomSigStartValue" SG_ 300 EPS_MODE_CFG_STAT "0200FF0000000000h";
BA_ "GenSigTimeout_CBC" SG_ 300 EPS_MODE_CFG_STAT 1050;
BA_ "FlexKomSID" SG_ 300 EPS_MODE_CFG_STAT 846;
BA_ "FlexKomSigStartPos" SG_ 300 EPS_MODE_CFG_STAT 7;
BA_ "FlexKomSigLaenge" SG_ 300 EPS_MODE_CFG_STAT 64;
BA_ "FlexKomSigName" SG_ 300 EPS_MODE_CFG_STAT "EPS_A1_PKT";
BA_ "FlexKomComment" SG_ 300 EPS_MODE_CFG_STAT "EPS_A1_PKT";
BA_ "FlexKomIsMotorola" SG_ 300 EPS_MODE_CFG_STAT 1;
BA_ "GenSigSNA" SG_ 300 EPS_MODE_CFG_STAT "7h";
BA_ "GenSigCycleTime" SG_ 300 EPS_MODE_STAT 100;
BA_ "FlexKomSigStartValue" SG_ 300 EPS_MODE_STAT "0200FF0000000000h";
BA_ "GenSigTimeout_CBC" SG_ 300 EPS_MODE_STAT 1050;
BA_ "FlexKomSID" SG_ 300 EPS_MODE_STAT 846;
BA_ "FlexKomSigStartPos" SG_ 300 EPS_MODE_STAT 7;
BA_ "FlexKomSigLaenge" SG_ 300 EPS_MODE_STAT 64;
BA_ "FlexKomSigName" SG_ 300 EPS_MODE_STAT "EPS_A1_PKT";
BA_ "FlexKomComment" SG_ 300 EPS_MODE_STAT "EPS_A1_PKT";
BA_ "FlexKomIsMotorola" SG_ 300 EPS_MODE_STAT 1;
BA_ "GenSigSNA" SG_ 300 EPS_MODE_STAT "7h";
BA_ "GenSigCycleTime" SG_ 300 EPS_Curr 100;
BA_ "FlexKomSigStartValue" SG_ 300 EPS_Curr "0200FF0000000000h";
BA_ "GenSigStartValue" SG_ 300 EPS_Curr 255;
BA_ "FlexKomSID" SG_ 300 EPS_Curr 846;
BA_ "FlexKomSigStartPos" SG_ 300 EPS_Curr 7;
BA_ "FlexKomSigLaenge" SG_ 300 EPS_Curr 64;
BA_ "FlexKomSigName" SG_ 300 EPS_Curr "EPS_A1_PKT";
BA_ "FlexKomComment" SG_ 300 EPS_Curr "EPS_A1_PKT";
BA_ "FlexKomIsMotorola" SG_ 300 EPS_Curr 1;
BA_ "GenSigSNA" SG_ 300 EPS_Curr "FFh";
BA_ "GenSigCycleTime" SG_ 308 SpeedLimitSts 20;
BA_ "FlexKomSigStartValue" SG_ 308 SpeedLimitSts "02h";
BA_ "GenSigStartValue" SG_ 308 SpeedLimitSts 2;
BA_ "GenSigTimeout_IC" SG_ 308 SpeedLimitSts 210;
BA_ "FlexKomSID" SG_ 308 SpeedLimitSts 1865;
BA_ "FlexKomSigStartPos" SG_ 308 SpeedLimitSts 4;
BA_ "FlexKomSigLaenge" SG_ 308 SpeedLimitSts 3;
BA_ "FlexKomSigName" SG_ 308 SpeedLimitSts "SpeedLimitSts";
BA_ "FlexKomComment" SG_ 308 SpeedLimitSts "Speed limiter status";
BA_ "FlexKomIsMotorola" SG_ 308 SpeedLimitSts 1;
BA_ "GenSigSNA" SG_ 308 SpeedLimitSts "7h";
BA_ "GenSigCycleTime" SG_ 308 CRUISE_EGD 20;
BA_ "FlexKomSigStartValue" SG_ 308 CRUISE_EGD "00h";
BA_ "GenSigTimeout_CBC" SG_ 308 CRUISE_EGD 210;
BA_ "GenSigTimeout_IC" SG_ 308 CRUISE_EGD 210;
BA_ "GenSigTimeout_ORC" SG_ 308 CRUISE_EGD 70;
BA_ "FlexKomSID" SG_ 308 CRUISE_EGD 856;
BA_ "FlexKomSigStartPos" SG_ 308 CRUISE_EGD 5;
BA_ "FlexKomSigLaenge" SG_ 308 CRUISE_EGD 1;
BA_ "FlexKomSigName" SG_ 308 CRUISE_EGD "CRUISE_EGD";
BA_ "FlexKomComment" SG_ 308 CRUISE_EGD "Cruise system is controlling speed";
BA_ "FlexKomIsMotorola" SG_ 308 CRUISE_EGD 1;
BA_ "GenSigSNA" SG_ 308 CRUISE_EGD "0h";
BA_ "GenSigCycleTime" SG_ 308 CRUISE_ON 20;
BA_ "FlexKomSigStartValue" SG_ 308 CRUISE_ON "00h";
BA_ "GenSigTimeout_IC" SG_ 308 CRUISE_ON 210;
BA_ "GenSigTimeout_SCCM" SG_ 308 CRUISE_ON 210;
BA_ "GenSigTimeout_ORC" SG_ 308 CRUISE_ON 70;
BA_ "FlexKomSID" SG_ 308 CRUISE_ON 1250;
BA_ "FlexKomSigStartPos" SG_ 308 CRUISE_ON 7;
BA_ "FlexKomSigLaenge" SG_ 308 CRUISE_ON 1;
BA_ "FlexKomSigName" SG_ 308 CRUISE_ON "CRUISE_ON";
BA_ "FlexKomComment" SG_ 308 CRUISE_ON "Cruise control system 'on'";
BA_ "FlexKomIsMotorola" SG_ 308 CRUISE_ON 1;
BA_ "GenSigSNA" SG_ 308 CRUISE_ON "0h";
BA_ "GenSigCycleTime" SG_ 308 V_MAX_TM 20;
BA_ "FlexKomSigStartValue" SG_ 308 V_MAX_TM "FFh";
BA_ "GenSigStartValue" SG_ 308 V_MAX_TM 255;
BA_ "FlexKomSID" SG_ 308 V_MAX_TM 1252;
BA_ "FlexKomSigStartPos" SG_ 308 V_MAX_TM 15;
BA_ "FlexKomSigLaenge" SG_ 308 V_MAX_TM 8;
BA_ "FlexKomSigName" SG_ 308 V_MAX_TM "V_MAX_TM";
BA_ "FlexKomComment" SG_ 308 V_MAX_TM "Max. or cruise control set speed";
BA_ "FlexKomIsMotorola" SG_ 308 V_MAX_TM 1;
BA_ "GenSigSNA" SG_ 308 V_MAX_TM "FFh";
BA_ "GenSigCycleTime" SG_ 308 MAP_ENG 20;
BA_ "FlexKomSigStartValue" SG_ 308 MAP_ENG "FF00FFFF00FFh";
BA_ "GenSigStartValue" SG_ 308 MAP_ENG 255;
BA_ "GenSigTimeout_ETM" SG_ 308 MAP_ENG 1010;
BA_ "FlexKomSID" SG_ 308 MAP_ENG 1352;
BA_ "FlexKomSigStartPos" SG_ 308 MAP_ENG 23;
BA_ "FlexKomSigLaenge" SG_ 308 MAP_ENG 48;
BA_ "FlexKomSigName" SG_ 308 MAP_ENG "Engine_1_Pkt";
BA_ "FlexKomComment" SG_ 308 MAP_ENG "General engine Data";
BA_ "FlexKomIsMotorola" SG_ 308 MAP_ENG 1;
BA_ "GenSigSNA" SG_ 308 MAP_ENG "FFh";
BA_ "GenSigCycleTime" SG_ 308 BARO_ENG 20;
BA_ "FlexKomSigStartValue" SG_ 308 BARO_ENG "FF00FFFF00FFh";
BA_ "FlexKomSID" SG_ 308 BARO_ENG 1352;
BA_ "FlexKomSigStartPos" SG_ 308 BARO_ENG 23;
BA_ "FlexKomSigLaenge" SG_ 308 BARO_ENG 48;
BA_ "FlexKomSigName" SG_ 308 BARO_ENG "Engine_1_Pkt";
BA_ "FlexKomComment" SG_ 308 BARO_ENG "General engine Data";
BA_ "FlexKomIsMotorola" SG_ 308 BARO_ENG 1;
BA_ "GenSigSNA" SG_ 308 BARO_ENG "FFh";
BA_ "GenSigCycleTime" SG_ 308 Rel_Thrt_ENG 20;
BA_ "FlexKomSigStartValue" SG_ 308 Rel_Thrt_ENG "FF00FFFF00FFh";
BA_ "GenSigStartValue" SG_ 308 Rel_Thrt_ENG 255;
BA_ "FlexKomSID" SG_ 308 Rel_Thrt_ENG 1352;
BA_ "FlexKomSigStartPos" SG_ 308 Rel_Thrt_ENG 23;
BA_ "FlexKomSigLaenge" SG_ 308 Rel_Thrt_ENG 48;
BA_ "FlexKomSigName" SG_ 308 Rel_Thrt_ENG "Engine_1_Pkt";
BA_ "FlexKomComment" SG_ 308 Rel_Thrt_ENG "General engine Data";
BA_ "FlexKomIsMotorola" SG_ 308 Rel_Thrt_ENG 1;
BA_ "GenSigSNA" SG_ 308 Rel_Thrt_ENG "FFh";
BA_ "GenSigCycleTime" SG_ 308 Rel_Pdl_ENG 20;
BA_ "FlexKomSigStartValue" SG_ 308 Rel_Pdl_ENG "FF00FFFF00FFh";
BA_ "GenSigStartValue" SG_ 308 Rel_Pdl_ENG 255;
BA_ "FlexKomSID" SG_ 308 Rel_Pdl_ENG 1352;
BA_ "FlexKomSigStartPos" SG_ 308 Rel_Pdl_ENG 23;
BA_ "FlexKomSigLaenge" SG_ 308 Rel_Pdl_ENG 48;
BA_ "FlexKomSigName" SG_ 308 Rel_Pdl_ENG "Engine_1_Pkt";
BA_ "FlexKomComment" SG_ 308 Rel_Pdl_ENG "General engine Data";
BA_ "FlexKomIsMotorola" SG_ 308 Rel_Pdl_ENG 1;
BA_ "GenSigSNA" SG_ 308 Rel_Pdl_ENG "FFh";
BA_ "GenSigCycleTime" SG_ 308 MC_134h 20;
BA_ "FlexKomSigStartValue" SG_ 308 MC_134h "FF00FFFF00FFh";
BA_ "FlexKomSID" SG_ 308 MC_134h 1352;
BA_ "FlexKomSigStartPos" SG_ 308 MC_134h 23;
BA_ "FlexKomSigLaenge" SG_ 308 MC_134h 48;
BA_ "FlexKomSigName" SG_ 308 MC_134h "Engine_1_Pkt";
BA_ "FlexKomComment" SG_ 308 MC_134h "General engine Data";
BA_ "FlexKomIsMotorola" SG_ 308 MC_134h 1;
BA_ "GenSigSNA" SG_ 308 MC_134h "0h";
BA_ "GenSigCycleTime" SG_ 308 BoostVacGauge 20;
BA_ "FlexKomSigStartValue" SG_ 308 BoostVacGauge "FF00FFFF00FFh";
BA_ "GenSigStartValue" SG_ 308 BoostVacGauge 255;
BA_ "GenSigTimeout_CBC" SG_ 308 BoostVacGauge 210;
BA_ "GenSigTimeout_IC" SG_ 308 BoostVacGauge 210;
BA_ "FlexKomSID" SG_ 308 BoostVacGauge 1352;
BA_ "FlexKomSigStartPos" SG_ 308 BoostVacGauge 23;
BA_ "FlexKomSigLaenge" SG_ 308 BoostVacGauge 48;
BA_ "FlexKomSigName" SG_ 308 BoostVacGauge "Engine_1_Pkt";
BA_ "FlexKomComment" SG_ 308 BoostVacGauge "General engine Data";
BA_ "FlexKomIsMotorola" SG_ 308 BoostVacGauge 1;
BA_ "GenSigSNA" SG_ 308 BoostVacGauge "FFh";
BA_ "GenSigCycleTime" SG_ 320 Brk_Stat 20;
BA_ "FlexKomSigStartValue" SG_ 320 Brk_Stat "0F3400C003FF00FFh";
BA_ "GenSigStartValue" SG_ 320 Brk_Stat 3;
BA_ "GenSigTimeout_CBC" SG_ 320 Brk_Stat 210;
BA_ "GenSigTimeout_ORC" SG_ 320 Brk_Stat 70;
BA_ "FlexKomSigStartPos" SG_ 320 Brk_Stat 7;
BA_ "FlexKomSigLaenge" SG_ 320 Brk_Stat 64;
BA_ "FlexKomSigName" SG_ 320 Brk_Stat "ESP_BRK_STAT";
BA_ "FlexKomComment" SG_ 320 Brk_Stat "ESP Brake Status Information";
BA_ "FlexKomIsMotorola" SG_ 320 Brk_Stat 1;
BA_ "GenSigSNA" SG_ 320 Brk_Stat "3h";
BA_ "GenSigCycleTime" SG_ 320 BrkPdl_Stat 20;
BA_ "FlexKomSigStartValue" SG_ 320 BrkPdl_Stat "0F3400C003FF00FFh";
BA_ "GenSigStartValue" SG_ 320 BrkPdl_Stat 3;
BA_ "GenSigTimeout_CBC" SG_ 320 BrkPdl_Stat 510;
BA_ "GenSigTimeout_IC" SG_ 320 BrkPdl_Stat 210;
BA_ "GenSigTimeout_ORC" SG_ 320 BrkPdl_Stat 70;
BA_ "GenSigTimeout_ETM" SG_ 320 BrkPdl_Stat 210;
BA_ "FlexKomSigStartPos" SG_ 320 BrkPdl_Stat 7;
BA_ "FlexKomSigLaenge" SG_ 320 BrkPdl_Stat 64;
BA_ "FlexKomSigName" SG_ 320 BrkPdl_Stat "ESP_BRK_STAT";
BA_ "FlexKomComment" SG_ 320 BrkPdl_Stat "ESP Brake Status Information";
BA_ "FlexKomIsMotorola" SG_ 320 BrkPdl_Stat 1;
BA_ "GenSigSNA" SG_ 320 BrkPdl_Stat "3h";
BA_ "GenSigCycleTime" SG_ 320 BrkPdl_Flt 20;
BA_ "FlexKomSigStartValue" SG_ 320 BrkPdl_Flt "0F3400C003FF00FFh";
BA_ "FlexKomSigStartPos" SG_ 320 BrkPdl_Flt 7;
BA_ "FlexKomSigLaenge" SG_ 320 BrkPdl_Flt 64;
BA_ "FlexKomSigName" SG_ 320 BrkPdl_Flt "ESP_BRK_STAT";
BA_ "FlexKomComment" SG_ 320 BrkPdl_Flt "ESP Brake Status Information";
BA_ "FlexKomIsMotorola" SG_ 320 BrkPdl_Flt 1;
BA_ "GenSigSNA" SG_ 320 BrkPdl_Flt "0h";
BA_ "GenSigCycleTime" SG_ 320 BrkIntrvntn_Actv_ESP 20;
BA_ "FlexKomSigStartValue" SG_ 320 BrkIntrvntn_Actv_ESP "0F3400C003FF00FFh";
BA_ "GenSigTimeout_ORC" SG_ 320 BrkIntrvntn_Actv_ESP 70;
BA_ "FlexKomSigStartPos" SG_ 320 BrkIntrvntn_Actv_ESP 7;
BA_ "FlexKomSigLaenge" SG_ 320 BrkIntrvntn_Actv_ESP 64;
BA_ "FlexKomSigName" SG_ 320 BrkIntrvntn_Actv_ESP "ESP_BRK_STAT";
BA_ "FlexKomComment" SG_ 320 BrkIntrvntn_Actv_ESP "ESP Brake Status Information";
BA_ "FlexKomIsMotorola" SG_ 320 BrkIntrvntn_Actv_ESP 1;
BA_ "GenSigSNA" SG_ 320 BrkIntrvntn_Actv_ESP "0h";
BA_ "GenSigCycleTime" SG_ 320 BrkIntrvntn_Actv_AS 20;
BA_ "FlexKomSigStartValue" SG_ 320 BrkIntrvntn_Actv_AS "0F3400C003FF00FFh";
BA_ "GenSigTimeout_ORC" SG_ 320 BrkIntrvntn_Actv_AS 70;
BA_ "FlexKomSigStartPos" SG_ 320 BrkIntrvntn_Actv_AS 7;
BA_ "FlexKomSigLaenge" SG_ 320 BrkIntrvntn_Actv_AS 64;
BA_ "FlexKomSigName" SG_ 320 BrkIntrvntn_Actv_AS "ESP_BRK_STAT";
BA_ "FlexKomComment" SG_ 320 BrkIntrvntn_Actv_AS "ESP Brake Status Information";
BA_ "FlexKomIsMotorola" SG_ 320 BrkIntrvntn_Actv_AS 1;
BA_ "GenSigSNA" SG_ 320 BrkIntrvntn_Actv_AS "0h";
BA_ "GenSigCycleTime" SG_ 320 BrkIntrvntn_Enbl 20;
BA_ "FlexKomSigStartValue" SG_ 320 BrkIntrvntn_Enbl "0F3400C003FF00FFh";
BA_ "GenSigTimeout_ORC" SG_ 320 BrkIntrvntn_Enbl 70;
BA_ "FlexKomSigStartPos" SG_ 320 BrkIntrvntn_Enbl 7;
BA_ "FlexKomSigLaenge" SG_ 320 BrkIntrvntn_Enbl 64;
BA_ "FlexKomSigName" SG_ 320 BrkIntrvntn_Enbl "ESP_BRK_STAT";
BA_ "FlexKomComment" SG_ 320 BrkIntrvntn_Enbl "ESP Brake Status Information";
BA_ "FlexKomIsMotorola" SG_ 320 BrkIntrvntn_Enbl 1;
BA_ "GenSigSNA" SG_ 320 BrkIntrvntn_Enbl "0h";
BA_ "GenSigCycleTime" SG_ 320 EmgBrk_Actv 20;
BA_ "FlexKomSigStartValue" SG_ 320 EmgBrk_Actv "0F3400C003FF00FFh";
BA_ "GenSigTimeout_ORC" SG_ 320 EmgBrk_Actv 70;
BA_ "FlexKomSigStartPos" SG_ 320 EmgBrk_Actv 7;
BA_ "FlexKomSigLaenge" SG_ 320 EmgBrk_Actv 64;
BA_ "FlexKomSigName" SG_ 320 EmgBrk_Actv "ESP_BRK_STAT";
BA_ "FlexKomComment" SG_ 320 EmgBrk_Actv "ESP Brake Status Information";
BA_ "FlexKomIsMotorola" SG_ 320 EmgBrk_Actv 1;
BA_ "GenSigSNA" SG_ 320 EmgBrk_Actv "0h";
BA_ "GenSigCycleTime" SG_ 320 FullBrk_Actv 20;
BA_ "FlexKomSigStartValue" SG_ 320 FullBrk_Actv "0F3400C003FF00FFh";
BA_ "GenSigTimeout_CBC" SG_ 320 FullBrk_Actv 210;
BA_ "GenSigTimeout_IC" SG_ 320 FullBrk_Actv 210;
BA_ "GenSigTimeout_ORC" SG_ 320 FullBrk_Actv 70;
BA_ "FlexKomSigStartPos" SG_ 320 FullBrk_Actv 7;
BA_ "FlexKomSigLaenge" SG_ 320 FullBrk_Actv 64;
BA_ "FlexKomSigName" SG_ 320 FullBrk_Actv "ESP_BRK_STAT";
BA_ "FlexKomComment" SG_ 320 FullBrk_Actv "ESP Brake Status Information";
BA_ "FlexKomIsMotorola" SG_ 320 FullBrk_Actv 1;
BA_ "GenSigSNA" SG_ 320 FullBrk_Actv "0h";
BA_ "GenSigCycleTime" SG_ 320 ESP_Sys_Stat 20;
BA_ "FlexKomSigStartValue" SG_ 320 ESP_Sys_Stat "0F3400C003FF00FFh";
BA_ "GenSigStartValue" SG_ 320 ESP_Sys_Stat 1;
BA_ "GenSigTimeout_IC" SG_ 320 ESP_Sys_Stat 210;
BA_ "GenSigTimeout_ORC" SG_ 320 ESP_Sys_Stat 70;
BA_ "FlexKomSigStartPos" SG_ 320 ESP_Sys_Stat 7;
BA_ "FlexKomSigLaenge" SG_ 320 ESP_Sys_Stat 64;
BA_ "FlexKomSigName" SG_ 320 ESP_Sys_Stat "ESP_BRK_STAT";
BA_ "FlexKomComment" SG_ 320 ESP_Sys_Stat "ESP Brake Status Information";
BA_ "FlexKomIsMotorola" SG_ 320 ESP_Sys_Stat 1;
BA_ "GenSigSNA" SG_ 320 ESP_Sys_Stat "1h";
BA_ "GenSigCycleTime" SG_ 320 SelSpdSts 20;
BA_ "FlexKomSigStartValue" SG_ 320 SelSpdSts "0F3400C003FF00FFh";
BA_ "GenSigStartValue" SG_ 320 SelSpdSts 3;
BA_ "GenSigTimeout_CBC" SG_ 320 SelSpdSts 210;
BA_ "GenSigTimeout_IC" SG_ 320 SelSpdSts 210;
BA_ "GenSigTimeout_ORC" SG_ 320 SelSpdSts 70;
BA_ "GenSigTimeout_ETM" SG_ 320 SelSpdSts 210;
BA_ "FlexKomSigStartPos" SG_ 320 SelSpdSts 7;
BA_ "FlexKomSigLaenge" SG_ 320 SelSpdSts 64;
BA_ "FlexKomSigName" SG_ 320 SelSpdSts "ESP_BRK_STAT";
BA_ "FlexKomComment" SG_ 320 SelSpdSts "ESP Brake Status Information";
BA_ "FlexKomIsMotorola" SG_ 320 SelSpdSts 1;
BA_ "GenSigSNA" SG_ 320 SelSpdSts "3h";
BA_ "GenSigCycleTime" SG_ 320 ABS_BrkEvt 20;
BA_ "FlexKomSigStartValue" SG_ 320 ABS_BrkEvt "0F3400C003FF00FFh";
BA_ "GenSigTimeout_ORC" SG_ 320 ABS_BrkEvt 70;
BA_ "GenSigTimeout_ETM" SG_ 320 ABS_BrkEvt 210;
BA_ "FlexKomSigStartPos" SG_ 320 ABS_BrkEvt 7;
BA_ "FlexKomSigLaenge" SG_ 320 ABS_BrkEvt 64;
BA_ "FlexKomSigName" SG_ 320 ABS_BrkEvt "ESP_BRK_STAT";
BA_ "FlexKomComment" SG_ 320 ABS_BrkEvt "ESP Brake Status Information";
BA_ "FlexKomIsMotorola" SG_ 320 ABS_BrkEvt 1;
BA_ "GenSigSNA" SG_ 320 ABS_BrkEvt "0h";
BA_ "GenSigCycleTime" SG_ 320 DTR_CC_Engaged 20;
BA_ "FlexKomSigStartValue" SG_ 320 DTR_CC_Engaged "0F3400C003FF00FFh";
BA_ "GenSigTimeout_ORC" SG_ 320 DTR_CC_Engaged 70;
BA_ "FlexKomSigStartPos" SG_ 320 DTR_CC_Engaged 7;
BA_ "FlexKomSigLaenge" SG_ 320 DTR_CC_Engaged 64;
BA_ "FlexKomSigName" SG_ 320 DTR_CC_Engaged "ESP_BRK_STAT";
BA_ "FlexKomComment" SG_ 320 DTR_CC_Engaged "ESP Brake Status Information";
BA_ "FlexKomIsMotorola" SG_ 320 DTR_CC_Engaged 1;
BA_ "GenSigSNA" SG_ 320 DTR_CC_Engaged "0h";
BA_ "GenSigCycleTime" SG_ 320 GrMin_Rq_ESC 20;
BA_ "FlexKomSigStartValue" SG_ 320 GrMin_Rq_ESC "0F3400C003FF00FFh";
BA_ "FlexKomSigStartPos" SG_ 320 GrMin_Rq_ESC 7;
BA_ "FlexKomSigLaenge" SG_ 320 GrMin_Rq_ESC 64;
BA_ "FlexKomSigName" SG_ 320 GrMin_Rq_ESC "ESP_BRK_STAT";
BA_ "FlexKomComment" SG_ 320 GrMin_Rq_ESC "ESP Brake Status Information";
BA_ "FlexKomIsMotorola" SG_ 320 GrMin_Rq_ESC 1;
BA_ "GenSigSNA" SG_ 320 GrMin_Rq_ESC "0h";
BA_ "GenSigCycleTime" SG_ 320 GrMax_Rq_ESC 20;
BA_ "FlexKomSigStartValue" SG_ 320 GrMax_Rq_ESC "0F3400C003FF00FFh";
BA_ "FlexKomSigStartPos" SG_ 320 GrMax_Rq_ESC 7;
BA_ "FlexKomSigLaenge" SG_ 320 GrMax_Rq_ESC 64;
BA_ "FlexKomSigName" SG_ 320 GrMax_Rq_ESC "ESP_BRK_STAT";
BA_ "FlexKomComment" SG_ 320 GrMax_Rq_ESC "ESP Brake Status Information";
BA_ "FlexKomIsMotorola" SG_ 320 GrMax_Rq_ESC 1;
BA_ "GenSigSNA" SG_ 320 GrMax_Rq_ESC "0h";
BA_ "GenSigCycleTime" SG_ 320 GrMinMax_Rq_DTR 20;
BA_ "FlexKomSigStartValue" SG_ 320 GrMinMax_Rq_DTR "0F3400C003FF00FFh";
BA_ "GenSigTimeout_ORC" SG_ 320 GrMinMax_Rq_DTR 70;
BA_ "FlexKomSigStartPos" SG_ 320 GrMinMax_Rq_DTR 7;
BA_ "FlexKomSigLaenge" SG_ 320 GrMinMax_Rq_DTR 64;
BA_ "FlexKomSigName" SG_ 320 GrMinMax_Rq_DTR "ESP_BRK_STAT";
BA_ "FlexKomComment" SG_ 320 GrMinMax_Rq_DTR "ESP Brake Status Information";
BA_ "FlexKomIsMotorola" SG_ 320 GrMinMax_Rq_DTR 1;
BA_ "GenSigSNA" SG_ 320 GrMinMax_Rq_DTR "0h";
BA_ "GenSigCycleTime" SG_ 320 DTR_CC_Enabled 20;
BA_ "FlexKomSigStartValue" SG_ 320 DTR_CC_Enabled "0F3400C003FF00FFh";
BA_ "FlexKomSigStartPos" SG_ 320 DTR_CC_Enabled 7;
BA_ "FlexKomSigLaenge" SG_ 320 DTR_CC_Enabled 64;
BA_ "FlexKomSigName" SG_ 320 DTR_CC_Enabled "ESP_BRK_STAT";
BA_ "FlexKomComment" SG_ 320 DTR_CC_Enabled "ESP Brake Status Information";
BA_ "FlexKomIsMotorola" SG_ 320 DTR_CC_Enabled 1;
BA_ "GenSigSNA" SG_ 320 DTR_CC_Enabled "0h";
BA_ "GenSigCycleTime" SG_ 320 Brk_Thermdl 20;
BA_ "FlexKomSigStartValue" SG_ 320 Brk_Thermdl "0F3400C003FF00FFh";
BA_ "FlexKomSigStartPos" SG_ 320 Brk_Thermdl 7;
BA_ "FlexKomSigLaenge" SG_ 320 Brk_Thermdl 64;
BA_ "FlexKomSigName" SG_ 320 Brk_Thermdl "ESP_BRK_STAT";
BA_ "FlexKomComment" SG_ 320 Brk_Thermdl "ESP Brake Status Information";
BA_ "FlexKomIsMotorola" SG_ 320 Brk_Thermdl 1;
BA_ "GenSigSNA" SG_ 320 Brk_Thermdl "0h";
BA_ "GenSigCycleTime" SG_ 320 ShftChrDsp_Rq_ESC 20;
BA_ "FlexKomSigStartValue" SG_ 320 ShftChrDsp_Rq_ESC "0F3400C003FF00FFh";
BA_ "FlexKomSigStartPos" SG_ 320 ShftChrDsp_Rq_ESC 7;
BA_ "FlexKomSigLaenge" SG_ 320 ShftChrDsp_Rq_ESC 64;
BA_ "FlexKomSigName" SG_ 320 ShftChrDsp_Rq_ESC "ESP_BRK_STAT";
BA_ "FlexKomComment" SG_ 320 ShftChrDsp_Rq_ESC "ESP Brake Status Information";
BA_ "FlexKomIsMotorola" SG_ 320 ShftChrDsp_Rq_ESC 1;
BA_ "GenSigSNA" SG_ 320 ShftChrDsp_Rq_ESC "Fh";
BA_ "GenSigCycleTime" SG_ 320 RollTestMd_Actv 20;
BA_ "FlexKomSigStartValue" SG_ 320 RollTestMd_Actv "0F3400C003FF00FFh";
BA_ "GenSigStartValue" SG_ 320 RollTestMd_Actv 3;
BA_ "FlexKomSigStartPos" SG_ 320 RollTestMd_Actv 7;
BA_ "FlexKomSigLaenge" SG_ 320 RollTestMd_Actv 64;
BA_ "FlexKomSigName" SG_ 320 RollTestMd_Actv "ESP_BRK_STAT";
BA_ "FlexKomComment" SG_ 320 RollTestMd_Actv "ESP Brake Status Information";
BA_ "FlexKomIsMotorola" SG_ 320 RollTestMd_Actv 1;
BA_ "GenSigSNA" SG_ 320 RollTestMd_Actv "3h";
BA_ "GenSigCycleTime" SG_ 320 REF_VEH_SPEED 20;
BA_ "FlexKomSigStartValue" SG_ 320 REF_VEH_SPEED "0F3400C003FF00FFh";
BA_ "GenSigStartValue" SG_ 320 REF_VEH_SPEED 1023;
BA_ "GenSigTimeout_IC" SG_ 320 REF_VEH_SPEED 210;
BA_ "GenSigTimeout_ORC" SG_ 320 REF_VEH_SPEED 70;
BA_ "FlexKomSigStartPos" SG_ 320 REF_VEH_SPEED 7;
BA_ "FlexKomSigLaenge" SG_ 320 REF_VEH_SPEED 64;
BA_ "FlexKomSigName" SG_ 320 REF_VEH_SPEED "ESP_BRK_STAT";
BA_ "FlexKomComment" SG_ 320 REF_VEH_SPEED "ESP Brake Status Information";
BA_ "FlexKomIsMotorola" SG_ 320 REF_VEH_SPEED 1;
BA_ "GenSigSNA" SG_ 320 REF_VEH_SPEED "3FFh";
BA_ "GenSigCycleTime" SG_ 320 SPCR_AS_Off_Rq 20;
BA_ "FlexKomSigStartValue" SG_ 320 SPCR_AS_Off_Rq "0F3400C003FF00FFh";
BA_ "FlexKomSigStartPos" SG_ 320 SPCR_AS_Off_Rq 7;
BA_ "FlexKomSigLaenge" SG_ 320 SPCR_AS_Off_Rq 64;
BA_ "FlexKomSigName" SG_ 320 SPCR_AS_Off_Rq "ESP_BRK_STAT";
BA_ "FlexKomComment" SG_ 320 SPCR_AS_Off_Rq "ESP Brake Status Information";
BA_ "FlexKomIsMotorola" SG_ 320 SPCR_AS_Off_Rq 1;
BA_ "GenSigSNA" SG_ 320 SPCR_AS_Off_Rq "0h";
BA_ "GenSigCycleTime" SG_ 320 MC_Brk_Stat 20;
BA_ "FlexKomSigStartValue" SG_ 320 MC_Brk_Stat "0F3400C003FF00FFh";
BA_ "GenSigTimeout_IC" SG_ 320 MC_Brk_Stat 210;
BA_ "GenSigTimeout_ORC" SG_ 320 MC_Brk_Stat 70;
BA_ "FlexKomSigStartPos" SG_ 320 MC_Brk_Stat 7;
BA_ "FlexKomSigLaenge" SG_ 320 MC_Brk_Stat 64;
BA_ "FlexKomSigName" SG_ 320 MC_Brk_Stat "ESP_BRK_STAT";
BA_ "FlexKomComment" SG_ 320 MC_Brk_Stat "ESP Brake Status Information";
BA_ "FlexKomIsMotorola" SG_ 320 MC_Brk_Stat 1;
BA_ "GenSigSNA" SG_ 320 MC_Brk_Stat "0h";
BA_ "GenSigCycleTime" SG_ 320 CRC_Brk_Stat 20;
BA_ "FlexKomSigStartValue" SG_ 320 CRC_Brk_Stat "0F3400C003FF00FFh";
BA_ "GenSigStartValue" SG_ 320 CRC_Brk_Stat 255;
BA_ "GenSigTimeout_IC" SG_ 320 CRC_Brk_Stat 210;
BA_ "GenSigTimeout_ORC" SG_ 320 CRC_Brk_Stat 70;
BA_ "FlexKomSigStartPos" SG_ 320 CRC_Brk_Stat 7;
BA_ "FlexKomSigLaenge" SG_ 320 CRC_Brk_Stat 64;
BA_ "FlexKomSigName" SG_ 320 CRC_Brk_Stat "ESP_BRK_STAT";
BA_ "FlexKomComment" SG_ 320 CRC_Brk_Stat "ESP Brake Status Information";
BA_ "FlexKomIsMotorola" SG_ 320 CRC_Brk_Stat 1;
BA_ "GenSigSNA" SG_ 320 CRC_Brk_Stat "FFh";
BA_ "GenSigCycleTime" SG_ 324 K_STO_B 20;
BA_ "FlexKomSigStartValue" SG_ 324 K_STO_B "000000h";
BA_ "FlexKomSID" SG_ 324 K_STO_B 1129;
BA_ "FlexKomSigStartPos" SG_ 324 K_STO_B 7;
BA_ "FlexKomSigLaenge" SG_ 324 K_STO_B 24;
BA_ "FlexKomSigName" SG_ 324 K_STO_B "K_B";
BA_ "FlexKomComment" SG_ 324 K_STO_B "Torque converter lock-up status";
BA_ "FlexKomIsMotorola" SG_ 324 K_STO_B 1;
BA_ "GenSigSNA" SG_ 324 K_STO_B "0h";
BA_ "GenSigCycleTime" SG_ 324 Ups_Inh_Act 20;
BA_ "FlexKomSigStartValue" SG_ 324 Ups_Inh_Act "00h";
BA_ "FlexKomSID" SG_ 324 Ups_Inh_Act 1532;
BA_ "FlexKomSigStartPos" SG_ 324 Ups_Inh_Act 1;
BA_ "FlexKomSigLaenge" SG_ 324 Ups_Inh_Act 1;
BA_ "FlexKomSigName" SG_ 324 Ups_Inh_Act "Ups_Inh_Act";
BA_ "FlexKomComment" SG_ 324 Ups_Inh_Act "Upshift inhibit active";
BA_ "FlexKomIsMotorola" SG_ 324 Ups_Inh_Act 1;
BA_ "GenSigSNA" SG_ 324 Ups_Inh_Act "0h";
BA_ "GenSigCycleTime" SG_ 324 GearSwitchActiveSts 20;
BA_ "FlexKomSigStartValue" SG_ 324 GearSwitchActiveSts "00h";
BA_ "FlexKomSID" SG_ 324 GearSwitchActiveSts 1528;
BA_ "FlexKomSigStartPos" SG_ 324 GearSwitchActiveSts 2;
BA_ "FlexKomSigLaenge" SG_ 324 GearSwitchActiveSts 1;
BA_ "FlexKomSigName" SG_ 324 GearSwitchActiveSts "GearSwitchActiveSts";
BA_ "FlexKomComment" SG_ 324 GearSwitchActiveSts "Transmission shift in progress";
BA_ "FlexKomIsMotorola" SG_ 324 GearSwitchActiveSts 1;
BA_ "GenSigSNA" SG_ 324 GearSwitchActiveSts "0h";
BA_ "GenSigCycleTime" SG_ 324 OD_OFF 20;
BA_ "FlexKomSigStartValue" SG_ 324 OD_OFF "00h";
BA_ "GenSigTimeout_IC" SG_ 324 OD_OFF 210;
BA_ "FlexKomSID" SG_ 324 OD_OFF 1122;
BA_ "FlexKomSigStartPos" SG_ 324 OD_OFF 3;
BA_ "FlexKomSigLaenge" SG_ 324 OD_OFF 1;
BA_ "FlexKomSigName" SG_ 324 OD_OFF "OD_OFF";
BA_ "FlexKomComment" SG_ 324 OD_OFF "Overdrive lock out";
BA_ "FlexKomIsMotorola" SG_ 324 OD_OFF 1;
BA_ "GenSigSNA" SG_ 324 OD_OFF "0h";
BA_ "GenSigCycleTime" SG_ 324 DrvRst_Hi 20;
BA_ "FlexKomSigStartValue" SG_ 324 DrvRst_Hi "00h";
BA_ "FlexKomSID" SG_ 324 DrvRst_Hi 1124;
BA_ "FlexKomSigStartPos" SG_ 324 DrvRst_Hi 4;
BA_ "FlexKomSigLaenge" SG_ 324 DrvRst_Hi 1;
BA_ "FlexKomSigName" SG_ 324 DrvRst_Hi "DrvRst_Hi";
BA_ "FlexKomComment" SG_ 324 DrvRst_Hi "Drive resistance high/Grade detection";
BA_ "FlexKomIsMotorola" SG_ 324 DrvRst_Hi 1;
BA_ "GenSigSNA" SG_ 324 DrvRst_Hi "0h";
BA_ "GenSigCycleTime" SG_ 324 EngSt_Enbl_Rq_TCM 20;
BA_ "FlexKomSigStartValue" SG_ 324 EngSt_Enbl_Rq_TCM "00h";
BA_ "FlexKomSID" SG_ 324 EngSt_Enbl_Rq_TCM 1125;
BA_ "FlexKomSigStartPos" SG_ 324 EngSt_Enbl_Rq_TCM 5;
BA_ "FlexKomSigLaenge" SG_ 324 EngSt_Enbl_Rq_TCM 1;
BA_ "FlexKomSigName" SG_ 324 EngSt_Enbl_Rq_TCM "EngSt_Enbl_Rq_TCM";
BA_ "FlexKomComment" SG_ 324 EngSt_Enbl_Rq_TCM "Enable engine start request";
BA_ "FlexKomIsMotorola" SG_ 324 EngSt_Enbl_Rq_TCM 1;
BA_ "GenSigSNA" SG_ 324 EngSt_Enbl_Rq_TCM "0h";
BA_ "GenSigCycleTime" SG_ 324 AUTO_STK_EGD 20;
BA_ "FlexKomSigStartValue" SG_ 324 AUTO_STK_EGD "00h";
BA_ "GenSigTimeout_IC" SG_ 324 AUTO_STK_EGD 210;
BA_ "FlexKomSID" SG_ 324 AUTO_STK_EGD 1126;
BA_ "FlexKomSigStartPos" SG_ 324 AUTO_STK_EGD 6;
BA_ "FlexKomSigLaenge" SG_ 324 AUTO_STK_EGD 1;
BA_ "FlexKomSigName" SG_ 324 AUTO_STK_EGD "AUTO_STK_EGD";
BA_ "FlexKomComment" SG_ 324 AUTO_STK_EGD "Autostic Mode Engaged; automatic shift = [0], manu";
BA_ "FlexKomIsMotorola" SG_ 324 AUTO_STK_EGD 1;
BA_ "GenSigSNA" SG_ 324 AUTO_STK_EGD "0h";
BA_ "GenSigCycleTime" SG_ 324 BasShftProg_Ok 20;
BA_ "FlexKomSigStartValue" SG_ 324 BasShftProg_Ok "00h";
BA_ "FlexKomSID" SG_ 324 BasShftProg_Ok 1127;
BA_ "FlexKomSigStartPos" SG_ 324 BasShftProg_Ok 7;
BA_ "FlexKomSigLaenge" SG_ 324 BasShftProg_Ok 1;
BA_ "FlexKomSigName" SG_ 324 BasShftProg_Ok "BasShftProg_Ok";
BA_ "FlexKomComment" SG_ 324 BasShftProg_Ok "Basic shift program o.k; aggressive driving = [0]";
BA_ "FlexKomIsMotorola" SG_ 324 BasShftProg_Ok 1;
BA_ "GenSigSNA" SG_ 324 BasShftProg_Ok "0h";
BA_ "GenSigCycleTime" SG_ 324 Gr 20;
BA_ "FlexKomSigStartValue" SG_ 324 Gr "FF00h";
BA_ "GenSigStartValue" SG_ 324 Gr 15;
BA_ "GenSigTimeout_CBC" SG_ 324 Gr 210;
BA_ "GenSigTimeout_IC" SG_ 324 Gr 210;
BA_ "GenSigTimeout_DTCM" SG_ 324 Gr 210;
BA_ "GenSigTimeout_ORC" SG_ 324 Gr 70;
BA_ "FlexKomSID" SG_ 324 Gr 1128;
BA_ "FlexKomSigStartPos" SG_ 324 Gr 15;
BA_ "FlexKomSigLaenge" SG_ 324 Gr 16;
BA_ "FlexKomSigName" SG_ 324 Gr "Gear_Pkt";
BA_ "FlexKomComment" SG_ 324 Gr "Current Gear/Target Gear";
BA_ "FlexKomIsMotorola" SG_ 324 Gr 1;
BA_ "GenSigSNA" SG_ 324 Gr "Fh";
BA_ "GenSigCycleTime" SG_ 324 Gr_Target 20;
BA_ "FlexKomSigStartValue" SG_ 324 Gr_Target "FF00h";
BA_ "GenSigStartValue" SG_ 324 Gr_Target 15;
BA_ "GenSigTimeout_CBC" SG_ 324 Gr_Target 210;
BA_ "FlexKomSID" SG_ 324 Gr_Target 1128;
BA_ "FlexKomSigStartPos" SG_ 324 Gr_Target 15;
BA_ "FlexKomSigLaenge" SG_ 324 Gr_Target 16;
BA_ "FlexKomSigName" SG_ 324 Gr_Target "Gear_Pkt";
BA_ "FlexKomComment" SG_ 324 Gr_Target "Current Gear/Target Gear";
BA_ "FlexKomIsMotorola" SG_ 324 Gr_Target 1;
BA_ "GenSigSNA" SG_ 324 Gr_Target "Fh";
BA_ "GenSigCycleTime" SG_ 324 KS 20;
BA_ "FlexKomSigStartValue" SG_ 324 KS "FF00h";
BA_ "FlexKomSID" SG_ 324 KS 1128;
BA_ "FlexKomSigStartPos" SG_ 324 KS 15;
BA_ "FlexKomSigLaenge" SG_ 324 KS 16;
BA_ "FlexKomSigName" SG_ 324 KS "Gear_Pkt";
BA_ "FlexKomComment" SG_ 324 KS "Current Gear/Target Gear";
BA_ "FlexKomIsMotorola" SG_ 324 KS 1;
BA_ "GenSigSNA" SG_ 324 KS "0h";
BA_ "GenSigCycleTime" SG_ 324 K_G_B 20;
BA_ "FlexKomSigStartValue" SG_ 324 K_G_B "000000h";
BA_ "FlexKomSID" SG_ 324 K_G_B 1129;
BA_ "FlexKomSigStartPos" SG_ 324 K_G_B 7;
BA_ "FlexKomSigLaenge" SG_ 324 K_G_B 24;
BA_ "FlexKomSigName" SG_ 324 K_G_B "K_B";
BA_ "FlexKomComment" SG_ 324 K_G_B "Torque converter lock-up status";
BA_ "FlexKomIsMotorola" SG_ 324 K_G_B 1;
BA_ "GenSigSNA" SG_ 324 K_G_B "0h";
BA_ "GenSigCycleTime" SG_ 324 K_O_B 20;
BA_ "FlexKomSigStartValue" SG_ 324 K_O_B "000000h";
BA_ "FlexKomSID" SG_ 324 K_O_B 1129;
BA_ "FlexKomSigStartPos" SG_ 324 K_O_B 7;
BA_ "FlexKomSigLaenge" SG_ 324 K_O_B 24;
BA_ "FlexKomSigName" SG_ 324 K_O_B "K_B";
BA_ "FlexKomComment" SG_ 324 K_O_B "Torque converter lock-up status";
BA_ "FlexKomIsMotorola" SG_ 324 K_O_B 1;
BA_ "GenSigSNA" SG_ 324 K_O_B "0h";
BA_ "GenSigCycleTime" SG_ 324 K_S_B 20;
BA_ "FlexKomSigStartValue" SG_ 324 K_S_B "000000h";
BA_ "FlexKomSID" SG_ 324 K_S_B 1129;
BA_ "FlexKomSigStartPos" SG_ 324 K_S_B 7;
BA_ "FlexKomSigLaenge" SG_ 324 K_S_B 24;
BA_ "FlexKomSigName" SG_ 324 K_S_B "K_B";
BA_ "FlexKomComment" SG_ 324 K_S_B "Torque converter lock-up status";
BA_ "FlexKomIsMotorola" SG_ 324 K_S_B 1;
BA_ "GenSigSNA" SG_ 324 K_S_B "0h";
BA_ "GenSigCycleTime" SG_ 324 Trns_EMCC_Achvd 20;
BA_ "FlexKomSigStartValue" SG_ 324 Trns_EMCC_Achvd "00h";
BA_ "FlexKomSID" SG_ 324 Trns_EMCC_Achvd 1130;
BA_ "FlexKomSigStartPos" SG_ 324 Trns_EMCC_Achvd 20;
BA_ "FlexKomSigLaenge" SG_ 324 Trns_EMCC_Achvd 1;
BA_ "FlexKomSigName" SG_ 324 Trns_EMCC_Achvd "Trns_EMCC_Achvd";
BA_ "FlexKomComment" SG_ 324 Trns_EMCC_Achvd "Trans A/C Converter Clutch Slipping; [1] = True";
BA_ "FlexKomIsMotorola" SG_ 324 Trns_EMCC_Achvd 1;
BA_ "GenSigSNA" SG_ 324 Trns_EMCC_Achvd "0h";
BA_ "GenSigCycleTime" SG_ 324 AntiJerkDsbl 20;
BA_ "FlexKomSigStartValue" SG_ 324 AntiJerkDsbl "00h";
BA_ "FlexKomSID" SG_ 324 AntiJerkDsbl 1131;
BA_ "FlexKomSigStartPos" SG_ 324 AntiJerkDsbl 21;
BA_ "FlexKomSigLaenge" SG_ 324 AntiJerkDsbl 1;
BA_ "FlexKomSigName" SG_ 324 AntiJerkDsbl "AntiJerkDsbl";
BA_ "FlexKomComment" SG_ 324 AntiJerkDsbl "Anti-jerk disable";
BA_ "FlexKomIsMotorola" SG_ 324 AntiJerkDsbl 1;
BA_ "GenSigSNA" SG_ 324 AntiJerkDsbl "0h";
BA_ "GenSigCycleTime" SG_ 324 EngBrkCanRq 20;
BA_ "FlexKomSigStartValue" SG_ 324 EngBrkCanRq "00h";
BA_ "FlexKomSID" SG_ 324 EngBrkCanRq 1442;
BA_ "FlexKomSigStartPos" SG_ 324 EngBrkCanRq 22;
BA_ "FlexKomSigLaenge" SG_ 324 EngBrkCanRq 1;
BA_ "FlexKomSigName" SG_ 324 EngBrkCanRq "EngBrkCanRq";
BA_ "FlexKomComment" SG_ 324 EngBrkCanRq "Engine braking cancel request";
BA_ "FlexKomIsMotorola" SG_ 324 EngBrkCanRq 1;
BA_ "GenSigSNA" SG_ 324 EngBrkCanRq "0h";
BA_ "GenSigCycleTime" SG_ 324 PTO_Enbl 20;
BA_ "FlexKomSigStartValue" SG_ 324 PTO_Enbl "00h";
BA_ "FlexKomSID" SG_ 324 PTO_Enbl 1443;
BA_ "FlexKomSigStartPos" SG_ 324 PTO_Enbl 23;
BA_ "FlexKomSigLaenge" SG_ 324 PTO_Enbl 1;
BA_ "FlexKomSigName" SG_ 324 PTO_Enbl "PTO_Enbl";
BA_ "FlexKomComment" SG_ 324 PTO_Enbl "PTO Enabled";
BA_ "FlexKomIsMotorola" SG_ 324 PTO_Enbl 1;
BA_ "GenSigSNA" SG_ 324 PTO_Enbl "0h";
BA_ "GenSigCycleTime" SG_ 324 OUTPUT_SPEED 20;
BA_ "FlexKomSigStartValue" SG_ 324 OUTPUT_SPEED "FFFF000000h";
BA_ "GenSigStartValue" SG_ 324 OUTPUT_SPEED 65535;
BA_ "FlexKomSID" SG_ 324 OUTPUT_SPEED 1605;
BA_ "FlexKomSigStartPos" SG_ 324 OUTPUT_SPEED 31;
BA_ "FlexKomSigLaenge" SG_ 324 OUTPUT_SPEED 40;
BA_ "FlexKomSigName" SG_ 324 OUTPUT_SPEED "OutputSpdPkt";
BA_ "FlexKomComment" SG_ 324 OUTPUT_SPEED "Output shaft speed packet";
BA_ "FlexKomIsMotorola" SG_ 324 OUTPUT_SPEED 1;
BA_ "GenSigSNA" SG_ 324 OUTPUT_SPEED "FFFFh";
BA_ "GenSigCycleTime" SG_ 324 N_Turb 20;
BA_ "FlexKomSigStartValue" SG_ 324 N_Turb "FFFFh";
BA_ "GenSigStartValue" SG_ 324 N_Turb 65535;
BA_ "FlexKomSID" SG_ 324 N_Turb 1133;
BA_ "FlexKomSigStartPos" SG_ 324 N_Turb 47;
BA_ "FlexKomSigLaenge" SG_ 324 N_Turb 16;
BA_ "FlexKomSigName" SG_ 324 N_Turb "N_Turb";
BA_ "FlexKomComment" SG_ 324 N_Turb "Unfiltered turbine speed (n_t_v)";
BA_ "FlexKomIsMotorola" SG_ 324 N_Turb 1;
BA_ "GenSigSNA" SG_ 324 N_Turb "FFFFh";
BA_ "GenSigCycleTime" SG_ 324 OutputSpdPolarity 20;
BA_ "FlexKomSigStartValue" SG_ 324 OutputSpdPolarity "FFFF000000h";
BA_ "FlexKomSID" SG_ 324 OutputSpdPolarity 1605;
BA_ "FlexKomSigStartPos" SG_ 324 OutputSpdPolarity 31;
BA_ "FlexKomSigLaenge" SG_ 324 OutputSpdPolarity 40;
BA_ "FlexKomSigName" SG_ 324 OutputSpdPolarity "OutputSpdPkt";
BA_ "FlexKomComment" SG_ 324 OutputSpdPolarity "Output shaft speed packet";
BA_ "FlexKomIsMotorola" SG_ 324 OutputSpdPolarity 1;
BA_ "GenSigSNA" SG_ 324 OutputSpdPolarity "3h";
BA_ "GenSigCycleTime" SG_ 324 Gear_Pkt_Parity 20;
BA_ "FlexKomSigStartValue" SG_ 324 Gear_Pkt_Parity "00h";
BA_ "FlexKomSID" SG_ 324 Gear_Pkt_Parity 1904;
BA_ "FlexKomSigStartPos" SG_ 324 Gear_Pkt_Parity 59;
BA_ "FlexKomSigLaenge" SG_ 324 Gear_Pkt_Parity 1;
BA_ "FlexKomSigName" SG_ 324 Gear_Pkt_Parity "Gear_Pkt_Parity";
BA_ "FlexKomComment" SG_ 324 Gear_Pkt_Parity "Gear packet even parity bit";
BA_ "FlexKomIsMotorola" SG_ 324 Gear_Pkt_Parity 1;
BA_ "GenSigSNA" SG_ 324 Gear_Pkt_Parity "0h";
BA_ "GenSigCycleTime" SG_ 324 Gear_Pkt_Counter 20;
BA_ "FlexKomSigStartValue" SG_ 324 Gear_Pkt_Counter "00h";
BA_ "FlexKomSID" SG_ 324 Gear_Pkt_Counter 1905;
BA_ "FlexKomSigStartPos" SG_ 324 Gear_Pkt_Counter 61;
BA_ "FlexKomSigLaenge" SG_ 324 Gear_Pkt_Counter 2;
BA_ "FlexKomSigName" SG_ 324 Gear_Pkt_Counter "Gear_Pkt_Counter";
BA_ "FlexKomComment" SG_ 324 Gear_Pkt_Counter "Gear packet counter";
BA_ "FlexKomIsMotorola" SG_ 324 Gear_Pkt_Counter 1;
BA_ "GenSigSNA" SG_ 324 Gear_Pkt_Counter "0h";
BA_ "GenSigCycleTime" SG_ 324 TCM_TmpManMd 20;
BA_ "FlexKomSigStartValue" SG_ 324 TCM_TmpManMd "00h";
BA_ "GenSigTimeout_IC" SG_ 324 TCM_TmpManMd 210;
BA_ "GenSigTimeout_ESM" SG_ 324 TCM_TmpManMd 210;
BA_ "FlexKomSID" SG_ 324 TCM_TmpManMd 1762;
BA_ "FlexKomSigStartPos" SG_ 324 TCM_TmpManMd 63;
BA_ "FlexKomSigLaenge" SG_ 324 TCM_TmpManMd 2;
BA_ "FlexKomSigName" SG_ 324 TCM_TmpManMd "ManualMdPkt";
BA_ "FlexKomComment" SG_ 324 TCM_TmpManMd "Manual mode packet";
BA_ "FlexKomIsMotorola" SG_ 324 TCM_TmpManMd 1;
BA_ "GenSigSNA" SG_ 324 TCM_TmpManMd "0h";
BA_ "GenSigCycleTime" SG_ 324 TCM_ManMd 20;
BA_ "FlexKomSigStartValue" SG_ 324 TCM_ManMd "00h";
BA_ "GenSigTimeout_IC" SG_ 324 TCM_ManMd 210;
BA_ "GenSigTimeout_ESM" SG_ 324 TCM_ManMd 210;
BA_ "FlexKomSID" SG_ 324 TCM_ManMd 1762;
BA_ "FlexKomSigStartPos" SG_ 324 TCM_ManMd 63;
BA_ "FlexKomSigLaenge" SG_ 324 TCM_ManMd 2;
BA_ "FlexKomSigName" SG_ 324 TCM_ManMd "ManualMdPkt";
BA_ "FlexKomComment" SG_ 324 TCM_ManMd "Manual mode packet";
BA_ "FlexKomIsMotorola" SG_ 324 TCM_ManMd 1;
BA_ "GenSigSNA" SG_ 324 TCM_ManMd "0h";
BA_ "GenSigCycleTime" SG_ 328 WHC 10;
BA_ "FlexKomSigStartValue" SG_ 328 WHC "00h";
BA_ "GenSigTimeout_CBC" SG_ 328 WHC 105;
BA_ "GenSigTimeout_IC" SG_ 328 WHC 105;
BA_ "FlexKomSID" SG_ 328 WHC 88;
BA_ "FlexKomSigStartPos" SG_ 328 WHC 3;
BA_ "FlexKomSigLaenge" SG_ 328 WHC 4;
BA_ "FlexKomSigName" SG_ 328 WHC "WHC";
BA_ "FlexKomComment" SG_ 328 WHC "Transmission selector lever position";
BA_ "FlexKomIsMotorola" SG_ 328 WHC 1;
BA_ "GenSigSNA" SG_ 328 WHC "Fh";
BA_ "GenSigCycleTime" SG_ 329 Shft_Warn 10;
BA_ "FlexKomSigStartValue" SG_ 329 Shft_Warn "00000000FFh";
BA_ "GenSigTimeout_IC" SG_ 329 Shft_Warn 105;
BA_ "FlexKomSID" SG_ 329 Shft_Warn 1944;
BA_ "FlexKomSigStartPos" SG_ 329 Shft_Warn 7;
BA_ "FlexKomSigLaenge" SG_ 329 Shft_Warn 40;
BA_ "FlexKomSigName" SG_ 329 Shft_Warn "ESM_MS1_Pkt";
BA_ "FlexKomComment" SG_ 329 Shft_Warn "Mechanical shifter message packet";
BA_ "FlexKomIsMotorola" SG_ 329 Shft_Warn 1;
BA_ "GenSigSNA" SG_ 329 Shft_Warn "0h";
BA_ "GenSigCycleTime" SG_ 331 BrkPrss_TMC 20;
BA_ "FlexKomSigStartValue" SG_ 331 BrkPrss_TMC "0000FFFF00FF00FFh";
BA_ "GenSigTimeout_ORC" SG_ 331 BrkPrss_TMC 70;
BA_ "GenSigTimeout_ETM" SG_ 331 BrkPrss_TMC 210;
BA_ "FlexKomSID" SG_ 331 BrkPrss_TMC 1416;
BA_ "FlexKomSigStartPos" SG_ 331 BrkPrss_TMC 7;
BA_ "FlexKomSigLaenge" SG_ 331 BrkPrss_TMC 64;
BA_ "FlexKomSigName" SG_ 331 BrkPrss_TMC "ESC_data";
BA_ "FlexKomComment" SG_ 331 BrkPrss_TMC "ESC data";
BA_ "FlexKomIsMotorola" SG_ 331 BrkPrss_TMC 1;
BA_ "GenSigSNA" SG_ 331 BrkPrss_TMC "7FFh";
BA_ "GenSigCycleTime" SG_ 331 EngSpdIntervReq 20;
BA_ "FlexKomSigStartValue" SG_ 331 EngSpdIntervReq "0000FFFF00FF00FFh";
BA_ "FlexKomSID" SG_ 331 EngSpdIntervReq 1416;
BA_ "FlexKomSigStartPos" SG_ 331 EngSpdIntervReq 7;
BA_ "FlexKomSigLaenge" SG_ 331 EngSpdIntervReq 64;
BA_ "FlexKomSigName" SG_ 331 EngSpdIntervReq "ESC_data";
BA_ "FlexKomComment" SG_ 331 EngSpdIntervReq "ESC data";
BA_ "FlexKomIsMotorola" SG_ 331 EngSpdIntervReq 1;
BA_ "GenSigSNA" SG_ 331 EngSpdIntervReq "0h";
BA_ "GenSigCycleTime" SG_ 331 EngSpdInterv 20;
BA_ "FlexKomSigStartValue" SG_ 331 EngSpdInterv "0000FFFF00FF00FFh";
BA_ "GenSigStartValue" SG_ 331 EngSpdInterv 65535;
BA_ "FlexKomSID" SG_ 331 EngSpdInterv 1416;
BA_ "FlexKomSigStartPos" SG_ 331 EngSpdInterv 7;
BA_ "FlexKomSigLaenge" SG_ 331 EngSpdInterv 64;
BA_ "FlexKomSigName" SG_ 331 EngSpdInterv "ESC_data";
BA_ "FlexKomComment" SG_ 331 EngSpdInterv "ESC data";
BA_ "FlexKomIsMotorola" SG_ 331 EngSpdInterv 1;
BA_ "GenSigSNA" SG_ 331 EngSpdInterv "FFFFh";
BA_ "GenSigCycleTime" SG_ 331 HSA_BrkPrss 20;
BA_ "FlexKomSigStartValue" SG_ 331 HSA_BrkPrss "0000FFFF00FF00FFh";
BA_ "GenSigTimeout_ORC" SG_ 331 HSA_BrkPrss 70;
BA_ "GenSigTimeout_ETM" SG_ 331 HSA_BrkPrss 210;
BA_ "FlexKomSID" SG_ 331 HSA_BrkPrss 1416;
BA_ "FlexKomSigStartPos" SG_ 331 HSA_BrkPrss 7;
BA_ "FlexKomSigLaenge" SG_ 331 HSA_BrkPrss 64;
BA_ "FlexKomSigName" SG_ 331 HSA_BrkPrss "ESC_data";
BA_ "FlexKomComment" SG_ 331 HSA_BrkPrss "ESC data";
BA_ "FlexKomIsMotorola" SG_ 331 HSA_BrkPrss 1;
BA_ "GenSigSNA" SG_ 331 HSA_BrkPrss "3Fh";
BA_ "GenSigCycleTime" SG_ 331 ESCSensorPlausFailSts 20;
BA_ "FlexKomSigStartValue" SG_ 331 ESCSensorPlausFailSts "0000FFFF00FF00FFh";
BA_ "GenSigTimeout_ORC" SG_ 331 ESCSensorPlausFailSts 70;
BA_ "FlexKomSID" SG_ 331 ESCSensorPlausFailSts 1416;
BA_ "FlexKomSigStartPos" SG_ 331 ESCSensorPlausFailSts 7;
BA_ "FlexKomSigLaenge" SG_ 331 ESCSensorPlausFailSts 64;
BA_ "FlexKomSigName" SG_ 331 ESCSensorPlausFailSts "ESC_data";
BA_ "FlexKomComment" SG_ 331 ESCSensorPlausFailSts "ESC data";
BA_ "FlexKomIsMotorola" SG_ 331 ESCSensorPlausFailSts 1;
BA_ "GenSigSNA" SG_ 331 ESCSensorPlausFailSts "0h";
BA_ "GenSigCycleTime" SG_ 331 RBM_Act 20;
BA_ "FlexKomSigStartValue" SG_ 331 RBM_Act "0000FFFF00FF00FFh";
BA_ "FlexKomSID" SG_ 331 RBM_Act 1416;
BA_ "FlexKomSigStartPos" SG_ 331 RBM_Act 7;
BA_ "FlexKomSigLaenge" SG_ 331 RBM_Act 64;
BA_ "FlexKomSigName" SG_ 331 RBM_Act "ESC_data";
BA_ "FlexKomComment" SG_ 331 RBM_Act "ESC data";
BA_ "FlexKomIsMotorola" SG_ 331 RBM_Act 1;
BA_ "GenSigSNA" SG_ 331 RBM_Act "0h";
BA_ "GenSigCycleTime" SG_ 331 BrkBstrVac_OBD 20;
BA_ "FlexKomSigStartValue" SG_ 331 BrkBstrVac_OBD "0000FFFF00FF00FFh";
BA_ "GenSigStartValue" SG_ 331 BrkBstrVac_OBD 255;
BA_ "FlexKomSID" SG_ 331 BrkBstrVac_OBD 1416;
BA_ "FlexKomSigStartPos" SG_ 331 BrkBstrVac_OBD 7;
BA_ "FlexKomSigLaenge" SG_ 331 BrkBstrVac_OBD 64;
BA_ "FlexKomSigName" SG_ 331 BrkBstrVac_OBD "ESC_data";
BA_ "FlexKomComment" SG_ 331 BrkBstrVac_OBD "ESC data";
BA_ "FlexKomIsMotorola" SG_ 331 BrkBstrVac_OBD 1;
BA_ "GenSigSNA" SG_ 331 BrkBstrVac_OBD "FFh";
BA_ "GenSigCycleTime" SG_ 331 MC_ESP_A3 20;
BA_ "FlexKomSigStartValue" SG_ 331 MC_ESP_A3 "0000FFFF00FF00FFh";
BA_ "GenSigTimeout_ORC" SG_ 331 MC_ESP_A3 70;
BA_ "FlexKomSID" SG_ 331 MC_ESP_A3 1416;
BA_ "FlexKomSigStartPos" SG_ 331 MC_ESP_A3 7;
BA_ "FlexKomSigLaenge" SG_ 331 MC_ESP_A3 64;
BA_ "FlexKomSigName" SG_ 331 MC_ESP_A3 "ESC_data";
BA_ "FlexKomComment" SG_ 331 MC_ESP_A3 "ESC data";
BA_ "FlexKomIsMotorola" SG_ 331 MC_ESP_A3 1;
BA_ "GenSigSNA" SG_ 331 MC_ESP_A3 "0h";
BA_ "GenSigCycleTime" SG_ 331 CRC_ESP_A3 20;
BA_ "FlexKomSigStartValue" SG_ 331 CRC_ESP_A3 "0000FFFF00FF00FFh";
BA_ "GenSigStartValue" SG_ 331 CRC_ESP_A3 255;
BA_ "GenSigTimeout_ORC" SG_ 331 CRC_ESP_A3 70;
BA_ "FlexKomSID" SG_ 331 CRC_ESP_A3 1416;
BA_ "FlexKomSigStartPos" SG_ 331 CRC_ESP_A3 7;
BA_ "FlexKomSigLaenge" SG_ 331 CRC_ESP_A3 64;
BA_ "FlexKomSigName" SG_ 331 CRC_ESP_A3 "ESC_data";
BA_ "FlexKomComment" SG_ 331 CRC_ESP_A3 "ESC data";
BA_ "FlexKomIsMotorola" SG_ 331 CRC_ESP_A3 1;
BA_ "GenSigSNA" SG_ 331 CRC_ESP_A3 "FFh";
BA_ "GenSigCycleTime" SG_ 332 VehYawRate_Raw 20;
BA_ "FlexKomSigStartValue" SG_ 332 VehYawRate_Raw "FFFFh";
BA_ "GenSigStartValue" SG_ 332 VehYawRate_Raw 65535;
BA_ "GenSigTimeout_CBC" SG_ 332 VehYawRate_Raw 210;
BA_ "GenSigTimeout_DTCM" SG_ 332 VehYawRate_Raw 210;
BA_ "GenSigTimeout_ORC" SG_ 332 VehYawRate_Raw 70;
BA_ "FlexKomSID" SG_ 332 VehYawRate_Raw 1262;
BA_ "FlexKomSigStartPos" SG_ 332 VehYawRate_Raw 7;
BA_ "FlexKomSigLaenge" SG_ 332 VehYawRate_Raw 16;
BA_ "FlexKomSigName" SG_ 332 VehYawRate_Raw "VehYawRate_Raw";
BA_ "FlexKomComment" SG_ 332 VehYawRate_Raw "Vehicle yaw rate unfiltered/unadjusted (+ means le";
BA_ "FlexKomIsMotorola" SG_ 332 VehYawRate_Raw 1;
BA_ "GenSigSNA" SG_ 332 VehYawRate_Raw "FFFFh";
BA_ "GenSigCycleTime" SG_ 332 VehYawRate_Offset 20;
BA_ "FlexKomSigStartValue" SG_ 332 VehYawRate_Offset "FFh";
BA_ "GenSigStartValue" SG_ 332 VehYawRate_Offset 255;
BA_ "GenSigTimeout_CBC" SG_ 332 VehYawRate_Offset 210;
BA_ "GenSigTimeout_ORC" SG_ 332 VehYawRate_Offset 70;
BA_ "GenSigTimeout_ETM" SG_ 332 VehYawRate_Offset 210;
BA_ "FlexKomSID" SG_ 332 VehYawRate_Offset 1263;
BA_ "FlexKomSigStartPos" SG_ 332 VehYawRate_Offset 23;
BA_ "FlexKomSigLaenge" SG_ 332 VehYawRate_Offset 8;
BA_ "FlexKomSigName" SG_ 332 VehYawRate_Offset "VehYawRate_Offset";
BA_ "FlexKomComment" SG_ 332 VehYawRate_Offset "Offset of vehicle yaw rate unfiltered/unadjusted (";
BA_ "FlexKomIsMotorola" SG_ 332 VehYawRate_Offset 1;
BA_ "GenSigSNA" SG_ 332 VehYawRate_Offset "FFh";
BA_ "GenSigCycleTime" SG_ 332 VehAccel_X_Offset 20;
BA_ "FlexKomSigStartValue" SG_ 332 VehAccel_X_Offset "FFh";
BA_ "GenSigStartValue" SG_ 332 VehAccel_X_Offset 255;
BA_ "GenSigTimeout_ORC" SG_ 332 VehAccel_X_Offset 70;
BA_ "GenSigTimeout_ETM" SG_ 332 VehAccel_X_Offset 210;
BA_ "FlexKomSID" SG_ 332 VehAccel_X_Offset 1264;
BA_ "FlexKomSigStartPos" SG_ 332 VehAccel_X_Offset 31;
BA_ "FlexKomSigLaenge" SG_ 332 VehAccel_X_Offset 8;
BA_ "FlexKomSigName" SG_ 332 VehAccel_X_Offset "VehAccel_X_Offset";
BA_ "FlexKomComment" SG_ 332 VehAccel_X_Offset "Offset of vehicle longitudinal acceleration (+ mea";
BA_ "FlexKomIsMotorola" SG_ 332 VehAccel_X_Offset 1;
BA_ "GenSigSNA" SG_ 332 VehAccel_X_Offset "FFh";
BA_ "GenSigCycleTime" SG_ 332 VehAccel_X 20;
BA_ "FlexKomSigStartValue" SG_ 332 VehAccel_X "FFh";
BA_ "GenSigStartValue" SG_ 332 VehAccel_X 255;
BA_ "GenSigTimeout_CBC" SG_ 332 VehAccel_X 210;
BA_ "GenSigTimeout_IC" SG_ 332 VehAccel_X 210;
BA_ "GenSigTimeout_ORC" SG_ 332 VehAccel_X 70;
BA_ "FlexKomSID" SG_ 332 VehAccel_X 1265;
BA_ "FlexKomSigStartPos" SG_ 332 VehAccel_X 39;
BA_ "FlexKomSigLaenge" SG_ 332 VehAccel_X 8;
BA_ "FlexKomSigName" SG_ 332 VehAccel_X "VehAccel_X";
BA_ "FlexKomComment" SG_ 332 VehAccel_X "Vehicle longitudinal acceleration (+ means forward";
BA_ "FlexKomIsMotorola" SG_ 332 VehAccel_X 1;
BA_ "GenSigSNA" SG_ 332 VehAccel_X "FFh";
BA_ "GenSigCycleTime" SG_ 332 VehAccel_Y 20;
BA_ "FlexKomSigStartValue" SG_ 332 VehAccel_Y "FFh";
BA_ "GenSigStartValue" SG_ 332 VehAccel_Y 255;
BA_ "GenSigTimeout_CBC" SG_ 332 VehAccel_Y 210;
BA_ "GenSigTimeout_IC" SG_ 332 VehAccel_Y 210;
BA_ "GenSigTimeout_DTCM" SG_ 332 VehAccel_Y 210;
BA_ "GenSigTimeout_ADCM" SG_ 332 VehAccel_Y 510;
BA_ "GenSigTimeout_ORC" SG_ 332 VehAccel_Y 70;
BA_ "FlexKomSID" SG_ 332 VehAccel_Y 1266;
BA_ "FlexKomSigStartPos" SG_ 332 VehAccel_Y 47;
BA_ "FlexKomSigLaenge" SG_ 332 VehAccel_Y 8;
BA_ "FlexKomSigName" SG_ 332 VehAccel_Y "VehAccel_Y";
BA_ "FlexKomComment" SG_ 332 VehAccel_Y "Vehicle lateral acceleration (+ means left, specif";
BA_ "FlexKomIsMotorola" SG_ 332 VehAccel_Y 1;
BA_ "GenSigSNA" SG_ 332 VehAccel_Y "FFh";
BA_ "GenSigCycleTime" SG_ 332 MC_VEH_DYN_STAT 20;
BA_ "FlexKomSigStartValue" SG_ 332 MC_VEH_DYN_STAT "00h";
BA_ "GenSigTimeout_ORC" SG_ 332 MC_VEH_DYN_STAT 70;
BA_ "GenSigTimeout_ETM" SG_ 332 MC_VEH_DYN_STAT 210;
BA_ "FlexKomSID" SG_ 332 MC_VEH_DYN_STAT 1267;
BA_ "FlexKomSigStartPos" SG_ 332 MC_VEH_DYN_STAT 55;
BA_ "FlexKomSigLaenge" SG_ 332 MC_VEH_DYN_STAT 4;
BA_ "FlexKomSigName" SG_ 332 MC_VEH_DYN_STAT "MC_VEH_DYN_STAT";
BA_ "FlexKomComment" SG_ 332 MC_VEH_DYN_STAT "Message counter";
BA_ "FlexKomIsMotorola" SG_ 332 MC_VEH_DYN_STAT 1;
BA_ "GenSigSNA" SG_ 332 MC_VEH_DYN_STAT "0h";
BA_ "GenSigCycleTime" SG_ 332 VehAccel_Y_Offset 20;
BA_ "FlexKomSigStartValue" SG_ 332 VehAccel_Y_Offset "FFh";
BA_ "GenSigStartValue" SG_ 332 VehAccel_Y_Offset 255;
BA_ "GenSigTimeout_ORC" SG_ 332 VehAccel_Y_Offset 70;
BA_ "GenSigTimeout_ETM" SG_ 332 VehAccel_Y_Offset 210;
BA_ "FlexKomSID" SG_ 332 VehAccel_Y_Offset 1268;
BA_ "FlexKomSigStartPos" SG_ 332 VehAccel_Y_Offset 63;
BA_ "FlexKomSigLaenge" SG_ 332 VehAccel_Y_Offset 8;
BA_ "FlexKomSigName" SG_ 332 VehAccel_Y_Offset "VehAccel_Y_Offset";
BA_ "FlexKomComment" SG_ 332 VehAccel_Y_Offset "Offset of vehicle lateral acceleration (+ means le";
BA_ "FlexKomIsMotorola" SG_ 332 VehAccel_Y_Offset 1;
BA_ "GenSigSNA" SG_ 332 VehAccel_Y_Offset "FFh";
BA_ "GenSigCycleTime" SG_ 344 WhlRPM_FL 20;
BA_ "FlexKomSigStartValue" SG_ 344 WhlRPM_FL "FFFFFFFFFFFFFFFFh";
BA_ "GenSigStartValue" SG_ 344 WhlRPM_FL 16383;
BA_ "GenSigTimeout_DTCM" SG_ 344 WhlRPM_FL 210;
BA_ "GenSigTimeout_ORC" SG_ 344 WhlRPM_FL 70;
BA_ "FlexKomSID" SG_ 344 WhlRPM_FL 64;
BA_ "FlexKomSigStartPos" SG_ 344 WhlRPM_FL 7;
BA_ "FlexKomSigLaenge" SG_ 344 WhlRPM_FL 64;
BA_ "FlexKomSigName" SG_ 344 WhlRPM_FL "WHEEL_SPEED";
BA_ "FlexKomComment" SG_ 344 WhlRPM_FL "ESP Wheel Speed";
BA_ "FlexKomIsMotorola" SG_ 344 WhlRPM_FL 1;
BA_ "GenSigSNA" SG_ 344 WhlRPM_FL "3FFFh";
BA_ "GenSigCycleTime" SG_ 344 WhlDir_FL_Stat 20;
BA_ "FlexKomSigStartValue" SG_ 344 WhlDir_FL_Stat "FFFFFFFFFFFFFFFFh";
BA_ "GenSigStartValue" SG_ 344 WhlDir_FL_Stat 3;
BA_ "GenSigTimeout_ORC" SG_ 344 WhlDir_FL_Stat 70;
BA_ "FlexKomSID" SG_ 344 WhlDir_FL_Stat 64;
BA_ "FlexKomSigStartPos" SG_ 344 WhlDir_FL_Stat 7;
BA_ "FlexKomSigLaenge" SG_ 344 WhlDir_FL_Stat 64;
BA_ "FlexKomSigName" SG_ 344 WhlDir_FL_Stat "WHEEL_SPEED";
BA_ "FlexKomComment" SG_ 344 WhlDir_FL_Stat "ESP Wheel Speed";
BA_ "FlexKomIsMotorola" SG_ 344 WhlDir_FL_Stat 1;
BA_ "GenSigSNA" SG_ 344 WhlDir_FL_Stat "3h";
BA_ "GenSigCycleTime" SG_ 344 WhlRPM_FR 20;
BA_ "FlexKomSigStartValue" SG_ 344 WhlRPM_FR "FFFFFFFFFFFFFFFFh";
BA_ "GenSigStartValue" SG_ 344 WhlRPM_FR 16383;
BA_ "GenSigTimeout_DTCM" SG_ 344 WhlRPM_FR 210;
BA_ "GenSigTimeout_ORC" SG_ 344 WhlRPM_FR 70;
BA_ "FlexKomSID" SG_ 344 WhlRPM_FR 64;
BA_ "FlexKomSigStartPos" SG_ 344 WhlRPM_FR 7;
BA_ "FlexKomSigLaenge" SG_ 344 WhlRPM_FR 64;
BA_ "FlexKomSigName" SG_ 344 WhlRPM_FR "WHEEL_SPEED";
BA_ "FlexKomComment" SG_ 344 WhlRPM_FR "ESP Wheel Speed";
BA_ "FlexKomIsMotorola" SG_ 344 WhlRPM_FR 1;
BA_ "GenSigSNA" SG_ 344 WhlRPM_FR "3FFFh";
BA_ "GenSigCycleTime" SG_ 344 WhlDir_FR_Stat 20;
BA_ "FlexKomSigStartValue" SG_ 344 WhlDir_FR_Stat "FFFFFFFFFFFFFFFFh";
BA_ "GenSigStartValue" SG_ 344 WhlDir_FR_Stat 3;
BA_ "GenSigTimeout_ORC" SG_ 344 WhlDir_FR_Stat 70;
BA_ "FlexKomSID" SG_ 344 WhlDir_FR_Stat 64;
BA_ "FlexKomSigStartPos" SG_ 344 WhlDir_FR_Stat 7;
BA_ "FlexKomSigLaenge" SG_ 344 WhlDir_FR_Stat 64;
BA_ "FlexKomSigName" SG_ 344 WhlDir_FR_Stat "WHEEL_SPEED";
BA_ "FlexKomComment" SG_ 344 WhlDir_FR_Stat "ESP Wheel Speed";
BA_ "FlexKomIsMotorola" SG_ 344 WhlDir_FR_Stat 1;
BA_ "GenSigSNA" SG_ 344 WhlDir_FR_Stat "3h";
BA_ "GenSigCycleTime" SG_ 344 WhlRPM_RL 20;
BA_ "FlexKomSigStartValue" SG_ 344 WhlRPM_RL "FFFFFFFFFFFFFFFFh";
BA_ "GenSigStartValue" SG_ 344 WhlRPM_RL 16383;
BA_ "GenSigTimeout_CBC" SG_ 344 WhlRPM_RL 110;
BA_ "GenSigTimeout_DTCM" SG_ 344 WhlRPM_RL 210;
BA_ "GenSigTimeout_ORC" SG_ 344 WhlRPM_RL 70;
BA_ "FlexKomSID" SG_ 344 WhlRPM_RL 64;
BA_ "FlexKomSigStartPos" SG_ 344 WhlRPM_RL 7;
BA_ "FlexKomSigLaenge" SG_ 344 WhlRPM_RL 64;
BA_ "FlexKomSigName" SG_ 344 WhlRPM_RL "WHEEL_SPEED";
BA_ "FlexKomComment" SG_ 344 WhlRPM_RL "ESP Wheel Speed";
BA_ "FlexKomIsMotorola" SG_ 344 WhlRPM_RL 1;
BA_ "GenSigSNA" SG_ 344 WhlRPM_RL "3FFFh";
BA_ "GenSigCycleTime" SG_ 344 WhlDir_RL_Stat 20;
BA_ "FlexKomSigStartValue" SG_ 344 WhlDir_RL_Stat "FFFFFFFFFFFFFFFFh";
BA_ "GenSigStartValue" SG_ 344 WhlDir_RL_Stat 3;
BA_ "GenSigTimeout_ORC" SG_ 344 WhlDir_RL_Stat 70;
BA_ "FlexKomSID" SG_ 344 WhlDir_RL_Stat 64;
BA_ "FlexKomSigStartPos" SG_ 344 WhlDir_RL_Stat 7;
BA_ "FlexKomSigLaenge" SG_ 344 WhlDir_RL_Stat 64;
BA_ "FlexKomSigName" SG_ 344 WhlDir_RL_Stat "WHEEL_SPEED";
BA_ "FlexKomComment" SG_ 344 WhlDir_RL_Stat "ESP Wheel Speed";
BA_ "FlexKomIsMotorola" SG_ 344 WhlDir_RL_Stat 1;
BA_ "GenSigSNA" SG_ 344 WhlDir_RL_Stat "3h";
BA_ "GenSigCycleTime" SG_ 344 WhlRPM_RR 20;
BA_ "FlexKomSigStartValue" SG_ 344 WhlRPM_RR "FFFFFFFFFFFFFFFFh";
BA_ "GenSigStartValue" SG_ 344 WhlRPM_RR 16383;
BA_ "GenSigTimeout_CBC" SG_ 344 WhlRPM_RR 110;
BA_ "GenSigTimeout_DTCM" SG_ 344 WhlRPM_RR 210;
BA_ "GenSigTimeout_ORC" SG_ 344 WhlRPM_RR 70;
BA_ "FlexKomSID" SG_ 344 WhlRPM_RR 64;
BA_ "FlexKomSigStartPos" SG_ 344 WhlRPM_RR 7;
BA_ "FlexKomSigLaenge" SG_ 344 WhlRPM_RR 64;
BA_ "FlexKomSigName" SG_ 344 WhlRPM_RR "WHEEL_SPEED";
BA_ "FlexKomComment" SG_ 344 WhlRPM_RR "ESP Wheel Speed";
BA_ "FlexKomIsMotorola" SG_ 344 WhlRPM_RR 1;
BA_ "GenSigSNA" SG_ 344 WhlRPM_RR "3FFFh";
BA_ "GenSigCycleTime" SG_ 344 WhlDir_RR_Stat 20;
BA_ "FlexKomSigStartValue" SG_ 344 WhlDir_RR_Stat "FFFFFFFFFFFFFFFFh";
BA_ "GenSigStartValue" SG_ 344 WhlDir_RR_Stat 3;
BA_ "GenSigTimeout_ORC" SG_ 344 WhlDir_RR_Stat 70;
BA_ "FlexKomSID" SG_ 344 WhlDir_RR_Stat 64;
BA_ "FlexKomSigStartPos" SG_ 344 WhlDir_RR_Stat 7;
BA_ "FlexKomSigLaenge" SG_ 344 WhlDir_RR_Stat 64;
BA_ "FlexKomSigName" SG_ 344 WhlDir_RR_Stat "WHEEL_SPEED";
BA_ "FlexKomComment" SG_ 344 WhlDir_RR_Stat "ESP Wheel Speed";
BA_ "FlexKomIsMotorola" SG_ 344 WhlDir_RR_Stat 1;
BA_ "GenSigSNA" SG_ 344 WhlDir_RR_Stat "3h";
BA_ "GenSigCycleTime" SG_ 352 TCASE_STAT 20;
BA_ "FlexKomSigStartValue" SG_ 352 TCASE_STAT "CEC0FFFFFFFFFFFFh";
BA_ "GenSigStartValue" SG_ 352 TCASE_STAT 7;
BA_ "GenSigTimeout_RF_HUB" SG_ 352 TCASE_STAT 210;
BA_ "GenSigTimeout_CBC" SG_ 352 TCASE_STAT 210;
BA_ "GenSigTimeout_IC" SG_ 352 TCASE_STAT 210;
BA_ "GenSigTimeout_PTS" SG_ 352 TCASE_STAT 210;
BA_ "GenSigTimeout_ORC" SG_ 352 TCASE_STAT 70;
BA_ "GenSigTimeout_ETM" SG_ 352 TCASE_STAT 210;
BA_ "FlexKomSID" SG_ 352 TCASE_STAT 807;
BA_ "FlexKomSigStartPos" SG_ 352 TCASE_STAT 7;
BA_ "FlexKomSigLaenge" SG_ 352 TCASE_STAT 64;
BA_ "FlexKomSigName" SG_ 352 TCASE_STAT "DTCM_A1_PKT";
BA_ "FlexKomComment" SG_ 352 TCASE_STAT "DTCM_A1_PKT";
BA_ "FlexKomIsMotorola" SG_ 352 TCASE_STAT 1;
BA_ "GenSigSNA" SG_ 352 TCASE_STAT "7h";
BA_ "GenSigCycleTime" SG_ 352 SHFT_ABRT 20;
BA_ "FlexKomSigStartValue" SG_ 352 SHFT_ABRT "CEC0FFFFFFFFFFFFh";
BA_ "FlexKomSID" SG_ 352 SHFT_ABRT 807;
BA_ "FlexKomSigStartPos" SG_ 352 SHFT_ABRT 7;
BA_ "FlexKomSigLaenge" SG_ 352 SHFT_ABRT 64;
BA_ "FlexKomSigName" SG_ 352 SHFT_ABRT "DTCM_A1_PKT";
BA_ "FlexKomComment" SG_ 352 SHFT_ABRT "DTCM_A1_PKT";
BA_ "FlexKomIsMotorola" SG_ 352 SHFT_ABRT 1;
BA_ "GenSigSNA" SG_ 352 SHFT_ABRT "1h";
BA_ "GenSigCycleTime" SG_ 352 ACT_CNT_DIF_TRQ 20;
BA_ "FlexKomSigStartValue" SG_ 352 ACT_CNT_DIF_TRQ "CEC0FFFFFFFFFFFFh";
BA_ "GenSigStartValue" SG_ 352 ACT_CNT_DIF_TRQ 255;
BA_ "GenSigTimeout_CBC" SG_ 352 ACT_CNT_DIF_TRQ 210;
BA_ "GenSigTimeout_ETM" SG_ 352 ACT_CNT_DIF_TRQ 210;
BA_ "FlexKomSID" SG_ 352 ACT_CNT_DIF_TRQ 807;
BA_ "FlexKomSigStartPos" SG_ 352 ACT_CNT_DIF_TRQ 7;
BA_ "FlexKomSigLaenge" SG_ 352 ACT_CNT_DIF_TRQ 64;
BA_ "FlexKomSigName" SG_ 352 ACT_CNT_DIF_TRQ "DTCM_A1_PKT";
BA_ "FlexKomComment" SG_ 352 ACT_CNT_DIF_TRQ "DTCM_A1_PKT";
BA_ "FlexKomIsMotorola" SG_ 352 ACT_CNT_DIF_TRQ 1;
BA_ "GenSigSNA" SG_ 352 ACT_CNT_DIF_TRQ "FFh";
BA_ "GenSigCycleTime" SG_ 352 ACT_R_DIF_TRQ 20;
BA_ "FlexKomSigStartValue" SG_ 352 ACT_R_DIF_TRQ "CEC0FFFFFFFFFFFFh";
BA_ "GenSigStartValue" SG_ 352 ACT_R_DIF_TRQ 255;
BA_ "GenSigTimeout_CBC" SG_ 352 ACT_R_DIF_TRQ 210;
BA_ "GenSigTimeout_IC" SG_ 352 ACT_R_DIF_TRQ 210;
BA_ "FlexKomSID" SG_ 352 ACT_R_DIF_TRQ 807;
BA_ "FlexKomSigStartPos" SG_ 352 ACT_R_DIF_TRQ 7;
BA_ "FlexKomSigLaenge" SG_ 352 ACT_R_DIF_TRQ 64;
BA_ "FlexKomSigName" SG_ 352 ACT_R_DIF_TRQ "DTCM_A1_PKT";
BA_ "FlexKomComment" SG_ 352 ACT_R_DIF_TRQ "DTCM_A1_PKT";
BA_ "FlexKomIsMotorola" SG_ 352 ACT_R_DIF_TRQ 1;
BA_ "GenSigSNA" SG_ 352 ACT_R_DIF_TRQ "FFh";
BA_ "GenSigCycleTime" SG_ 352 DES_CNT_DIF_TRQ 20;
BA_ "FlexKomSigStartValue" SG_ 352 DES_CNT_DIF_TRQ "CEC0FFFFFFFFFFFFh";
BA_ "GenSigStartValue" SG_ 352 DES_CNT_DIF_TRQ 255;
BA_ "FlexKomSID" SG_ 352 DES_CNT_DIF_TRQ 807;
BA_ "FlexKomSigStartPos" SG_ 352 DES_CNT_DIF_TRQ 7;
BA_ "FlexKomSigLaenge" SG_ 352 DES_CNT_DIF_TRQ 64;
BA_ "FlexKomSigName" SG_ 352 DES_CNT_DIF_TRQ "DTCM_A1_PKT";
BA_ "FlexKomComment" SG_ 352 DES_CNT_DIF_TRQ "DTCM_A1_PKT";
BA_ "FlexKomIsMotorola" SG_ 352 DES_CNT_DIF_TRQ 1;
BA_ "GenSigSNA" SG_ 352 DES_CNT_DIF_TRQ "FFh";
BA_ "GenSigCycleTime" SG_ 353 TC_TrqCltAct 20;
BA_ "FlexKomSigStartValue" SG_ 353 TC_TrqCltAct "000007FF00000FFFh";
BA_ "GenSigStartValue" SG_ 353 TC_TrqCltAct 2047;
BA_ "FlexKomSID" SG_ 353 TC_TrqCltAct 1820;
BA_ "FlexKomSigStartPos" SG_ 353 TC_TrqCltAct 7;
BA_ "FlexKomSigLaenge" SG_ 353 TC_TrqCltAct 64;
BA_ "FlexKomSigName" SG_ 353 TC_TrqCltAct "DTCM_MAS_PKT";
BA_ "FlexKomComment" SG_ 353 TC_TrqCltAct "DTCM_MAS_PKT";
BA_ "FlexKomIsMotorola" SG_ 353 TC_TrqCltAct 1;
BA_ "GenSigSNA" SG_ 353 TC_TrqCltAct "7FFh";
BA_ "GenSigCycleTime" SG_ 353 TC_FaultStat 20;
BA_ "FlexKomSigStartValue" SG_ 353 TC_FaultStat "000007FF00000FFFh";
BA_ "GenSigStartValue" SG_ 353 TC_FaultStat 15;
BA_ "GenSigTimeout_CBC" SG_ 353 TC_FaultStat 210;
BA_ "FlexKomSID" SG_ 353 TC_FaultStat 1820;
BA_ "FlexKomSigStartPos" SG_ 353 TC_FaultStat 7;
BA_ "FlexKomSigLaenge" SG_ 353 TC_FaultStat 64;
BA_ "FlexKomSigName" SG_ 353 TC_FaultStat "DTCM_MAS_PKT";
BA_ "FlexKomComment" SG_ 353 TC_FaultStat "DTCM_MAS_PKT";
BA_ "FlexKomIsMotorola" SG_ 353 TC_FaultStat 1;
BA_ "GenSigSNA" SG_ 353 TC_FaultStat "Fh";
BA_ "GenSigCycleTime" SG_ 353 MC_DTCM_MAS 20;
BA_ "FlexKomSigStartValue" SG_ 353 MC_DTCM_MAS "000007FF00000FFFh";
BA_ "FlexKomSID" SG_ 353 MC_DTCM_MAS 1820;
BA_ "FlexKomSigStartPos" SG_ 353 MC_DTCM_MAS 7;
BA_ "FlexKomSigLaenge" SG_ 353 MC_DTCM_MAS 64;
BA_ "FlexKomSigName" SG_ 353 MC_DTCM_MAS "DTCM_MAS_PKT";
BA_ "FlexKomComment" SG_ 353 MC_DTCM_MAS "DTCM_MAS_PKT";
BA_ "FlexKomIsMotorola" SG_ 353 MC_DTCM_MAS 1;
BA_ "GenSigSNA" SG_ 353 MC_DTCM_MAS "0h";
BA_ "GenSigCycleTime" SG_ 353 CRC_DTCM_MAS 20;
BA_ "FlexKomSigStartValue" SG_ 353 CRC_DTCM_MAS "000007FF00000FFFh";
BA_ "GenSigStartValue" SG_ 353 CRC_DTCM_MAS 255;
BA_ "FlexKomSID" SG_ 353 CRC_DTCM_MAS 1820;
BA_ "FlexKomSigStartPos" SG_ 353 CRC_DTCM_MAS 7;
BA_ "FlexKomSigLaenge" SG_ 353 CRC_DTCM_MAS 64;
BA_ "FlexKomSigName" SG_ 353 CRC_DTCM_MAS "DTCM_MAS_PKT";
BA_ "FlexKomComment" SG_ 353 CRC_DTCM_MAS "DTCM_MAS_PKT";
BA_ "FlexKomIsMotorola" SG_ 353 CRC_DTCM_MAS 1;
BA_ "GenSigSNA" SG_ 353 CRC_DTCM_MAS "FFh";
BA_ "GenSigCycleTime" SG_ 362 DrvLnTrqRq 20;
BA_ "FlexKomSigStartValue" SG_ 362 DrvLnTrqRq "01FF0000000000FFh";
BA_ "GenSigStartValue" SG_ 362 DrvLnTrqRq 511;
BA_ "FlexKomSID" SG_ 362 DrvLnTrqRq 1520;
BA_ "FlexKomSigStartPos" SG_ 362 DrvLnTrqRq 7;
BA_ "FlexKomSigLaenge" SG_ 362 DrvLnTrqRq 64;
BA_ "FlexKomSigName" SG_ 362 DrvLnTrqRq "DTCM_A2_PKT";
BA_ "FlexKomComment" SG_ 362 DrvLnTrqRq "DTCM_A2_PKT";
BA_ "FlexKomIsMotorola" SG_ 362 DrvLnTrqRq 1;
BA_ "GenSigSNA" SG_ 362 DrvLnTrqRq "1FFh";
BA_ "GenSigCycleTime" SG_ 362 DrvLnMinTrqMd 20;
BA_ "FlexKomSigStartValue" SG_ 362 DrvLnMinTrqMd "01FF0000000000FFh";
BA_ "FlexKomSID" SG_ 362 DrvLnMinTrqMd 1520;
BA_ "FlexKomSigStartPos" SG_ 362 DrvLnMinTrqMd 7;
BA_ "FlexKomSigLaenge" SG_ 362 DrvLnMinTrqMd 64;
BA_ "FlexKomSigName" SG_ 362 DrvLnMinTrqMd "DTCM_A2_PKT";
BA_ "FlexKomComment" SG_ 362 DrvLnMinTrqMd "DTCM_A2_PKT";
BA_ "FlexKomIsMotorola" SG_ 362 DrvLnMinTrqMd 1;
BA_ "GenSigSNA" SG_ 362 DrvLnMinTrqMd "0h";
BA_ "GenSigCycleTime" SG_ 362 MC_DTCM_A2 20;
BA_ "FlexKomSigStartValue" SG_ 362 MC_DTCM_A2 "01FF0000000000FFh";
BA_ "FlexKomSID" SG_ 362 MC_DTCM_A2 1520;
BA_ "FlexKomSigStartPos" SG_ 362 MC_DTCM_A2 7;
BA_ "FlexKomSigLaenge" SG_ 362 MC_DTCM_A2 64;
BA_ "FlexKomSigName" SG_ 362 MC_DTCM_A2 "DTCM_A2_PKT";
BA_ "FlexKomComment" SG_ 362 MC_DTCM_A2 "DTCM_A2_PKT";
BA_ "FlexKomIsMotorola" SG_ 362 MC_DTCM_A2 1;
BA_ "GenSigSNA" SG_ 362 MC_DTCM_A2 "0h";
BA_ "GenSigCycleTime" SG_ 362 CRC_DTCM_A2 20;
BA_ "FlexKomSigStartValue" SG_ 362 CRC_DTCM_A2 "01FF0000000000FFh";
BA_ "GenSigStartValue" SG_ 362 CRC_DTCM_A2 255;
BA_ "FlexKomSID" SG_ 362 CRC_DTCM_A2 1520;
BA_ "FlexKomSigStartPos" SG_ 362 CRC_DTCM_A2 7;
BA_ "FlexKomSigLaenge" SG_ 362 CRC_DTCM_A2 64;
BA_ "FlexKomSigName" SG_ 362 CRC_DTCM_A2 "DTCM_A2_PKT";
BA_ "FlexKomComment" SG_ 362 CRC_DTCM_A2 "DTCM_A2_PKT";
BA_ "FlexKomIsMotorola" SG_ 362 CRC_DTCM_A2 1;
BA_ "GenSigSNA" SG_ 362 CRC_DTCM_A2 "FFh";
VAL_ 257 ECM_SKIM_STAT 3 "SNA" 2 "RUN" 1 "KILL" 0 "OK" ;
VAL_ 257 RAD_FAN1_STAT 255 "SNA" ;
VAL_ 258 LRW 16383 "SNA" ;
VAL_ 258 VLRW 16383 "SNA" ;
VAL_ 258 LRWS_ST 3 "ERR_INI" 2 "ERR" 1 "INI" 0 "OK" ;
VAL_ 258 Pad_Shft 7 "SNA" 3 "PS_BOTH" 2 "PS_LEFT" 1 "PS_RIGHT" 0 "PS_OFF" ;
VAL_ 258 ERS_ACC_SW 7 "SNA" 2 "MODE_ERS_M" 1 "WA_ERS_P" 0 "ERS_OFF" ;
VAL_ 264 EngRPM 65535 "SNA" ;
VAL_ 264 EngTrqStatic 8191 "SNA" ;
VAL_ 264 ExpEngTrq 8191 "SNA" ;
VAL_ 268 EngTrq_Rq_ESC 8191 "SNA" ;
VAL_ 268 EngTrq_Rq_As 8191 "SNA" ;
VAL_ 268 BrkBstrVac 255 "SNA" ;
VAL_ 268 TrlrBrkRq 63 "SNA" ;
VAL_ 268 DAS_RqActv 7 "SNA" 4 "LSCM" 3 "ABA" 2 "CMS" 1 "ACC" 0 "IDLE" ;
VAL_ 269 EngTrq_Rq_SlowESC 8191 "SNA" ;
VAL_ 269 EngTrq_Rq_FastESC 8191 "SNA" ;
VAL_ 274 CmdIgnStat 7 "SNA" 5 "IGN_START" 4 "IGN_RUN" 3 "IGN_OFF_ACC" 2 "IGN_ACC" 1 "IGN_OFF" 0 "IGN_LK" ;
VAL_ 274 StTyp 7 "SNA" 3 "REM_ST" 2 "TIP_ST" 1 "NOR_ST" 0 "ST_NOT_ACT" ;
VAL_ 274 KeyInIgn 3 "SNA" 2 "KEY_IN_IGN" 1 "KEY_NOT_IN_IGN" 0 "KEY_DEF" ;
VAL_ 274 ERS_SW 3 "SNA" 2 "ERS_MI" 1 "ERS_PL" 0 "ERS_NPSD" ;
VAL_ 280 EngTrqMax 8191 "SNA" ;
VAL_ 280 EngTrqMin 8191 "SNA" ;
VAL_ 280 M_EFF 8191 "SNA" ;
VAL_ 280 TACH_FREEZE 0 "SNA" ;
VAL_ 280 StartRelayBCMCmd 0 "SNA" ;
VAL_ 284 BrkTrq 4095 "SNA" ;
VAL_ 284 BrkTrq_D 4095 "SNA" ;
VAL_ 284 VEH_SPEED 65535 "SNA" ;
VAL_ 288 EngTrqSel_D_TTC 8191 "SNA" ;
VAL_ 288 AccelPdlPosn 255 "SNA" ;
VAL_ 288 EngTrq_DrvReqMod 8191 "SNA" ;
VAL_ 290 KUEB_O_A 0 "SNA" ;
VAL_ 290 KUEB_S_A 0 "SNA" ;
VAL_ 290 S_EGT 3 "SNA" 2 "RSVD" 1 "ASST_REQ" 0 "NO_REQ" ;
VAL_ 290 EngTrqMaxCorrFctr 255 "SNA" ;
VAL_ 290 GrMin_Rq_ECM 7 "G7" 6 "G6" 5 "G5" 4 "G4" 3 "G3" 2 "G2" 1 "G1" 0 "PASSIVE" ;
VAL_ 290 GrMax_Rq_ECM 7 "G7" 6 "G6" 5 "G5" 4 "G4" 3 "G3" 2 "G2" 1 "G1" 0 "PASSIVE" ;
VAL_ 290 TxGearDes 15 "SNA" 14 "KRAFTFREI" 13 "P" 12 "R2" 11 "R" 10 "D9" 9 "D2P" 8 "D8" 7 "D7" 6 "D6" 5 "D5" 4 "D4" 3 "D3" 2 "D2" 1 "D1" 0 "N" ;
VAL_ 290 ShftChrDsp_Rq 15 "SNA" 12 "SKL12" 11 "SKL11" 10 "SKL10" 9 "SKL9" 8 "SKL8" 7 "SKL7" 6 "SKL6" 5 "SKL5" 4 "SKL4" 3 "SKL3" 2 "SKL2" 1 "SKL1" 0 "SKL0" ;
VAL_ 290 NMOTS 65535 "SNA" ;
VAL_ 292 WhlPlsCnt_FL 255 "SNA" ;
VAL_ 292 WhlPlsCnt_FR 255 "SNA" ;
VAL_ 292 WhlPlsCnt_RL 255 "SNA" ;
VAL_ 292 WhlPlsCnt_RR 255 "SNA" ;
VAL_ 292 FT_DIFF_ESP_RQ 3 "SNA" 2 "OPEN" 1 "HOLD" 0 "FREE" ;
VAL_ 292 CENT_DIFF_ESP_RQ 3 "SNA" 2 "OPEN" 1 "HOLD" 0 "FREE" ;
VAL_ 292 R_DIFF_ESP_RQ 3 "SNA" 2 "OPEN" 1 "HOLD" 0 "FREE" ;
VAL_ 292 FT_DIFF_TRQ_RQ 255 "SNA" ;
VAL_ 292 CENT_DIFF_TRQ_RQ 255 "SNA" ;
VAL_ 292 R_DIFF_TRQ_RQ 255 "SNA" ;
VAL_ 294 LatAcceleration 4095 "SNA" ;
VAL_ 294 AXSStat 3 "SEII" 2 "PSE" 1 "TSE" 0 "SISL" ;
VAL_ 294 AYSStat 3 "SEII" 2 "PSE" 1 "TSE" 0 "SISL" ;
VAL_ 294 LongAcceleration 4095 "SNA" ;
VAL_ 294 YRSStat 3 "SEII" 2 "PSE" 1 "TSE" 0 "SISL" ;
VAL_ 294 YawRate 4095 "SNA" ;
VAL_ 300 EPS_AsstStat 7 "SNA" 2 "AST_RT" 1 "AST_OFF" 0 "AST_ACT" ;
VAL_ 300 EPS_Warn_Disp_Rq 7 "SNA" 3 "SERV_HI" 2 "ERR2" 1 "ERR" 0 "OK" ;
VAL_ 300 EPS_MODE_CFG_STAT 7 "SNA" 3 "LAST" 2 "MODE_3" 1 "MODE_2" 0 "MODE_1" ;
VAL_ 300 EPS_MODE_STAT 7 "SNA" 3 "LAST" 2 "MODE_3" 1 "MODE_2" 0 "MODE_1" ;
VAL_ 300 EPS_Curr 255 "SNA" ;
VAL_ 308 SpeedLimitSts 7 "SNA" 4 "OVER_SPEED" 3 "OVER" 2 "N_A" 1 "ACT" 0 "S_B" ;
VAL_ 308 CRUISE_EGD 0 "SNA" ;
VAL_ 308 CRUISE_ON 0 "SNA" ;
VAL_ 308 V_MAX_TM 255 "SNA" ;
VAL_ 308 MAP_ENG 255 "SNA" ;
VAL_ 308 BARO_ENG 255 "SNA" ;
VAL_ 308 Rel_Thrt_ENG 255 "SNA" ;
VAL_ 308 Rel_Pdl_ENG 255 "SNA" ;
VAL_ 308 BoostVacGauge 255 "SNA" ;
VAL_ 320 Brk_Stat 3 "SNA" 2 "NDEF2" 1 "BRAKING" 0 "IDLE" ;
VAL_ 320 BrkPdl_Stat 3 "SNA" 2 "NDEF2" 1 "PSD" 0 "UPSTOP" ;
VAL_ 320 ESP_Sys_Stat 3 "ABGAS" 2 "HALF" 1 "NORM" 0 "ABSERR" ;
VAL_ 320 SelSpdSts 3 "SNA" 2 "INHIBIT" 1 "SELECT" 0 "OFF" ;
VAL_ 320 DTR_CC_Engaged 0 "SNA" ;
VAL_ 320 GrMin_Rq_ESC 7 "G7" 6 "G6" 5 "G5" 4 "G4" 3 "G3" 2 "G2" 1 "G1" 0 "PASSIVE" ;
VAL_ 320 GrMax_Rq_ESC 7 "G7" 6 "G6" 5 "G5" 4 "G4" 3 "G3" 2 "G2" 1 "G1" 0 "PASSIVE" ;
VAL_ 320 DTR_CC_Enabled 0 "SNA" ;
VAL_ 320 ShftChrDsp_Rq_ESC 15 "SNA" 12 "SKL12" 11 "SKL11" 10 "SKL10" 9 "SKL9" 8 "SKL8" 7 "SKL7" 6 "SKL6" 5 "SKL5" 4 "SKL4" 3 "SKL3" 2 "SKL2" 1 "SKL1" 0 "SKL0" ;
VAL_ 320 RollTestMd_Actv 3 "SNA" 2 "NDEF2" 1 "ON" 0 "OFF" ;
VAL_ 320 REF_VEH_SPEED 1023 "SNA" ;
VAL_ 320 SPCR_AS_Off_Rq 3 "SPCR_NA" 2 "AS_CNTS_OFF" 1 "AS_TMP_OFF" 0 "IDLE" ;
VAL_ 324 Ups_Inh_Act 0 "SNA" ;
VAL_ 324 Gr 15 "SNA" 14 "KRAFTFREI" 13 "P" 12 "R2" 11 "R" 10 "D9" 9 "D2P" 8 "D8" 7 "D7" 6 "D6" 5 "D5" 4 "D4" 3 "D3" 2 "D2" 1 "D1" 0 "N" ;
VAL_ 324 Gr_Target 15 "SNA" 14 "ABBRUCH" 13 "P" 12 "R2" 11 "R" 10 "D9" 9 "D2P" 8 "D8" 7 "D7" 6 "D6" 5 "D5" 4 "D4" 3 "D3" 2 "D2" 1 "D1" 0 "N" ;
VAL_ 324 PTO_Enbl 0 "SNA" ;
VAL_ 324 OUTPUT_SPEED 65535 "SNA" ;
VAL_ 324 N_Turb 65535 "SNA" ;
VAL_ 324 OutputSpdPolarity 3 "SNA" 2 "DB" 1 "DF" 0 "DND" ;
VAL_ 328 WHC 15 "SNA" 14 "A" 13 "P_ZW_R" 12 "R_ZW_N" 11 "N_ZW_D" 10 "MINUS" 9 "PLUS" 8 "P" 7 "R" 6 "N" 5 "D" 4 "4" 3 "3" 2 "2" 1 "1" 0 "0" ;
VAL_ 329 Shft_Warn 7 "WARN_7" 6 "WARN_6" 5 "WARN_5" 4 "WARN_4" 3 "WARN_3" 2 "WARN_2" 1 "WARN_1" 0 "NONE" ;
VAL_ 331 BrkPrss_TMC 2047 "SNA" ;
VAL_ 331 EngSpdInterv 65535 "SNA" ;
VAL_ 331 HSA_BrkPrss 63 "SNA" ;
VAL_ 331 ESCSensorPlausFailSts 0 "SNA" ;
VAL_ 331 RBM_Act 0 "SNA" ;
VAL_ 332 VehYawRate_Raw 65535 "SNA" ;
VAL_ 332 VehYawRate_Offset 255 "SNA" ;
VAL_ 332 VehAccel_X_Offset 255 "SNA" ;
VAL_ 332 VehAccel_X 255 "SNA" ;
VAL_ 332 VehAccel_Y 255 "SNA" ;
VAL_ 332 VehAccel_Y_Offset 255 "SNA" ;
VAL_ 344 WhlRPM_FL 16383 "SNA" ;
VAL_ 344 WhlDir_FL_Stat 3 "SNA" 2 "BACKWARD" 1 "FORWARD" 0 "VOID" ;
VAL_ 344 WhlRPM_FR 16383 "SNA" ;
VAL_ 344 WhlDir_FR_Stat 3 "SNA" 2 "BACKWARD" 1 "FORWARD" 0 "VOID" ;
VAL_ 344 WhlRPM_RL 16383 "SNA" ;
VAL_ 344 WhlDir_RL_Stat 3 "SNA" 2 "BACKWARD" 1 "FORWARD" 0 "VOID" ;
VAL_ 344 WhlRPM_RR 16383 "SNA" ;
VAL_ 344 WhlDir_RR_Stat 3 "SNA" 2 "BACKWARD" 1 "FORWARD" 0 "VOID" ;
VAL_ 352 TCASE_STAT 7 "SNA" 6 "PT" 5 "AUTO" 4 "N" 3 "2WD" 2 "4HI" 1 "4LO" 0 "SH_IPG" ;
VAL_ 352 SHFT_ABRT 1 "SNA" ;
VAL_ 352 ACT_CNT_DIF_TRQ 255 "SNA" ;
VAL_ 352 ACT_R_DIF_TRQ 255 "SNA" ;
VAL_ 352 DES_CNT_DIF_TRQ 255 "SNA" ;
VAL_ 353 TC_TrqCltAct 2047 "SNA" ;
VAL_ 353 TC_FaultStat 15 "SNA" 7 "FAIL_PU" 6 "FAIL_CO" 5 "FAIL" 4 "T_FAIL" 3 "NORMAL" 2 "CAL" 1 "INIT" 0 "DEACT" ;
VAL_ 362 DrvLnTrqRq 511 "SNA" ;
